VERSION ""

NS_ :

BS_:

BU_: Turbocharger OnBoardDataLogger OffBoardDiagnosticTool2 OffBoardDiagnosticTool1 FileServer ParkingBrakeController SeatControl2 FanDriveController SteeringColumnUnit CommunicationUnitRadio CommunicationUnitSatellite CommunicationUnitCellular PropulsionBatteryCharger ChassisController2 ChassisController1 EngineValveControl AuxiliaryHeater2 AuxiliaryHeater1 ClutchUnit RampControl InformationSystem1 SuspensionSystemController2 OilSensor VehicleDynamicStability ExhaustEmissionController TransmissionDisplay2 TransmissionDisplay1 ClimateControl2 WaterPumpController RearAxleSteeringController LightingOperatorControl SeatController1 IgnitionController2 IgnitionController1 TirePressureController CabController2 CabController1 PneumaticSystemController SuspensionSystemController1 HydraulicPumpController EnduranceBrakingSystem RetarderExhaustEngine2 OnBoardDiagnosticUnit HeadwayController RetarderExhaustEngine1 CabDisplay1 ManagementComputer VirtualTerminal OffVehicleGateway PowerTakeOffFront HitchControl AuxiliaryValveControl BodyController TractorTrailerBridge1 StarterSystem ElectricalSystem VehicleSecurity VehicleNavigation AerodynamicControl ElectricalChargingSystem ClimateControl1 TripRecorder InstrumentCluster SuspensionDriveAxle2 SuspensionDriveAxle1 SuspensionSteerAxle SteeringController FuelSystem CruiseControl RetarderDriveline RetarderEngine BrakesDriveAxle2 BrakesDriveAxle1 BrakesSystemController BrakesSteerAxle AxleDrive2 AxleDrive1 AxleSteering PowerTakeOff ShiftConsoleSecondary ShiftConsolePrimary Transmission2 Transmission1 Engine2 Engine1

BO_ 2633895166 WSMEM: 8 Vector__XXX
 SG_ VehicleSystem5 m5 : 49|7@1+ (1,0) [0|127] "" Vector__XXX
 SG_ VehicleSystem4 m4 : 49|7@1+ (1,0) [0|127] "" Vector__XXX
 SG_ VehicleSystem3 m3 : 49|7@1+ (1,0) [0|127] "" Vector__XXX
 SG_ VehicleSystem2 m2 : 49|7@1+ (1,0) [0|127] "" Vector__XXX
 SG_ VehicleSystem1 m1 : 49|7@1+ (1,0) [0|127] "" Vector__XXX
 SG_ ArbitraryAddressCapable : 63|1@1+ (1,0) [0|1] "" Vector__XXX
 SG_ IndustryGroup M : 60|3@1+ (1,0) [0|7] "" Vector__XXX
 SG_ VehicleSystemInstance : 56|4@1+ (1,0) [0|15] "" Vector__XXX
 SG_ VehicleSystem m0 : 49|7@1+ (1,0) [0|127] "" Vector__XXX
 SG_ ECUInstance : 32|3@1+ (1,0) [0|7] "" Vector__XXX
 SG_ FunctionInstance : 35|5@1+ (1,0) [0|31] "" Vector__XXX
 SG_ Function : 40|8@1+ (1,0) [0|255] "" Vector__XXX
 SG_ ManufacturerCode : 21|11@1+ (1,0) [0|2047] "" Vector__XXX
 SG_ IdentityNumber : 0|21@1+ (1,0) [0|2097152] "" Vector__XXX

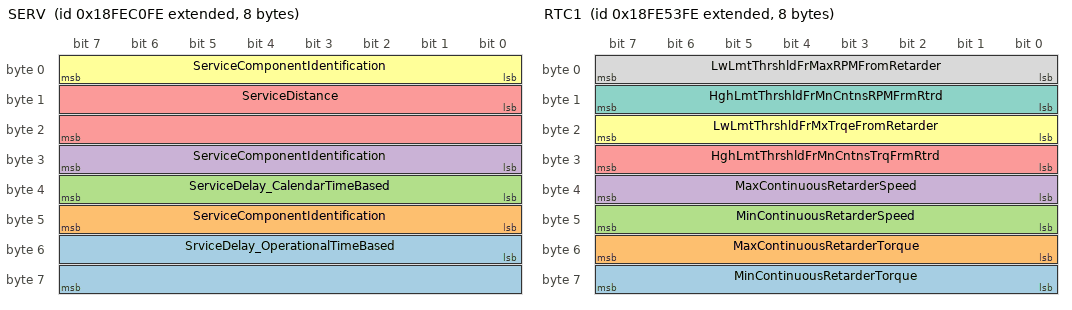
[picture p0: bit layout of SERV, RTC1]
BO_ 2566832382 SERV: 8 Vector__XXX
 SG_ SrviceDelay_OperationalTimeBased : 48|16@1+ (1,-32127) [-32127|32128] "hr" Vector__XXX
 SG_ ServiceComponentIdentification : 40|8@1+ (1,0) [0|250] "ID" Vector__XXX
 SG_ ServiceDelay_CalendarTimeBased : 32|8@1+ (1,-125) [-125|125] "weeks" Vector__XXX
 SG_ ServiceComponentIdentification : 24|8@1+ (1,0) [0|250] "ID" Vector__XXX
 SG_ ServiceDistance : 8|16@1+ (5,-160635) [-160635|160640] "km" Vector__XXX
 SG_ ServiceComponentIdentification : 0|8@1+ (1,0) [0|250] "ID" Vector__XXX

BO_ 2633928446 S2: 8 Vector__XXX
 SG_ TimeSinceLastService : 8|16@1+ (1,-32127) [-32127|32128] "hr" Vector__XXX
 SG_ ServiceComponentIdentification : 0|8@1+ (1,0) [0|250] "ID" Vector__XXX

BO_ 2566804478 RTC1: 8 Vector__XXX
 SG_ MinContinuousRetarderTorque : 56|8@1+ (1,-125) [-125|125] "%" Vector__XXX
 SG_ MaxContinuousRetarderTorque : 48|8@1+ (1,-125) [-125|125] "%" Vector__XXX
 SG_ MinContinuousRetarderSpeed : 40|8@1+ (1,0) [0|8000] "rpm" Vector__XXX
 SG_ MaxContinuousRetarderSpeed : 32|8@1+ (1,0) [0|8000] "rpm" Vector__XXX
 SG_ HghLmtThrshldFrMnCntnsTrqFrmRtrd : 24|8@1+ (1,-125) [-125|125] "%" Vector__XXX
 SG_ LwLmtThrshldFrMxTrqeFromRetarder : 16|8@1+ (1,-125) [-125|125] "%" Vector__XXX
 SG_ HghLmtThrshldFrMnCntnsRPMFrmRtrd : 8|8@1+ (1,0) [0|8000] "rpm" Vector__XXX
 SG_ LwLmtThrshldFrMaxRPMFromRetarder : 0|8@1+ (1,0) [0|8000] "rpm" Vector__XXX

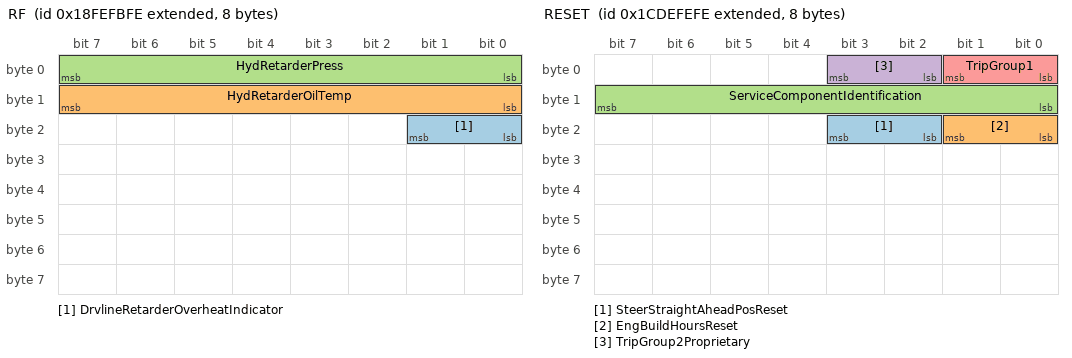
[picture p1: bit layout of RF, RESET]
BO_ 2566847486 RF: 8 Vector__XXX
 SG_ DrvlineRetarderOverheatIndicator : 16|2@1+ (1,0) [0|3] "" Vector__XXX
 SG_ HydRetarderOilTemp : 8|8@1+ (1,-40) [-40|210] "deg C" Vector__XXX
 SG_ HydRetarderPress : 0|8@1+ (16,0) [0|4000] "kPa" Vector__XXX

BO_ 2631859966 RESET: 8 Vector__XXX
 SG_ SteerStraightAheadPosReset : 18|2@1+ (1,0) [0|3] "" Vector__XXX
 SG_ EngBuildHoursReset : 16|2@1+ (1,0) [0|3] "" Vector__XXX
 SG_ ServiceComponentIdentification : 8|8@1+ (1,0) [0|250] "ID" Vector__XXX
 SG_ TripGroup2Proprietary : 2|2@1+ (1,0) [0|3] "" Vector__XXX
 SG_ TripGroup1 : 0|2@1+ (1,0) [0|3] "" Vector__XXX

BO_ 2566840830 RC: 19 Vector__XXX
 SG_ PercentTorqueAtPeakTorquePoint5 : 144|8@1+ (1,-125) [-125|125] "%" Vector__XXX
 SG_ ReferenceRetarderTorque : 128|16@1+ (1,0) [0|64255] "Nm" Vector__XXX
 SG_ RetarderSpeedAtPeakTorquePoint5 : 112|16@1+ (0.125,0) [0|8031.875] "rpm" Vector__XXX
 SG_ PercentTorqueAtPoint4 : 104|8@1+ (1,-125) [-125|125] "%" Vector__XXX
 SG_ RetarderSpeedAtPoint4 : 88|16@1+ (0.125,0) [0|8031.875] "rpm" Vector__XXX
 SG_ PercentTorqueAtPoint3 : 80|8@1+ (1,-125) [-125|125] "%" Vector__XXX
 SG_ RetarderSpeedAtPoint3 : 64|16@1+ (0.125,0) [0|8031.875] "rpm" Vector__XXX
 SG_ PercentTorqueAtMaxSpeedPoint2 : 56|8@1+ (1,-125) [-125|125] "%" Vector__XXX
 SG_ MaxRetarderSpeedPoint2 : 40|16@1+ (0.125,0) [0|8031.875] "rpm" Vector__XXX
 SG_ PercentTorqueAtIdlePoint1 : 32|8@1+ (1,-125) [-125|125] "%" Vector__XXX
 SG_ RetarderSpeedAtIdlePoint1 : 16|16@1+ (0.125,0) [0|8031.875] "rpm" Vector__XXX
 SG_ RetarderCtrlMethod : 8|8@1+ (1,0) [0|250] "steps" Vector__XXX
 SG_ RetarderLocation : 4|4@1+ (1,0) [0|15] "" Vector__XXX
 SG_ RetarderType : 0|4@1+ (1,0) [0|15] "" Vector__XXX

BO_ 2633930238 RBI: 8 Vector__XXX
 SG_ EngOperationTimeSinceRebuild : 0|32@1+ (1,0) [0|4211081215] "s" Vector__XXX

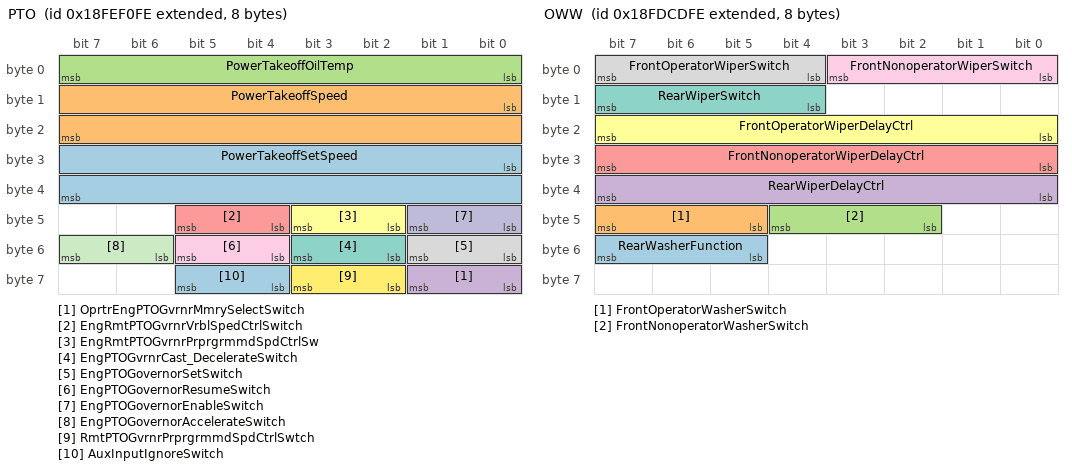
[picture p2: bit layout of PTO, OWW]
BO_ 2566844670 PTO: 8 Vector__XXX
 SG_ PowerTakeoffSetSpeed : 24|16@1+ (0.125,0) [0|8031.875] "rpm" Vector__XXX
 SG_ PowerTakeoffSpeed : 8|16@1+ (0.125,0) [0|8031.875] "rpm" Vector__XXX
 SG_ PowerTakeoffOilTemp : 0|8@1+ (1,-40) [-40|210] "deg C" Vector__XXX
 SG_ OprtrEngPTOGvrnrMmrySelectSwitch : 56|2@1+ (1,0) [0|3] "" Vector__XXX
 SG_ EngRmtPTOGvrnrVrblSpedCtrlSwitch : 44|2@1+ (1,0) [0|3] "" Vector__XXX
 SG_ EngRmtPTOGvrnrPrprgrmmdSpdCtrlSw : 42|2@1+ (1,0) [0|3] "" Vector__XXX
 SG_ EngPTOGvrnrCast_DecelerateSwitch : 50|2@1+ (1,0) [0|3] "" Vector__XXX
 SG_ EngPTOGovernorSetSwitch : 48|2@1+ (1,0) [0|3] "" Vector__XXX
 SG_ EngPTOGovernorResumeSwitch : 52|2@1+ (1,0) [0|3] "" Vector__XXX
 SG_ EngPTOGovernorEnableSwitch : 40|2@1+ (1,0) [0|3] "" Vector__XXX
 SG_ EngPTOGovernorAccelerateSwitch : 54|2@1+ (1,0) [0|3] "" Vector__XXX
 SG_ RmtPTOGvrnrPrprgrmmdSpdCtrlSwtch : 58|2@1+ (1,0) [0|3] "" Vector__XXX
 SG_ AuxInputIgnoreSwitch : 60|2@1+ (1,0) [0|3] "" Vector__XXX

BO_ 2566770174 OWW: 8 Vector__XXX
 SG_ RearWasherFunction : 53|3@1+ (1,0) [0|7] "" Vector__XXX
 SG_ FrontOperatorWasherSwitch : 45|3@1+ (1,0) [0|7] "" Vector__XXX
 SG_ FrontNonoperatorWasherSwitch : 42|3@1+ (1,0) [0|7] "" Vector__XXX
 SG_ RearWiperDelayCtrl : 32|8@1+ (0.4,0) [0|100] "%" Vector__XXX
 SG_ FrontNonoperatorWiperDelayCtrl : 24|8@1+ (0.4,0) [0|100] "%" Vector__XXX
 SG_ FrontOperatorWiperDelayCtrl : 16|8@1+ (0.4,0) [0|100] "%" Vector__XXX
 SG_ RearWiperSwitch : 12|4@1+ (1,0) [0|15] "" Vector__XXX
 SG_ FrontOperatorWiperSwitch : 4|4@1+ (1,0) [0|15] "" Vector__XXX
 SG_ FrontNonoperatorWiperSwitch : 0|4@1+ (1,0) [0|15] "" Vector__XXX

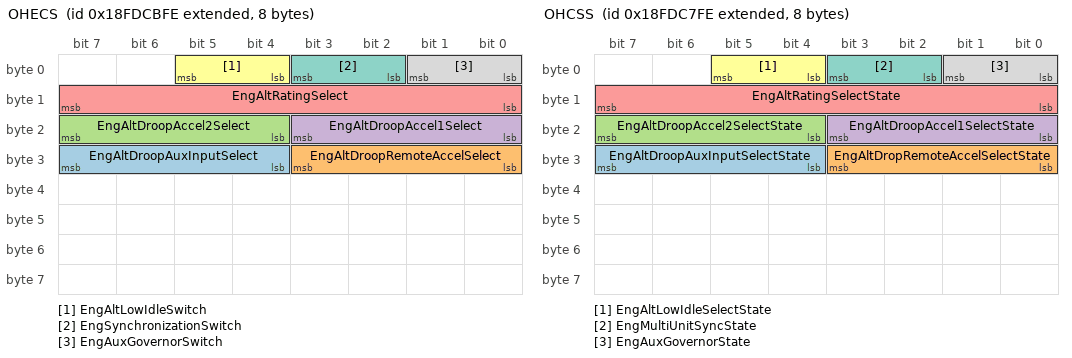
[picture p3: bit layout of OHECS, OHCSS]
BO_ 2566769662 OHECS: 8 Vector__XXX
 SG_ EngAltDroopAuxInputSelect : 28|4@1+ (1,0) [0|15] "" Vector__XXX
 SG_ EngAltDroopRemoteAccelSelect : 24|4@1+ (1,0) [0|15] "" Vector__XXX
 SG_ EngAltDroopAccel2Select : 20|4@1+ (1,0) [0|15] "" Vector__XXX
 SG_ EngAltDroopAccel1Select : 16|4@1+ (1,0) [0|15] "" Vector__XXX
 SG_ EngAltRatingSelect : 8|8@1+ (1.02,0) [0|255] "" Vector__XXX
 SG_ EngAltLowIdleSwitch : 4|2@1+ (1,0) [0|3] "" Vector__XXX
 SG_ EngSynchronizationSwitch : 2|2@1+ (1,0) [0|3] "" Vector__XXX
 SG_ EngAuxGovernorSwitch : 0|2@1+ (1,0) [0|3] "" Vector__XXX

BO_ 2566768638 OHCSS: 8 Vector__XXX
 SG_ EngAltDroopAuxInputSelectState : 28|4@1+ (1,0) [0|15] "" Vector__XXX
 SG_ EngAltDropRemoteAccelSelectState : 24|4@1+ (1,0) [0|15] "" Vector__XXX
 SG_ EngAltDroopAccel2SelectState : 20|4@1+ (1,0) [0|15] "" Vector__XXX
 SG_ EngAltDroopAccel1SelectState : 16|4@1+ (1,0) [0|15] "" Vector__XXX
 SG_ EngAltRatingSelectState : 8|8@1+ (1,0) [0|255] "" Vector__XXX
 SG_ EngAltLowIdleSelectState : 4|2@1+ (1,0) [0|3] "" Vector__XXX
 SG_ EngMultiUnitSyncState : 2|2@1+ (1,0) [0|3] "" Vector__XXX
 SG_ EngAuxGovernorState : 0|2@1+ (1,0) [0|3] "" Vector__XXX

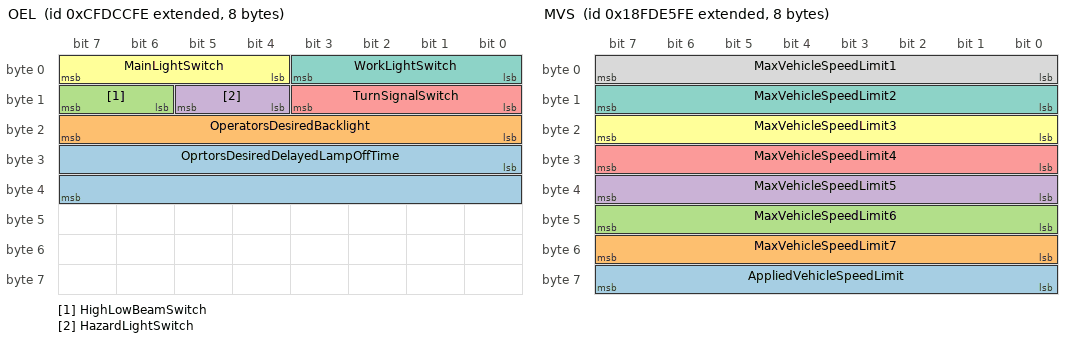
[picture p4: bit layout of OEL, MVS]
BO_ 2365443326 OEL: 8 Vector__XXX
 SG_ OprtorsDesiredDelayedLampOffTime : 24|16@1+ (1,0) [0|64255] "s" Vector__XXX
 SG_ OperatorsDesiredBacklight : 16|8@1+ (0.4,0) [0|100] "%" Vector__XXX
 SG_ HighLowBeamSwitch : 14|2@1+ (1,0) [0|3] "" Vector__XXX
 SG_ HazardLightSwitch : 12|2@1+ (1,0) [0|3] "" Vector__XXX
 SG_ TurnSignalSwitch : 8|4@1+ (1,0) [0|15] "" Vector__XXX
 SG_ MainLightSwitch : 4|4@1+ (1,0) [0|15] "" Vector__XXX
 SG_ WorkLightSwitch : 0|4@1+ (1,0) [0|15] "" Vector__XXX

BO_ 2566776318 MVS: 8 Vector__XXX
 SG_ AppliedVehicleSpeedLimit : 56|8@1+ (1,0) [0|250] "km/h" Vector__XXX
 SG_ MaxVehicleSpeedLimit7 : 48|8@1+ (1,0) [0|250] "km/h" Vector__XXX
 SG_ MaxVehicleSpeedLimit6 : 40|8@1+ (1,0) [0|250] "km/h" Vector__XXX
 SG_ MaxVehicleSpeedLimit5 : 32|8@1+ (1,0) [0|250] "km/h" Vector__XXX
 SG_ MaxVehicleSpeedLimit4 : 24|8@1+ (1,0) [0|250] "km/h" Vector__XXX
 SG_ MaxVehicleSpeedLimit3 : 16|8@1+ (1,0) [0|250] "km/h" Vector__XXX
 SG_ MaxVehicleSpeedLimit2 : 8|8@1+ (1,0) [0|250] "km/h" Vector__XXX
 SG_ MaxVehicleSpeedLimit1 : 0|8@1+ (1,0) [0|250] "km/h" Vector__XXX

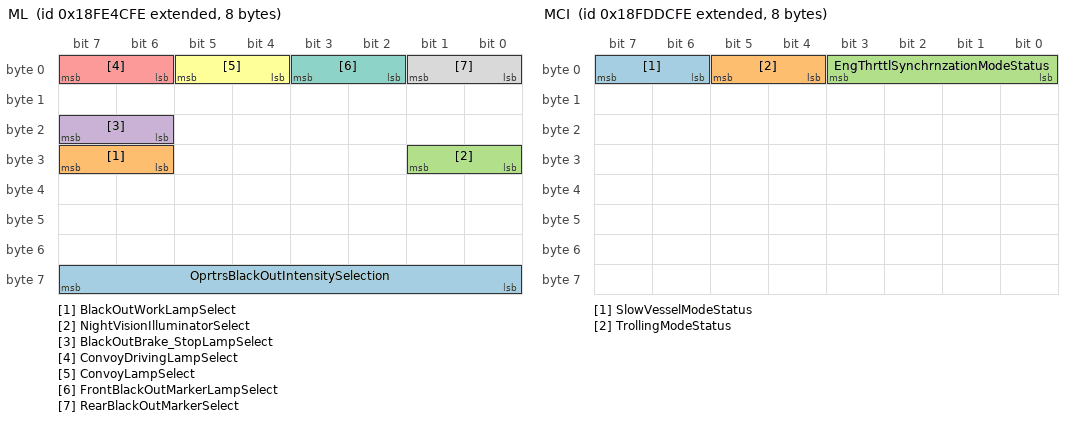
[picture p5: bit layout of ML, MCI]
BO_ 2566802686 ML: 8 Vector__XXX
 SG_ OprtrsBlackOutIntensitySelection : 56|8@1+ (1,0) [0|100] "%" Vector__XXX
 SG_ BlackOutWorkLampSelect : 30|2@1+ (1,0) [0|3] "" Vector__XXX
 SG_ NightVisionIlluminatorSelect : 24|2@1+ (1,0) [0|3] "" Vector__XXX
 SG_ BlackOutBrake_StopLampSelect : 22|2@1+ (1,0) [0|3] "" Vector__XXX
 SG_ ConvoyDrivingLampSelect : 6|2@1+ (1,0) [0|3] "" Vector__XXX
 SG_ ConvoyLampSelect : 4|2@1+ (1,0) [0|3] "" Vector__XXX
 SG_ FrontBlackOutMarkerLampSelect : 2|2@1+ (1,0) [0|3] "" Vector__XXX
 SG_ RearBlackOutMarkerSelect : 0|2@1+ (1,0) [0|3] "" Vector__XXX

BO_ 2566774014 MCI: 8 Vector__XXX
 SG_ SlowVesselModeStatus : 6|2@1+ (1,0) [0|3] "" Vector__XXX
 SG_ TrollingModeStatus : 4|2@1+ (1,0) [0|3] "" Vector__XXX
 SG_ EngThrttlSynchrnzationModeStatus : 0|4@1+ (1,0) [0|15] "" Vector__XXX

BO_ 2566823166 MBT3: 8 Vector__XXX
 SG_ EngMainBearing11Temp : 32|16@1+ (0.03125,-273) [-273|1734.96875] "deg C" Vector__XXX
 SG_ EngMainBearing10Temp : 16|16@1+ (0.03125,-273) [-273|1734.96875] "deg C" Vector__XXX
 SG_ EngMainBearing9Temp : 0|16@1+ (0.03125,-273) [-273|1734.96875] "deg C" Vector__XXX

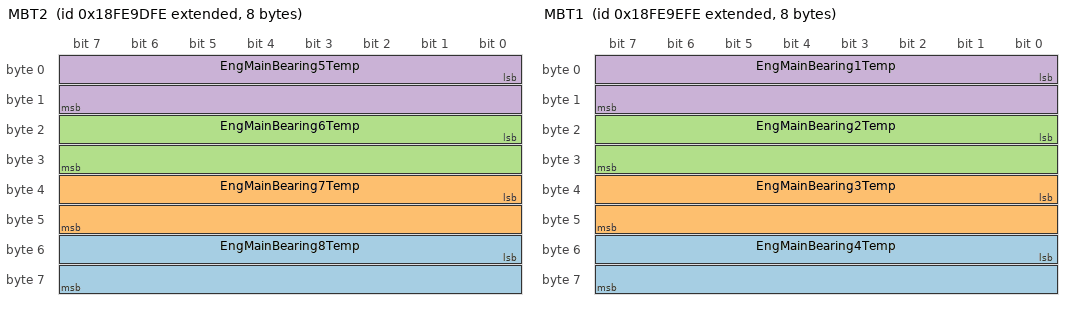
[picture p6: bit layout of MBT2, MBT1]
BO_ 2566823422 MBT2: 8 Vector__XXX
 SG_ EngMainBearing8Temp : 48|16@1+ (0.03125,-273) [-273|1734.96875] "deg C" Vector__XXX
 SG_ EngMainBearing7Temp : 32|16@1+ (0.03125,-273) [-273|1734.96875] "deg C" Vector__XXX
 SG_ EngMainBearing6Temp : 16|16@1+ (0.03125,-273) [-273|1734.96875] "deg C" Vector__XXX
 SG_ EngMainBearing5Temp : 0|16@1+ (0.03125,-273) [-273|1734.96875] "deg C" Vector__XXX

BO_ 2566823678 MBT1: 8 Vector__XXX
 SG_ EngMainBearing4Temp : 48|16@1+ (0.03125,-273) [-273|1734.96875] "deg C" Vector__XXX
 SG_ EngMainBearing3Temp : 32|16@1+ (0.03125,-273) [-273|1734.96875] "deg C" Vector__XXX
 SG_ EngMainBearing2Temp : 16|16@1+ (0.03125,-273) [-273|1734.96875] "deg C" Vector__XXX
 SG_ EngMainBearing1Temp : 0|16@1+ (0.03125,-273) [-273|1734.96875] "deg C" Vector__XXX

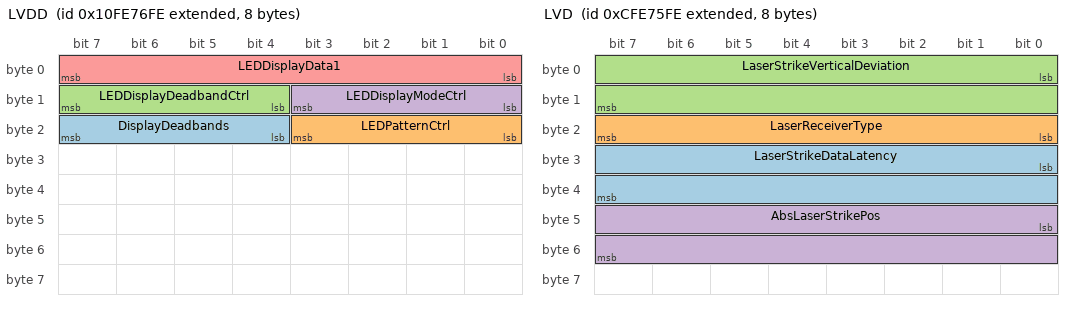
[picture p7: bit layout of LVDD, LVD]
BO_ 2432595710 LVDD: 8 Vector__XXX
 SG_ DisplayDeadbands : 20|4@1+ (1,0) [0|15] "" Vector__XXX
 SG_ LEDPatternCtrl : 16|4@1+ (1,0) [0|15] "" Vector__XXX
 SG_ LEDDisplayDeadbandCtrl : 12|4@1+ (1,0) [0|15] "" Vector__XXX
 SG_ LEDDisplayModeCtrl : 8|4@1+ (1,0) [0|15] "" Vector__XXX
 SG_ LEDDisplayData1 : 0|8@1+ (1,0) [0|255] "" Vector__XXX

BO_ 2365486590 LVD: 8 Vector__XXX
 SG_ LaserStrikeDataLatency : 24|16@1+ (5.12E-005,0) [0|3.289856] "s" Vector__XXX
 SG_ LaserReceiverType : 16|8@1+ (1,0) [0|250] "" Vector__XXX
 SG_ LaserStrikeVerticalDeviation : 0|16@1+ (0.1,-3200) [-3200|3225.5] "mm" Vector__XXX
 SG_ AbsLaserStrikePos : 40|16@1+ (0.1,0) [0|6425.5] "mm" Vector__XXX

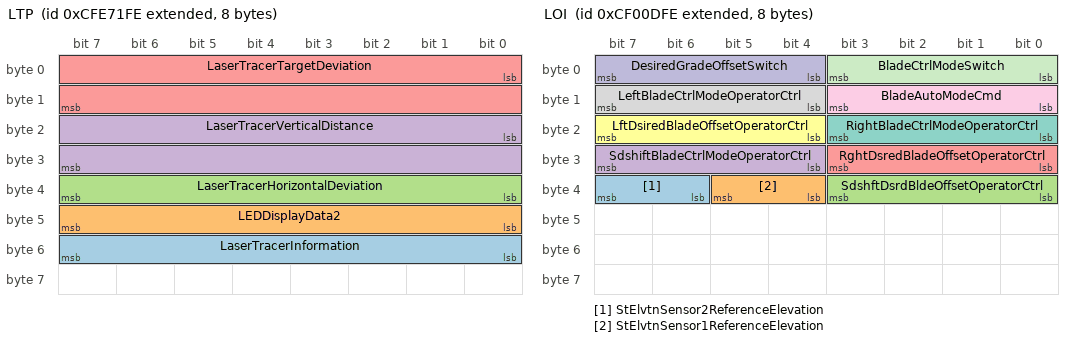
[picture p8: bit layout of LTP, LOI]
BO_ 2365485566 LTP: 8 Vector__XXX
 SG_ LaserTracerInformation : 48|8@1+ (1,0) [0|255] "" Vector__XXX
 SG_ LEDDisplayData2 : 40|8@1+ (1,0) [0|255] "" Vector__XXX
 SG_ LaserTracerHorizontalDeviation : 32|8@1+ (1,0) [0|250] "%" Vector__XXX
 SG_ LaserTracerVerticalDistance : 16|16@1+ (0.1,0) [0|6425.5] "mm" Vector__XXX
 SG_ LaserTracerTargetDeviation : 0|16@1+ (0.1,-3200) [-3200|3225.5] "mm" Vector__XXX

BO_ 2633939454 LTFI: 22 Vector__XXX
 SG_ TripCruiseFuelUsed : 128|32@1+ (0.5,0) [0|2105540607.5] "L" Vector__XXX
 SG_ TripVehicleIdleFuelUsed : 96|32@1+ (0.5,0) [0|2105540607.5] "L" Vector__XXX
 SG_ TripDriveFuelUsed : 0|32@1+ (0.5,0) [0|2105540607.5] "L" Vector__XXX
 SG_ TripPTOGovernorNonmovingFuelUsed : 64|32@1+ (0.5,0) [0|2105540607.5] "L" Vector__XXX
 SG_ TripPTOGovernorMovingFuelUsed : 32|32@1+ (0.5,0) [0|2105540607.5] "L" Vector__XXX
 SG_ TripDriveFuelEconomy : 160|16@1+ (0.0019531553964672,0) [0|125.5] "km/L" Vector__XXX

BO_ 2365486334 LSP: 8 Vector__XXX
 SG_ BldeHeightSetPointHighResolution : 16|32@1+ (1E-007,-209.7152) [-209.7152|211.3929215] "m" Vector__XXX
 SG_ ModifyLevelingSystemSetPoint : 0|16@1+ (0.1,-3200) [-3200|3225.5] "mm" Vector__XXX

BO_ 2364542462 LOI: 8 Vector__XXX
 SG_ StElvtnSensor2ReferenceElevation : 38|2@1+ (1,0) [0|3] "" Vector__XXX
 SG_ StElvtnSensor1ReferenceElevation : 36|2@1+ (1,0) [0|3] "" Vector__XXX
 SG_ SdshftDsrdBldeOffsetOperatorCtrl : 32|4@1+ (1,0) [0|15] "" Vector__XXX
 SG_ SdshiftBladeCtrlModeOperatorCtrl : 28|4@1+ (1,0) [0|15] "" Vector__XXX
 SG_ RghtDsredBladeOffsetOperatorCtrl : 24|4@1+ (1,0) [0|15] "" Vector__XXX
 SG_ LftDsiredBladeOffsetOperatorCtrl : 20|4@1+ (1,0) [0|15] "" Vector__XXX
 SG_ RightBladeCtrlModeOperatorCtrl : 16|4@1+ (1,0) [0|15] "" Vector__XXX
 SG_ LeftBladeCtrlModeOperatorCtrl : 12|4@1+ (1,0) [0|15] "" Vector__XXX
 SG_ BladeAutoModeCmd : 8|4@1+ (1,0) [0|15] "" Vector__XXX
 SG_ DesiredGradeOffsetSwitch : 4|4@1+ (1,0) [0|15] "" Vector__XXX
 SG_ BladeCtrlModeSwitch : 0|4@1+ (1,0) [0|0] "" Vector__XXX

BO_ 2365486078 LMP: 8 Vector__XXX
 SG_ MastPos : 0|16@1+ (0.1,-3200) [-3200|3225.5] "mm" Vector__XXX

BO_ 2633937918 LFI: 8 Vector__XXX
 SG_ FlexibleFuelPercentage : 48|10@1+ (1,0) [0|102] "%" Vector__XXX
 SG_ TripAverageFuelRate : 32|16@1+ (0.05,0) [0|3212.75] "L/h" Vector__XXX
 SG_ TotalEngPTOGovernorFuelUsed : 0|32@1+ (0.5,0) [0|2105540607.5] "L" Vector__XXX

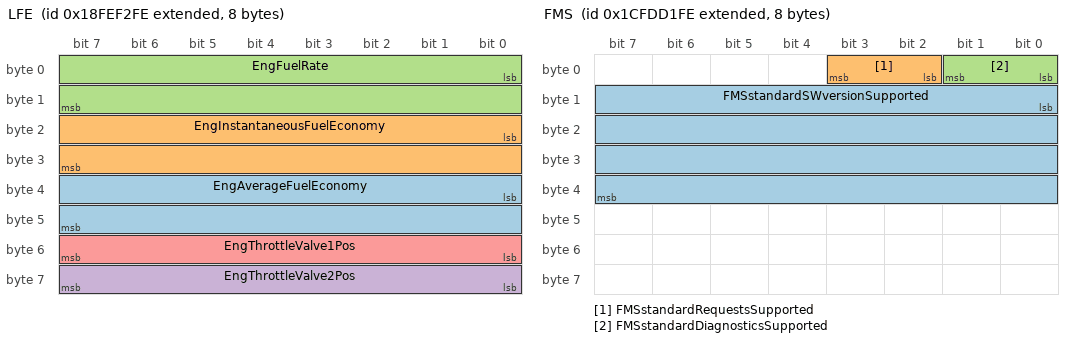
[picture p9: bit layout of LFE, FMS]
BO_ 2566845182 LFE: 8 Vector__XXX
 SG_ EngAverageFuelEconomy : 32|16@1+ (0.0019531553964672,0) [0|125.5] "km/L" Vector__XXX
 SG_ EngInstantaneousFuelEconomy : 16|16@1+ (0.0019531553964672,0) [0|125.5] "km/L" Vector__XXX
 SG_ EngFuelRate : 0|16@1+ (0.05,0) [0|3212.75] "L/h" Vector__XXX
 SG_ EngThrottleValve2Pos : 56|8@1+ (0.4,0) [0|100] "%" Vector__XXX
 SG_ EngThrottleValve1Pos : 48|8@1+ (0.4,0) [0|100] "%" Vector__XXX

BO_ 2566842878 LFC: 8 Vector__XXX
 SG_ EngTotalFuelUsed : 32|32@1+ (0.5,0) [0|2105540607.5] "L" Vector__XXX
 SG_ EngTripFuel : 0|32@1+ (0.5,0) [0|2105540607.5] "L" Vector__XXX

BO_ 2633883646 FWD: 8 Vector__XXX
 SG_ FrontWheelDriveActuatorStatus : 0|2@1+ (1,0) [0|3] "" Vector__XXX

BO_ 2633880062 FMS: 8 Vector__XXX
 SG_ FMSstandardSWversionSupported : 8|32@1+ (6.0554519606908E-008,0) [0|255] "per byte" Vector__XXX
 SG_ FMSstandardRequestsSupported : 2|2@1+ (1,0) [0|3] "" Vector__XXX
 SG_ FMSstandardDiagnosticsSupported : 0|2@1+ (1,0) [0|3] "" Vector__XXX

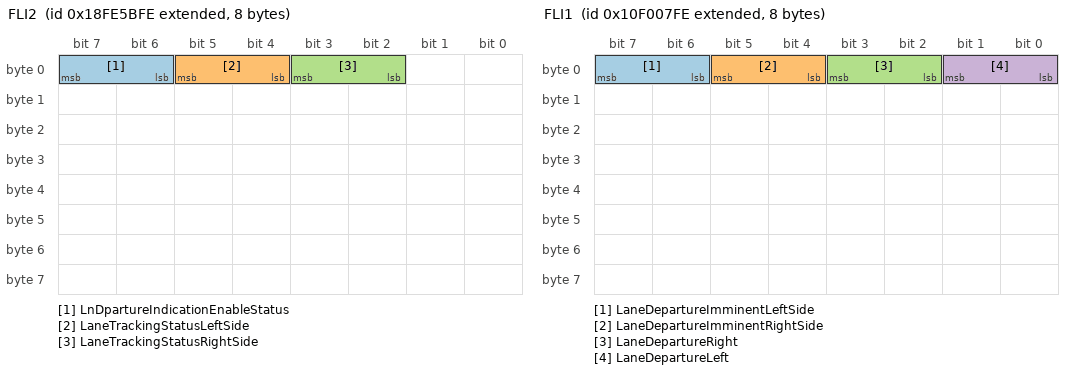
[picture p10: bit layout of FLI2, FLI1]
BO_ 2566806526 FLI2: 8 Vector__XXX
 SG_ LnDpartureIndicationEnableStatus : 6|2@1+ (1,0) [0|3] "" Vector__XXX
 SG_ LaneTrackingStatusLeftSide : 4|2@1+ (1,0) [0|3] "" Vector__XXX
 SG_ LaneTrackingStatusRightSide : 2|2@1+ (1,0) [0|3] "" Vector__XXX

BO_ 2431649790 FLI1: 8 Vector__XXX
 SG_ LaneDepartureImminentLeftSide : 6|2@1+ (1,0) [0|3] "" Vector__XXX
 SG_ LaneDepartureImminentRightSide : 4|2@1+ (1,0) [0|3] "" Vector__XXX
 SG_ LaneDepartureRight : 2|2@1+ (1,0) [0|3] "" Vector__XXX
 SG_ LaneDepartureLeft : 0|2@1+ (1,0) [0|3] "" Vector__XXX

BO_ 2633929214 FL: 8 Vector__XXX
 SG_ EngFuelLeakage2 : 2|2@1+ (1,0) [0|3] "" Vector__XXX
 SG_ EngFuelLeakage1 : 0|2@1+ (1,0) [0|3] "" Vector__XXX

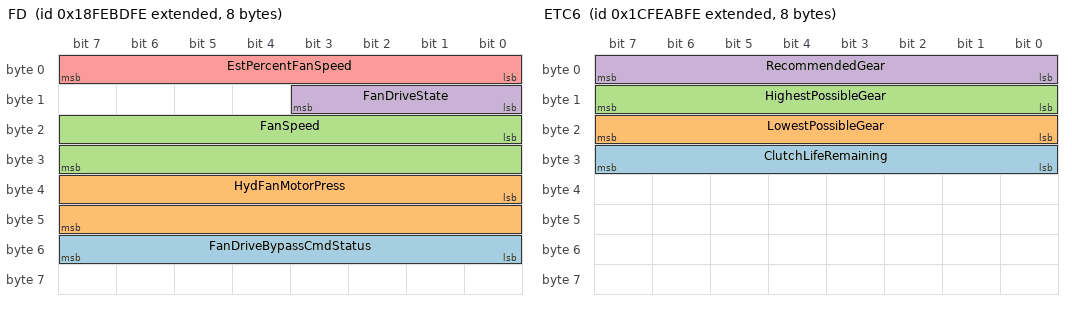
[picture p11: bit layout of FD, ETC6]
BO_ 2566831614 FD: 8 Vector__XXX
 SG_ FanDriveBypassCmdStatus : 48|8@1+ (1,0) [0|100] "%" Vector__XXX
 SG_ HydFanMotorPress : 32|16@1+ (0.5,0) [0|32127.5] "kPa" Vector__XXX
 SG_ FanSpeed : 16|16@1+ (0.125,0) [0|8031.875] "rpm" Vector__XXX
 SG_ FanDriveState : 8|4@1+ (1,0) [0|15] "" Vector__XXX
 SG_ EstPercentFanSpeed : 0|8@1+ (1,0) [0|100] "%" Vector__XXX

BO_ 2566820094 ETH: 33 Vector__XXX
 SG_ EngTorqueLimit6AxleInput : 248|16@1+ (2,0) [0|128510] "Nm" Vector__XXX
 SG_ EngTorqueLimit5Switch : 232|16@1+ (1,0) [0|64255] "Nm" Vector__XXX
 SG_ EngTorqueLimit4Trans : 216|16@1+ (1,0) [0|64255] "Nm" Vector__XXX
 SG_ EngTorqueLimit3Trans : 200|16@1+ (1,0) [0|64255] "Nm" Vector__XXX
 SG_ TransGearRatio3 : 184|16@1+ (0.01,0) [0|642.55] "" Vector__XXX
 SG_ EngTorqueLimit2Trans : 168|16@1+ (1,0) [0|64255] "Nm" Vector__XXX
 SG_ TransGearRatio2 : 152|16@1+ (0.01,0) [0|642.55] "" Vector__XXX
 SG_ EngTorqueLimit1Trans : 136|16@1+ (1,0) [0|64255] "Nm" Vector__XXX
 SG_ TransGearRatio1 : 120|16@1+ (0.01,0) [0|642.55] "" Vector__XXX
 SG_ EngTorqueLimitFeature : 114|3@1+ (1,0) [0|7] "" Vector__XXX
 SG_ TorqueLimitingFeatureStatus : 112|2@1+ (1,0) [0|3] "" Vector__XXX
 SG_ CalibRecordDurationTime : 80|32@1+ (0.05,0) [0|210554060.75] "hr" Vector__XXX
 SG_ CalibRecordStartYear : 72|8@1+ (1,1985) [1985|2235] "years" Vector__XXX
 SG_ CalibRecordStartDay : 64|8@1+ (0.25,0) [0|62.5] "days" Vector__XXX
 SG_ CalibRecordStartMonth : 56|8@1+ (1,0) [0|250] "months" Vector__XXX
 SG_ EngPeakTorque2 : 40|16@1+ (1,0) [0|64255] "Nm" Vector__XXX
 SG_ EngPeakTorque1 : 24|16@1+ (1,0) [0|64255] "Nm" Vector__XXX
 SG_ EngPower : 8|16@1+ (0.5,0) [0|32127.5] "kW" Vector__XXX
 SG_ NumberOfEngTorqueHistoryRecords : 0|8@1+ (1,0) [0|250] "records" Vector__XXX

BO_ 2364542206 ETC8: 8 Vector__XXX
 SG_ TransClutch_ConverterInputSpeed : 16|16@1+ (0.125,0) [0|8031.875] "rpm" Vector__XXX
 SG_ TransTorqueConverterRatio : 0|16@1+ (0.001,0) [0|64.255] "" Vector__XXX

BO_ 2566802174 ETC7: 8 Vector__XXX
 SG_ TrnsRverseGearShiftInhibitStatus : 40|2@1+ (1,0) [0|3] "" Vector__XXX
 SG_ TrnsCrrentRangeDisplayBlankState : 0|2@1+ (1,0) [0|3] "" Vector__XXX
 SG_ TransWarningIndicator : 42|2@1+ (1,0) [0|3] "" Vector__XXX
 SG_ TransMode8Indicator : 38|2@1+ (1,0) [0|3] "" Vector__XXX
 SG_ TransMode7Indicator : 36|2@1+ (1,0) [0|3] "" Vector__XXX
 SG_ TransMode6Indicator : 34|2@1+ (1,0) [0|3] "" Vector__XXX
 SG_ TransMode5Indicator : 32|2@1+ (1,0) [0|3] "" Vector__XXX
 SG_ TransRequestedGearFeedback : 24|8@1+ (1,-125) [-125|125] "" Vector__XXX
 SG_ TransMode1Indicator : 22|2@1+ (1,0) [0|3] "" Vector__XXX
 SG_ TransMode2Indicator : 20|2@1+ (1,0) [0|3] "" Vector__XXX
 SG_ TransMode3Indicator : 18|2@1+ (1,0) [0|3] "" Vector__XXX
 SG_ TransMode4Indicator : 16|2@1+ (1,0) [0|3] "" Vector__XXX
 SG_ TransShiftInhibitIndicator : 14|2@1+ (1,0) [0|3] "" Vector__XXX
 SG_ TransEngCrankEnable : 12|2@1+ (1,0) [0|3] "" Vector__XXX
 SG_ ActiveShiftConsoleIndicator : 10|2@1+ (1,0) [0|3] "" Vector__XXX
 SG_ TransReadyForBrakeRelease : 8|2@1+ (1,0) [0|3] "" Vector__XXX
 SG_ TrnsRqstedRangeDisplayFlashState : 6|2@1+ (1,0) [0|3] "" Vector__XXX
 SG_ TrnsRqstedRangeDisplayBlankState : 4|2@1+ (1,0) [0|3] "" Vector__XXX
 SG_ TransServiceIndicator : 2|2@1+ (1,0) [0|3] "" Vector__XXX

BO_ 2633935870 ETC6: 8 Vector__XXX
 SG_ ClutchLifeRemaining : 24|8@1+ (0.4,0) [0|100] "%" Vector__XXX
 SG_ LowestPossibleGear : 16|8@1+ (1,-125) [-125|125] "" Vector__XXX
 SG_ HighestPossibleGear : 8|8@1+ (1,-125) [-125|125] "" Vector__XXX
 SG_ RecommendedGear : 0|8@1+ (1,-125) [-125|125] "" Vector__XXX

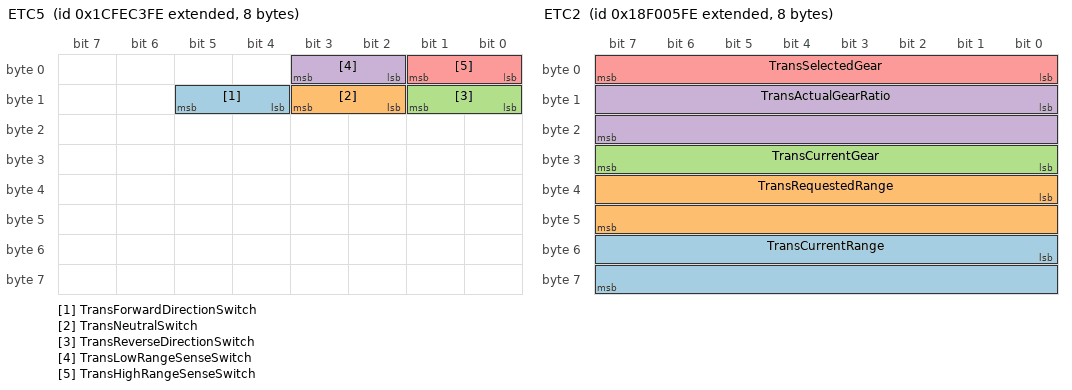
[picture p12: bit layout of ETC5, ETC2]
BO_ 2633942014 ETC5: 8 Vector__XXX
 SG_ TransForwardDirectionSwitch : 12|2@1+ (1,0) [0|3] "" Vector__XXX
 SG_ TransNeutralSwitch : 10|2@1+ (1,0) [0|3] "" Vector__XXX
 SG_ TransReverseDirectionSwitch : 8|2@1+ (1,0) [0|3] "" Vector__XXX
 SG_ TransLowRangeSenseSwitch : 2|2@1+ (1,0) [0|3] "" Vector__XXX
 SG_ TransHighRangeSenseSwitch : 0|2@1+ (1,0) [0|3] "" Vector__XXX

BO_ 2633942526 ETC4: 8 Vector__XXX
 SG_ TransSynchronizerBrakeValue : 8|8@1+ (0.4,0) [0|100] "%" Vector__XXX
 SG_ TransSynchronizerClutchValue : 0|8@1+ (0.4,0) [0|100] "%" Vector__XXX

BO_ 2633943038 ETC3: 8 Vector__XXX
 SG_ TransInertiaBrakeActuator : 46|2@1+ (1,0) [0|3] "" Vector__XXX
 SG_ TransDefuelActuator : 44|2@1+ (1,0) [0|3] "" Vector__XXX
 SG_ TransLockupClutchActuator : 42|2@1+ (1,0) [0|3] "" Vector__XXX
 SG_ TransClutchActuator : 40|2@1+ (1,0) [0|3] "" Vector__XXX
 SG_ TransSplitterIndirectActuator : 38|2@1+ (1,0) [0|3] "" Vector__XXX
 SG_ TransSplitterDirectActuator : 36|2@1+ (1,0) [0|3] "" Vector__XXX
 SG_ TransRangeLowActuator : 34|2@1+ (1,0) [0|3] "" Vector__XXX
 SG_ TransRangeHighActuator : 32|2@1+ (1,0) [0|3] "" Vector__XXX
 SG_ TransShiftFingerGearActuator2 : 30|2@1+ (1,0) [0|3] "" Vector__XXX
 SG_ TransShiftFingerRailActuator2 : 28|2@1+ (1,0) [0|3] "" Vector__XXX
 SG_ TransShiftFingerGearActuator1 : 26|2@1+ (1,0) [0|3] "" Vector__XXX
 SG_ TransShiftFingerRailActuator1 : 24|2@1+ (1,0) [0|3] "" Vector__XXX
 SG_ TrnsShftFngerCenterRailIndicator : 20|2@1+ (1,0) [0|3] "" Vector__XXX
 SG_ TrnsShftFngerEngagementIndicator : 18|2@1+ (1,0) [0|3] "" Vector__XXX
 SG_ TransShiftFingerNeutralIndicator : 16|2@1+ (1,0) [0|3] "" Vector__XXX
 SG_ TransShiftFingerRailPos : 8|8@1+ (0.4,0) [0|100] "%" Vector__XXX
 SG_ TransShiftFingerGearPos : 0|8@1+ (0.4,0) [0|100] "%" Vector__XXX

BO_ 2565867006 ETC2: 8 Vector__XXX
 SG_ TransCurrentRange : 48|16@1+ (1,0) [0|255] "per byte" Vector__XXX
 SG_ TransRequestedRange : 32|16@1+ (1,0) [0|255] "per byte" Vector__XXX
 SG_ TransCurrentGear : 24|8@1+ (1,-125) [-125|125] "" Vector__XXX
 SG_ TransActualGearRatio : 8|16@1+ (0.001,0) [0|64.255] "" Vector__XXX
 SG_ TransSelectedGear : 0|8@1+ (1,-125) [-125|125] "" Vector__XXX

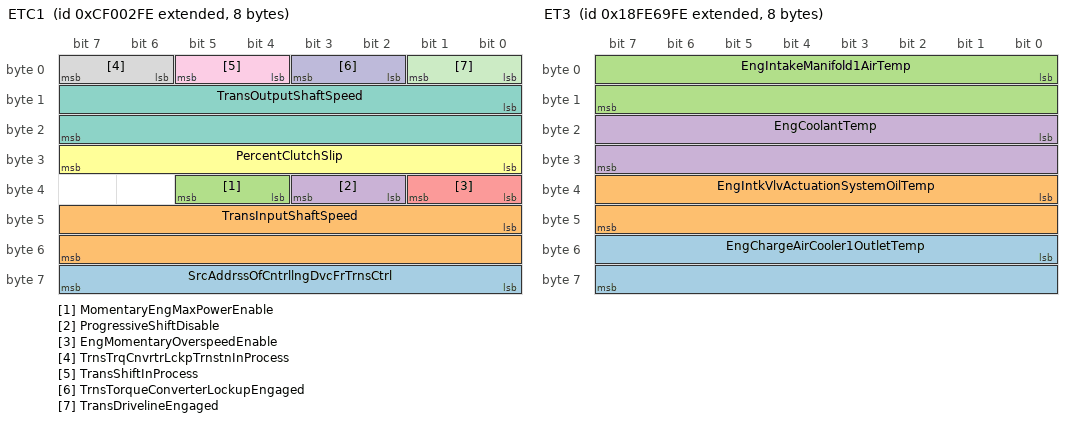
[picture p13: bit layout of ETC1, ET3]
BO_ 2364539646 ETC1: 8 Vector__XXX
 SG_ SrcAddrssOfCntrllngDvcFrTrnsCtrl : 56|8@1+ (1,0) [0|255] "" Vector__XXX
 SG_ TransInputShaftSpeed : 40|16@1+ (0.125,0) [0|8031.875] "rpm" Vector__XXX
 SG_ MomentaryEngMaxPowerEnable : 36|2@1+ (1,0) [0|3] "" Vector__XXX
 SG_ ProgressiveShiftDisable : 34|2@1+ (1,0) [0|3] "" Vector__XXX
 SG_ EngMomentaryOverspeedEnable : 32|2@1+ (1,0) [0|3] "" Vector__XXX
 SG_ PercentClutchSlip : 24|8@1+ (0.4,0) [0|100] "%" Vector__XXX
 SG_ TransOutputShaftSpeed : 8|16@1+ (0.125,0) [0|8031.875] "rpm" Vector__XXX
 SG_ TrnsTrqCnvrtrLckpTrnstnInProcess : 6|2@1+ (1,0) [0|3] "" Vector__XXX
 SG_ TransShiftInProcess : 4|2@1+ (1,0) [0|3] "" Vector__XXX
 SG_ TrnsTorqueConverterLockupEngaged : 2|2@1+ (1,0) [0|3] "" Vector__XXX
 SG_ TransDrivelineEngaged : 0|2@1+ (1,0) [0|3] "" Vector__XXX

BO_ 2566810110 ET3: 8 Vector__XXX
 SG_ EngChargeAirCooler1OutletTemp : 48|16@1+ (0.03125,-273) [-273|1734.96875] "deg C" Vector__XXX
 SG_ EngIntkVlvActuationSystemOilTemp : 32|16@1+ (0.03125,-273) [-273|1734.96875] "deg C" Vector__XXX
 SG_ EngIntakeManifold1AirTemp : 0|16@1+ (0.03125,-273) [-273|1734.96875] "deg C" Vector__XXX
 SG_ EngCoolantTemp : 16|16@1+ (0.03125,-273) [-273|1734.96875] "deg C" Vector__XXX

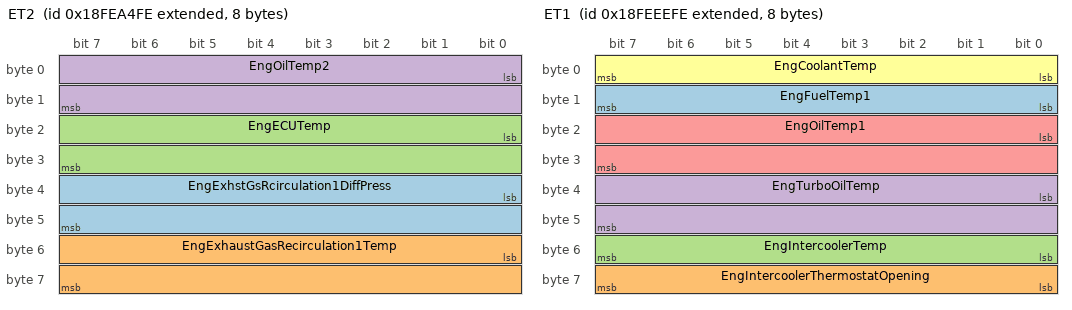
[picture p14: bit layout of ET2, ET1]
BO_ 2566825214 ET2: 8 Vector__XXX
 SG_ EngExhstGsRcirculation1DiffPress : 32|16@1+ (0.0078124659559567,-250) [-250|251.99] "kPa" Vector__XXX
 SG_ EngExhaustGasRecirculation1Temp : 48|16@1+ (0.03125,-273) [-273|1734.96875] "deg C" Vector__XXX
 SG_ EngECUTemp : 16|16@1+ (0.03125,-273) [-273|1734.96875] "deg C" Vector__XXX
 SG_ EngOilTemp2 : 0|16@1+ (0.03125,-273) [-273|1734.96875] "deg C" Vector__XXX

BO_ 2566844158 ET1: 8 Vector__XXX
 SG_ EngFuelTemp1 : 8|8@1+ (1,-40) [-40|210] "deg C" Vector__XXX
 SG_ EngIntercoolerThermostatOpening : 56|8@1+ (0.4,0) [0|100] "%" Vector__XXX
 SG_ EngIntercoolerTemp : 48|8@1+ (1,-40) [-40|210] "deg C" Vector__XXX
 SG_ EngTurboOilTemp : 32|16@1+ (0.03125,-273) [-273|1734.96875] "deg C" Vector__XXX
 SG_ EngOilTemp1 : 16|16@1+ (0.03125,-273) [-273|1734.96875] "deg C" Vector__XXX
 SG_ EngCoolantTemp : 0|8@1+ (1,-40) [-40|210] "deg C" Vector__XXX

BO_ 2566785022 ET: 8 Vector__XXX
 SG_ EngExhaustGasTempLeftManifold : 16|16@1+ (0.03125,-273) [-273|1734.96875] "deg C" Vector__XXX
 SG_ EngExhaustGasTempRightManifold : 0|16@1+ (0.03125,-273) [-273|1734.96875] "deg C" Vector__XXX

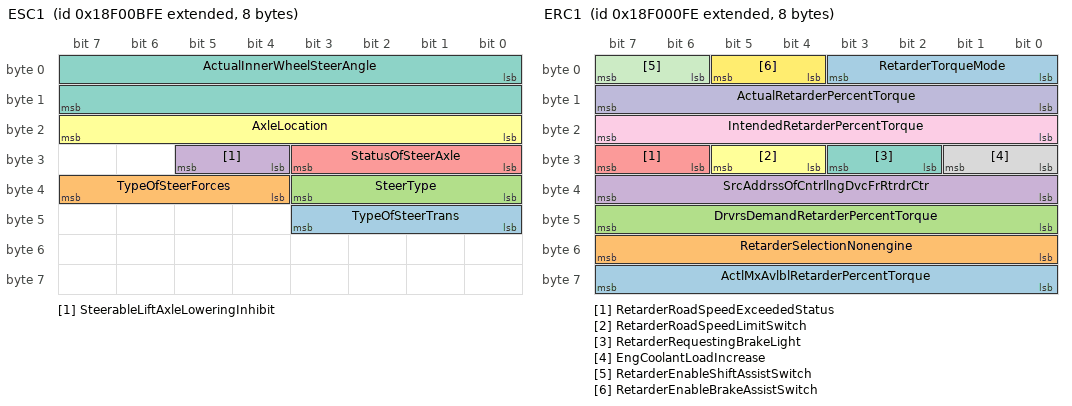
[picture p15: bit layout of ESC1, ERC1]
BO_ 2565868542 ESC1: 8 Vector__XXX
 SG_ TypeOfSteerTrans : 40|4@1+ (1,0) [0|15] "" Vector__XXX
 SG_ TypeOfSteerForces : 36|4@1+ (1,0) [0|15] "" Vector__XXX
 SG_ SteerType : 32|4@1+ (1,0) [0|15] "" Vector__XXX
 SG_ SteerableLiftAxleLoweringInhibit : 28|2@1+ (1,0) [0|3] "" Vector__XXX
 SG_ StatusOfSteerAxle : 24|4@1+ (1,0) [0|15] "" Vector__XXX
 SG_ AxleLocation : 16|8@1+ (1.02,0) [0|255] "" Vector__XXX
 SG_ ActualInnerWheelSteerAngle : 0|16@1+ (0.0038907478017275,-125) [-125|125] "deg" Vector__XXX

BO_ 2633941758 ERC2: 8 Vector__XXX
 SG_ TransOutputRetarder : 0|2@1+ (1,0) [0|3] "" Vector__XXX

BO_ 2565865726 ERC1: 8 Vector__XXX
 SG_ ActlMxAvlblRetarderPercentTorque : 56|8@1+ (1,-125) [-125|125] "%" Vector__XXX
 SG_ RetarderSelectionNonengine : 48|8@1+ (0.4,0) [0|100] "%" Vector__XXX
 SG_ DrvrsDemandRetarderPercentTorque : 40|8@1+ (1,-125) [-125|125] "%" Vector__XXX
 SG_ SrcAddrssOfCntrllngDvcFrRtrdrCtr : 32|8@1+ (1,0) [0|255] "" Vector__XXX
 SG_ RetarderRoadSpeedExceededStatus : 30|2@1+ (1,0) [0|3] "" Vector__XXX
 SG_ RetarderRoadSpeedLimitSwitch : 28|2@1+ (1,0) [0|3] "" Vector__XXX
 SG_ RetarderRequestingBrakeLight : 26|2@1+ (1,0) [0|3] "" Vector__XXX
 SG_ EngCoolantLoadIncrease : 24|2@1+ (1,0) [0|3] "" Vector__XXX
 SG_ IntendedRetarderPercentTorque : 16|8@1+ (1,-125) [-125|125] "%" Vector__XXX
 SG_ ActualRetarderPercentTorque : 8|8@1+ (1,-125) [-125|125] "%" Vector__XXX
 SG_ RetarderEnableShiftAssistSwitch : 6|2@1+ (1,0) [0|3] "" Vector__XXX
 SG_ RetarderEnableBrakeAssistSwitch : 4|2@1+ (1,0) [0|3] "" Vector__XXX
 SG_ RetarderTorqueMode : 0|4@1+ (1,0) [0|15] "" Vector__XXX

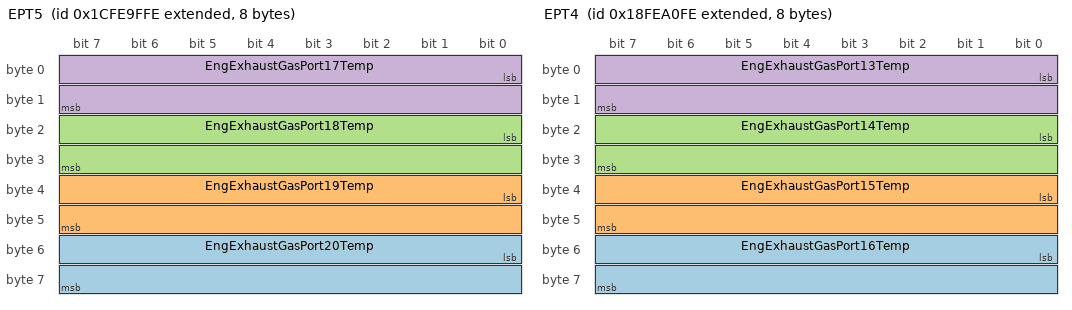
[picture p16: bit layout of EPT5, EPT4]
BO_ 2633932798 EPT5: 8 Vector__XXX
 SG_ EngExhaustGasPort20Temp : 48|16@1+ (0.03125,-273) [-273|1734.96875] "deg C" Vector__XXX
 SG_ EngExhaustGasPort19Temp : 32|16@1+ (0.03125,-273) [-273|1734.96875] "deg C" Vector__XXX
 SG_ EngExhaustGasPort18Temp : 16|16@1+ (0.03125,-273) [-273|1734.96875] "deg C" Vector__XXX
 SG_ EngExhaustGasPort17Temp : 0|16@1+ (0.03125,-273) [-273|1734.96875] "deg C" Vector__XXX

BO_ 2566824190 EPT4: 8 Vector__XXX
 SG_ EngExhaustGasPort16Temp : 48|16@1+ (0.03125,-273) [-273|1734.96875] "deg C" Vector__XXX
 SG_ EngExhaustGasPort15Temp : 32|16@1+ (0.03125,-273) [-273|1734.96875] "deg C" Vector__XXX
 SG_ EngExhaustGasPort14Temp : 16|16@1+ (0.03125,-273) [-273|1734.96875] "deg C" Vector__XXX
 SG_ EngExhaustGasPort13Temp : 0|16@1+ (0.03125,-273) [-273|1734.96875] "deg C" Vector__XXX

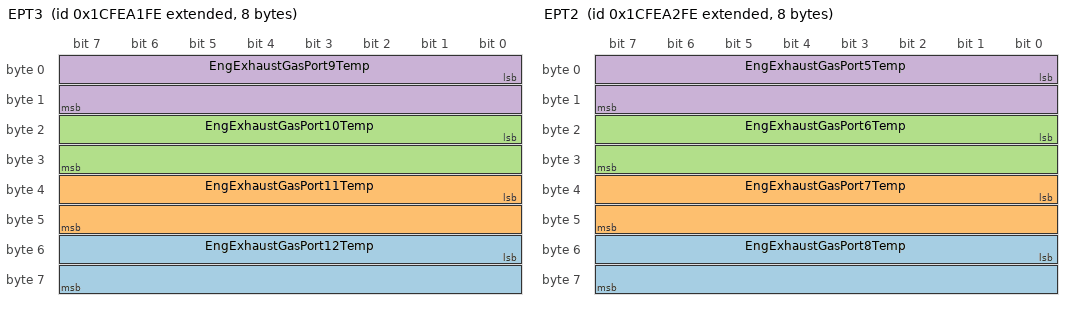
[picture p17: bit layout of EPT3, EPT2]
BO_ 2633933310 EPT3: 8 Vector__XXX
 SG_ EngExhaustGasPort12Temp : 48|16@1+ (0.03125,-273) [-273|1734.96875] "deg C" Vector__XXX
 SG_ EngExhaustGasPort11Temp : 32|16@1+ (0.03125,-273) [-273|1734.96875] "deg C" Vector__XXX
 SG_ EngExhaustGasPort10Temp : 16|16@1+ (0.03125,-273) [-273|1734.96875] "deg C" Vector__XXX
 SG_ EngExhaustGasPort9Temp : 0|16@1+ (0.03125,-273) [-273|1734.96875] "deg C" Vector__XXX

BO_ 2633933566 EPT2: 8 Vector__XXX
 SG_ EngExhaustGasPort8Temp : 48|16@1+ (0.03125,-273) [-273|1734.96875] "deg C" Vector__XXX
 SG_ EngExhaustGasPort7Temp : 32|16@1+ (0.03125,-273) [-273|1734.96875] "deg C" Vector__XXX
 SG_ EngExhaustGasPort6Temp : 16|16@1+ (0.03125,-273) [-273|1734.96875] "deg C" Vector__XXX
 SG_ EngExhaustGasPort5Temp : 0|16@1+ (0.03125,-273) [-273|1734.96875] "deg C" Vector__XXX

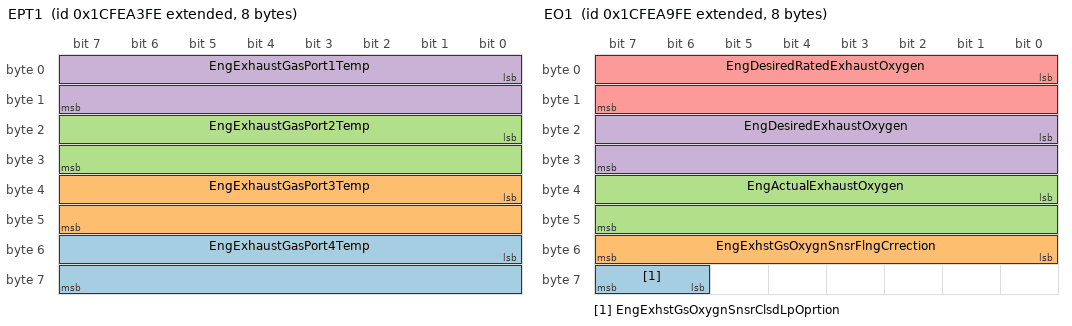
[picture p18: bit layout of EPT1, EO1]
BO_ 2633933822 EPT1: 8 Vector__XXX
 SG_ EngExhaustGasPort4Temp : 48|16@1+ (0.03125,-273) [-273|1734.96875] "deg C" Vector__XXX
 SG_ EngExhaustGasPort3Temp : 32|16@1+ (0.03125,-273) [-273|1734.96875] "deg C" Vector__XXX
 SG_ EngExhaustGasPort2Temp : 16|16@1+ (0.03125,-273) [-273|1734.96875] "deg C" Vector__XXX
 SG_ EngExhaustGasPort1Temp : 0|16@1+ (0.03125,-273) [-273|1734.96875] "deg C" Vector__XXX

BO_ 2566776062 EPD: 8 Vector__XXX
 SG_ PayloadPercentage : 0|8@1+ (1,0) [0|250] "%" Vector__XXX

BO_ 2566771454 EP: 8 Vector__XXX
 SG_ DataMemoryUsage : 16|8@1+ (0.4,0) [0|100] "%" Vector__XXX
 SG_ KeepAliveBatteryConsumption : 0|16@1+ (1,0) [0|64255] "mAhr" Vector__XXX

BO_ 2566775806 EOAC: 8 Vector__XXX
 SG_ TravelVelocityCtrlPos : 0|8@1+ (1,-125) [-125|125] "%" Vector__XXX

BO_ 2633935358 EO1: 8 Vector__XXX
 SG_ EngExhstGsOxygnSnsrClsdLpOprtion : 62|2@1+ (1,0) [0|3] "" Vector__XXX
 SG_ EngExhstGsOxygnSnsrFlngCrrection : 48|8@1+ (1,-125) [-125|125] "%" Vector__XXX
 SG_ EngActualExhaustOxygen : 32|16@1+ (0.0025,0) [0|160.6375] "%" Vector__XXX
 SG_ EngDesiredExhaustOxygen : 16|16@1+ (0.0025,0) [0|160.6375] "%" Vector__XXX
 SG_ EngDesiredRatedExhaustOxygen : 0|16@1+ (0.0025,0) [0|160.6375] "%" Vector__XXX

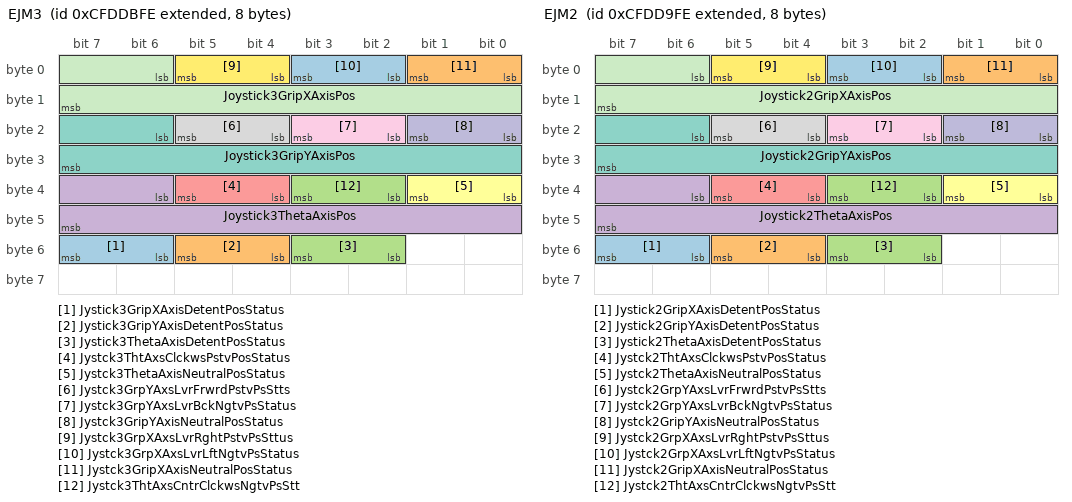
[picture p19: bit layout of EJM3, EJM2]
BO_ 2365447166 EJM3: 8 Vector__XXX
 SG_ Jystick3GripXAxisDetentPosStatus : 54|2@1+ (1,0) [0|3] "" Vector__XXX
 SG_ Jystick3GripYAxisDetentPosStatus : 52|2@1+ (1,0) [0|3] "" Vector__XXX
 SG_ Jystick3ThetaAxisDetentPosStatus : 50|2@1+ (1,0) [0|3] "" Vector__XXX
 SG_ Joystick3ThetaAxisPos : 38|10@1+ (1,0) [0|102] "%" Vector__XXX
 SG_ Jystck3ThtAxsClckwsPstvPosStatus : 36|2@1+ (1,0) [0|3] "" Vector__XXX
 SG_ Jystck3ThetaAxisNeutralPosStatus : 32|2@1+ (1,0) [0|3] "" Vector__XXX
 SG_ Joystick3GripYAxisPos : 22|10@1+ (1,0) [0|102] "%" Vector__XXX
 SG_ Jystck3GrpYAxsLvrFrwrdPstvPsStts : 20|2@1+ (1,0) [0|3] "" Vector__XXX
 SG_ Jystck3GrpYAxsLvrBckNgtvPsStatus : 18|2@1+ (1,0) [0|3] "" Vector__XXX
 SG_ Jystck3GripYAxisNeutralPosStatus : 16|2@1+ (1,0) [0|3] "" Vector__XXX
 SG_ Joystick3GripXAxisPos : 6|10@1+ (1,0) [0|102] "%" Vector__XXX
 SG_ Jystck3GrpXAxsLvrRghtPstvPsSttus : 4|2@1+ (1,0) [0|3] "" Vector__XXX
 SG_ Jystck3GrpXAxsLvrLftNgtvPsStatus : 2|2@1+ (1,0) [0|3] "" Vector__XXX
 SG_ Jystck3GripXAxisNeutralPosStatus : 0|2@1+ (1,0) [0|3] "" Vector__XXX
 SG_ Jystck3ThtAxsCntrClckwsNgtvPsStt : 34|2@1+ (1,0) [0|3] "" Vector__XXX

BO_ 2365446654 EJM2: 8 Vector__XXX
 SG_ Jystick2GripXAxisDetentPosStatus : 54|2@1+ (1,0) [0|3] "" Vector__XXX
 SG_ Jystick2GripYAxisDetentPosStatus : 52|2@1+ (1,0) [0|3] "" Vector__XXX
 SG_ Jystick2ThetaAxisDetentPosStatus : 50|2@1+ (1,0) [0|3] "" Vector__XXX
 SG_ Joystick2ThetaAxisPos : 38|10@1+ (1,0) [0|102] "%" Vector__XXX
 SG_ Jystck2ThtAxsClckwsPstvPosStatus : 36|2@1+ (1,0) [0|3] "" Vector__XXX
 SG_ Jystck2ThetaAxisNeutralPosStatus : 32|2@1+ (1,0) [0|3] "" Vector__XXX
 SG_ Joystick2GripYAxisPos : 22|10@1+ (1,0) [0|102] "%" Vector__XXX
 SG_ Jystck2GrpYAxsLvrFrwrdPstvPsStts : 20|2@1+ (1,0) [0|3] "" Vector__XXX
 SG_ Jystck2GrpYAxsLvrBckNgtvPsStatus : 18|2@1+ (1,0) [0|3] "" Vector__XXX
 SG_ Jystck2GripYAxisNeutralPosStatus : 16|2@1+ (1,0) [0|3] "" Vector__XXX
 SG_ Joystick2GripXAxisPos : 6|10@1+ (1,0) [0|102] "%" Vector__XXX
 SG_ Jystck2GrpXAxsLvrRghtPstvPsSttus : 4|2@1+ (1,0) [0|3] "" Vector__XXX
 SG_ Jystck2GrpXAxsLvrLftNgtvPsStatus : 2|2@1+ (1,0) [0|3] "" Vector__XXX
 SG_ Jystck2GripXAxisNeutralPosStatus : 0|2@1+ (1,0) [0|3] "" Vector__XXX
 SG_ Jystck2ThtAxsCntrClckwsNgtvPsStt : 34|2@1+ (1,0) [0|3] "" Vector__XXX

CM_ BO_ 2633895166 "This message is sent by the Master of a Working Set to identify an individual member of a specific Working Set (Master’s 
Source Address identifies the particular Working Set).";
CM_ SG_ 2633895166 IndustryGroup "0 = Global; 
   1  = On-Highway; 
   2  = Agricultural and Forestry; 
   3  = Construction; 
   4  = Marine;
   5  = Industrial - Process
          Control - Stationary (Gen-Sets)
   6  = Reserve for SAE
   7  = Reserve for SAE";
CM_ SG_ 2633895166 ManufacturerCode "Assigned by NMEA 2000 Committee";
CM_ BO_ 2566832382 "Transmitted with the service component identification that has the shortest distance or nearest time until the next service";
CM_ SG_ 2566832382 SrviceDelay_OperationalTimeBased "The time in vehicle operational time until the next vehicle service inspection is required. A negative value is transmitted if";
CM_ SG_ 2566832382 ServiceComponentIdentification "Identification of component needing service. See Table SPN911_A.Identification of component needing service. See Table SPN911_A.Identification of component needing service. See Table SPN911_A.";
CM_ SG_ 2566832382 ServiceDelay_CalendarTimeBased "The time in weeks until the next vehicle service inspection is required. A negative value is transmitted if the service";
CM_ SG_ 2566832382 ServiceDistance "The distance which can be traveled by the vehicle before the next service inspection is required. A negative distance is";
CM_ BO_ 2633928446 "NOTE - There are two acceptable formats for the Service PGN. Format 1 has only 8 bytes of data and reports the";
CM_ SG_ 2633928446 TimeSinceLastService "The vehicle operation time since the last service was performed. The type of service information is identified by the";
CM_ SG_ 2633928446 ServiceComponentIdentification "Identification of component needing service. See Table SPN911_A.";
CM_ SG_ 2566804478 MinContinuousRetarderTorque "Applied limit for minimum continuous retarder torque";
CM_ SG_ 2566804478 MaxContinuousRetarderTorque "Applied limit for maximum continuous retarder torque.";
CM_ SG_ 2566804478 MinContinuousRetarderSpeed "Applied limit for minimum continuous retarder RPM";
CM_ SG_ 2566804478 MaxContinuousRetarderSpeed "Applied limit for maximum continuous retarder RPM";
CM_ SG_ 2566804478 HghLmtThrshldFrMnCntnsTrqFrmRtrd "Maximum allowable value for minimum continuous retarder torque.";
CM_ SG_ 2566804478 LwLmtThrshldFrMxTrqeFromRetarder "Minimum allowable value for maximum continuous retarder torque.";
CM_ SG_ 2566804478 HghLmtThrshldFrMnCntnsRPMFrmRtrd "Maximum allowable value for minimum continuous retarder speed";
CM_ SG_ 2566804478 LwLmtThrshldFrMaxRPMFromRetarder "Minimum allowable value for maximum continuous retarder speed";
CM_ SG_ 2566847486 DrvlineRetarderOverheatIndicator "Signal from the driveline retarder indicating that its fluid temperature is above normal acceptable limits, and as a result,";
CM_ SG_ 2566847486 HydRetarderOilTemp "Temperature of oil found in a hydraulic retarder.";
CM_ SG_ 2566847486 HydRetarderPress "Gage pressure of oil in hydraulic retarder system.";
CM_ BO_ 2631859966 "NOTE—This message requires an Acknowledgement response (See J1939-21, PGN 59392) from the receiving node.";
CM_ SG_ 2631859966 SteerStraightAheadPosReset "Used to reset the straight ahead position for a steering sensor in the steering column or a steering controller's straight";
CM_ SG_ 2631859966 EngBuildHoursReset "Command signal used to reset the engine rebuild hours.";
CM_ SG_ 2631859966 ServiceComponentIdentification "Identification of component needing service. See Table SPN911_A.";
CM_ SG_ 2631859966 TripGroup2Proprietary "Command signal used to reset proprietary parameters associated with a trip but not defined within this document.";
CM_ SG_ 2631859966 TripGroup1 "Command signal used to reset the PGNs and parameters as defined in Table SPN988_A.";
CM_ BO_ 2566840830 "This map describes the stationary behavior of the retarder.";
CM_ SG_ 2566840830 PercentTorqueAtPeakTorquePoint5 "The torque limit that indicates the available retarder torque which can be provided by the retarder at point 5 of the retarder";
CM_ SG_ 2566840830 ReferenceRetarderTorque "This parameter is the 100% reference value for all defined indicated retarder torque parameters. It is only defined once";
CM_ SG_ 2566840830 RetarderSpeedAtPeakTorquePoint5 "Please reference PGN 65249";
CM_ SG_ 2566840830 PercentTorqueAtPoint4 "The torque limit that indicates the available retarder torque which can be provided by the retarder at points 3 and 4 of the";
CM_ SG_ 2566840830 RetarderSpeedAtPoint4 "Retarder speed of point 4 of the engine retarder torque map. Please reference PGN 65249.";
CM_ SG_ 2566840830 PercentTorqueAtPoint3 "The torque limit that indicates the available retarder torque which can be provided by the retarder at points 3 and 4 of the";
CM_ SG_ 2566840830 RetarderSpeedAtPoint3 "Retarder speed of point 3 of the engine retarder torque map. Please reference PGN 65249.";
CM_ SG_ 2566840830 PercentTorqueAtMaxSpeedPoint2 "The torque limit that indicates the available retarder torque which can be provided by the retarder at its maximum speed.";
CM_ SG_ 2566840830 MaxRetarderSpeedPoint2 "Maximum speed of retarder (Please reference PGN 65249).";
CM_ SG_ 2566840830 PercentTorqueAtIdlePoint1 "The torque limit that indicates the available retarder torque which can be provided by the retarder at idle speed. The data";
CM_ SG_ 2566840830 RetarderSpeedAtIdlePoint1 "Please reference PGN 65249";
CM_ SG_ 2566840830 RetarderCtrlMethod "This parameter identifies the number of steps used by the retarder.";
CM_ SG_ 2566840830 RetarderLocation "This parameter defines whether the “torque/speed curve” defined by the retarder configuration message (PGN 65249) is";
CM_ SG_ 2566840830 RetarderType "A vehicle retarder is a supplementary device to the wheel brakes for the driver to better control the vehicle. The wheel";
CM_ SG_ 2633930238 EngOperationTimeSinceRebuild "The time in engine operation since the last engine rebuild.";
CM_ BO_ 2566844670 "Power Takeoff Information";
CM_ SG_ 2566844670 PowerTakeoffSetSpeed "Rotational velocity selected by operator for device used to transmit engine power to auxiliary equipment.";
CM_ SG_ 2566844670 PowerTakeoffSpeed "Rotational velocity of device used to transmit engine power to auxiliary equipment.";
CM_ SG_ 2566844670 PowerTakeoffOilTemp "Temperature of lubricant in device used to transmit engine power to auxiliary equipment.";
CM_ SG_ 2566844670 OprtrEngPTOGvrnrMmrySelectSwitch "Measured state of the operator’s engine PTO governor memory select switch. This switch selects which of the two";
CM_ SG_ 2566844670 EngRmtPTOGvrnrVrblSpedCtrlSwitch "Switch signal which indicates that the remote PTO governor toggle switch is in the enabled (ON) position. If the toggle";
CM_ SG_ 2566844670 EngRmtPTOGvrnrPrprgrmmdSpdCtrlSw "Switch signal which indicates that the remote PTO governor toggle switch is in the enabled (ON) position. If the toggle";
CM_ SG_ 2566844670 EngPTOGvrnrCast_DecelerateSwitch "Switch signal of the PTO control activator which indicates that the activator is in the position to \"coast/decelerate\" the PTO";
CM_ SG_ 2566844670 EngPTOGovernorSetSwitch "Switch signal of the PTO control activator which indicates that the activator is in the position to \"set\" the engine PTO";
CM_ SG_ 2566844670 EngPTOGovernorResumeSwitch "Switch signal of the PTO control activator which indicates that the activator is in the position to \"resume\" a previously";
CM_ SG_ 2566844670 EngPTOGovernorEnableSwitch "Switch signal which indicates that the PTO governor toggle switch is in the enabled (ON) position and therefore it is";
CM_ SG_ 2566844670 EngPTOGovernorAccelerateSwitch "Switch signal of the PTO control activator which indicates that the activator is in the position to \"accelerate\" the PTO";
CM_ SG_ 2566844670 RmtPTOGvrnrPrprgrmmdSpdCtrlSwtch "Switch signal which indicates that the remote PTO governor toggle switch #2 is in the enabled (ON) position. If the toggle";
CM_ SG_ 2566844670 AuxInputIgnoreSwitch "Switch signal which overrides other switch input's ability to disable an engine's operating condition.";
CM_ BO_ 2566770174 "Message for items related to the operators controls for the window wipers and washers on the front and rear cab windows";
CM_ SG_ 2566770174 RearWasherFunction "State of operation selected by operator switch for the rear washer. The parameter, 'Front Operator Washer Switch’";
CM_ SG_ 2566770174 FrontOperatorWasherSwitch "State of operation selected by operator switch for the washer in front of the operator position. This parameter, 'Front";
CM_ SG_ 2566770174 FrontNonoperatorWasherSwitch "State of operation selected by operator switch for the front washer not in front of the operator position. The parameter,";
CM_ SG_ 2566770174 RearWiperDelayCtrl "Time between cycles of the rear wiper (i.e. from end of cycle 'n' to start of cycle 'n+1') as selected by the operator control";
CM_ SG_ 2566770174 FrontNonoperatorWiperDelayCtrl "Time between cycles of the front non-operator side wiper (i.e. from end of cycle 'n' to start of cycle 'n+1') as selected by";
CM_ SG_ 2566770174 FrontOperatorWiperDelayCtrl "Time between cycles of the front operator side wiper (i.e. from end of cycle 'n' to start of cycle 'n+1') as selected by the";
CM_ SG_ 2566770174 RearWiperSwitch "State of operation selected by operator switch for the rear wiper. The parameter, 'Front Operator Washer Switch' should";
CM_ SG_ 2566770174 FrontOperatorWiperSwitch "State of operation selected by operator switch for the Wiper in front of the operator position. This parameter, 'Front";
CM_ SG_ 2566770174 FrontNonoperatorWiperSwitch "State of operation selected by operator switch for the front wiper not in front of the operator position. The parameter,";
CM_ BO_ 2566769662 "Allows for the selection of off-highway engine control modes, as they apply to different modes of engine operation which";
CM_ SG_ 2566769662 EngAltDroopAuxInputSelect "In some off-highway applications it may be desirable to have multiple droop settings available across the range of engine";
CM_ SG_ 2566769662 EngAltDroopRemoteAccelSelect "In some off-highway applications it may be desirable to have multiple droop settings available across the range of engine";
CM_ SG_ 2566769662 EngAltDroopAccel2Select "Same description as Engine Alternate Droop Accelerator 1 Select (SPN 2881) except that the selections may apply to";
CM_ SG_ 2566769662 EngAltDroopAccel1Select "In some off-highway applications it may be desirable to have multiple droop settings available across the range of engine";
CM_ SG_ 2566769662 EngAltRatingSelect "In some off-highway applications it may be desirable to have multiple engine ratings available for selection by the";
CM_ SG_ 2566769662 EngAltLowIdleSwitch "Operator switch which selects between two low idle speeds, default and alternate.";
CM_ SG_ 2566769662 EngSynchronizationSwitch "This is the On/Off operation of the Multiple Unit Synchronization functionality. When it is enabled (i.e. On) the master";
CM_ SG_ 2566769662 EngAuxGovernorSwitch "This is the On/Off operation of the Auxiliary Governor feature switch. This feature is used to allow engine speed to be";
CM_ BO_ 2566768638 "Reports the states of off-highway engine control modes, as they apply to different modes of engine operation which may";
CM_ SG_ 2566768638 EngAltDroopAuxInputSelectState "In some off-highway applications it may be desirable to have multiple droop settings available across the range of engine";
CM_ SG_ 2566768638 EngAltDropRemoteAccelSelectState "In some off-highway applications it may be desirable to have multiple droop settings available across the range of engine";
CM_ SG_ 2566768638 EngAltDroopAccel2SelectState "In some off-highway applications it may be desirable to have multiple droop settings available across the range of engine";
CM_ SG_ 2566768638 EngAltDroopAccel1SelectState "In some off-highway applications it may be desirable to have multiple droop settings available across the range of engine";
CM_ SG_ 2566768638 EngAltRatingSelectState "In some off-highway applications it may be desirable to have multiple engine ratings available for selection by the";
CM_ SG_ 2566768638 EngAltLowIdleSelectState "In many applications, it is desirable that an alternate low idle speed setting be made available via switch input. The normal";
CM_ SG_ 2566768638 EngMultiUnitSyncState "This feature is widely used in Industry to operate multiple engines from a single command source. A master engine will";
CM_ SG_ 2566768638 EngAuxGovernorState "This is the Engine Auxiliary Governor feature. This feature is used to allow engine speed to be controlled by an auxiliary";
CM_ BO_ 2365443326 "The message containing the information about the position of the operator's external light control switch(s). Including";
CM_ SG_ 2365443326 OprtorsDesiredDelayedLampOffTime "A 16 bit parameter to be associated with Delayed Off position (1000 binary) of the Main Light Switch. This parameter";
CM_ SG_ 2365443326 OperatorsDesiredBacklight "A 8 bit parameter to indicate the level of back lighting the operator has selected for displays. This is to be differentiated";
CM_ SG_ 2365443326 HighLowBeamSwitch "A 2 bit parameter to indicate the selected position of the operator's high/low beam select switch.";
CM_ SG_ 2365443326 HazardLightSwitch "A 2 bit parameter to indicate the selected position of the operator's hazard light switch.";
CM_ SG_ 2365443326 TurnSignalSwitch "A 4 bit parameter to indicate the selected position of the operator's turn signal switch.";
CM_ SG_ 2365443326 MainLightSwitch "A 4 bit parameter to indicate the selected position of the operator's main light switch.";
CM_ SG_ 2365443326 WorkLightSwitch "A 4 bit parameter to indicate the selected position of the operator's work light switch. In Ag applications the work lights are";
CM_ BO_ 2566776318 "Reports the possible maximum vehicle speed limits, one through seven, and the applied maximum vehicle speed limit.";
CM_ SG_ 2566776318 AppliedVehicleSpeedLimit "The vehicle speed limit in effect.";
CM_ SG_ 2566776318 MaxVehicleSpeedLimit7 "The highest of the seven lowest vehicle speed limits";
CM_ SG_ 2566776318 MaxVehicleSpeedLimit6 "The highest of the six lowest vehicle speed limits";
CM_ SG_ 2566776318 MaxVehicleSpeedLimit5 "The highest of the five lowest vehicle speed limits";
CM_ SG_ 2566776318 MaxVehicleSpeedLimit4 "The highest of the four lowest vehicle speed limits";
CM_ SG_ 2566776318 MaxVehicleSpeedLimit3 "The highest of the three lowest vehicle speed limits";
CM_ SG_ 2566776318 MaxVehicleSpeedLimit2 "The highest of the two lowest vehicle speed limits";
CM_ SG_ 2566776318 MaxVehicleSpeedLimit1 "The lowest Maximum Vehicle Speed Limit. This value is the similar to SPN 74. However, SPN 74 was not specifically";
CM_ BO_ 2566802686 "The message contains parameters that control military specific lights.";
CM_ SG_ 2566802686 OprtrsBlackOutIntensitySelection "Operators Selection of lamp intensity in black out mode. This parameter provides the operators selected illumination";
CM_ SG_ 2566802686 BlackOutWorkLampSelect "Black Out Work Lamp Selection";
CM_ SG_ 2566802686 NightVisionIlluminatorSelect "Night Vision Illuminator Selection";
CM_ SG_ 2566802686 BlackOutBrake_StopLampSelect "Black Out Brake/Stop Lamp Selection";
CM_ SG_ 2566802686 ConvoyDrivingLampSelect "Black Out Convoy Driving Lamp Selection";
CM_ SG_ 2566802686 ConvoyLampSelect "Black Out Convoy Lamp Selection";
CM_ SG_ 2566802686 FrontBlackOutMarkerLampSelect "Front Black Out Marker Lamp Selection";
CM_ SG_ 2566802686 RearBlackOutMarkerSelect "Rear Black Out Marker Selection";
CM_ BO_ 2566774014 "This messages contains marine vessel control information for the engine";
CM_ SG_ 2566774014 SlowVesselModeStatus "The status of the Slow Vessel Mode. Slow Vessel Mode puts the engine in a lower-than-normal low idle speed during";
CM_ SG_ 2566774014 TrollingModeStatus "The status of the Trolling Mode. Trolling mode limits the top speed. Full range travel of the throttle level spans from low";
CM_ SG_ 2566774014 EngThrttlSynchrnzationModeStatus "The status of the Throttle Synchronization Mode. Throttle Synchronization Mode is used to indicate which throttle, if any,";
CM_ BO_ 2566823166 "Main Bearing Temperature 3";
CM_ SG_ 2566823166 EngMainBearing11Temp "Temperature of the main bearing which supports the crankshaft of the engine.";
CM_ SG_ 2566823166 EngMainBearing10Temp "Temperature of the main bearing which supports the crankshaft of the engine.";
CM_ SG_ 2566823166 EngMainBearing9Temp "Temperature of the main bearing which supports the crankshaft of the engine.";
CM_ BO_ 2566823422 "Main Bearing Temperature 2";
CM_ SG_ 2566823422 EngMainBearing8Temp "Temperature of the main bearing which supports the crankshaft of the engine.";
CM_ SG_ 2566823422 EngMainBearing7Temp "Temperature of the main bearing which supports the crankshaft of the engine.";
CM_ SG_ 2566823422 EngMainBearing6Temp "Temperature of the main bearing which supports the crankshaft of the engine.";
CM_ SG_ 2566823422 EngMainBearing5Temp "Temperature of the main bearing which supports the crankshaft of the engine.";
CM_ BO_ 2566823678 "Main Bearing Temperature 1";
CM_ SG_ 2566823678 EngMainBearing4Temp "Temperature of the main bearing which supports the crankshaft of the engine.";
CM_ SG_ 2566823678 EngMainBearing3Temp "Temperature of the main bearing which supports the crankshaft of the engine.";
CM_ SG_ 2566823678 EngMainBearing2Temp "Temperature of the main bearing which supports the crankshaft of the engine.";
CM_ SG_ 2566823678 EngMainBearing1Temp "Temperature of the main bearing which supports the crankshaft of the engine.";
CM_ SG_ 2432595710 DisplayDeadbands "Sets Display Deadbands mode.";
CM_ SG_ 2432595710 LEDPatternCtrl "Sets LED Pattern control mode on laser leveling systems.";
CM_ SG_ 2432595710 LEDDisplayDeadbandCtrl "This parameter informs the system what the selected Display deadband will be.";
CM_ SG_ 2432595710 LEDDisplayModeCtrl "This parameter informs the system what the selected Display mode will be.";
CM_ SG_ 2432595710 LEDDisplayData1 "Informs display devices how to display the current vertical position.";
CM_ SG_ 2365486590 LaserStrikeDataLatency "Time from laser strike to CAN message transmission. This parameter will be reported by survey receiver type devices";
CM_ SG_ 2365486590 LaserReceiverType "Identifies which type of Laser Receiver transmitted the message.";
CM_ SG_ 2365486590 LaserStrikeVerticalDeviation "The calculated distance from the laser strike position to the current land leveling system reference point.";
CM_ SG_ 2365486590 AbsLaserStrikePos "Laser Strike location on the survey type laser receiver.";
CM_ SG_ 2365485566 LaserTracerInformation "Provides the status of the laser tracer to the operator.";
CM_ SG_ 2365485566 LEDDisplayData2 "Informs display devices how to display the current position of the laser tracer.";
CM_ SG_ 2365485566 LaserTracerHorizontalDeviation "The calculated percent deviation between the target distance and the center of the laser tracer.";
CM_ SG_ 2365485566 LaserTracerVerticalDistance "The elevation of the laser tracer sensor in a laser leveling system.";
CM_ SG_ 2365485566 LaserTracerTargetDeviation "The calculated distance for the laser target to the current laser tracer reference point.";
CM_ BO_ 2633939454 "Trip Fuel Information (Liquid)";
CM_ SG_ 2633939454 TripCruiseFuelUsed "Total fuel consumed while the engine is in the cruise hold state since the last trip reset. If both cruise control and VSL";
CM_ SG_ 2633939454 TripVehicleIdleFuelUsed "Total fuel consumed while neither the PTO or remote PTO governor is in the hold state, the engine speed is greater than";
CM_ SG_ 2633939454 TripDriveFuelUsed "Total fuel consumed while the engine speed is greater than zero, vehicle speed is greater than or equal to 2 km/h, and";
CM_ SG_ 2633939454 TripPTOGovernorNonmovingFuelUsed "Total fuel consumed while either the PTO or remote PTO governors are in the hold state, the engine speed is greater";
CM_ SG_ 2633939454 TripPTOGovernorMovingFuelUsed "Total fuel consumed while either the PTO or remote PTO governors are in the hold state, the engine speed is greater";
CM_ SG_ 2633939454 TripDriveFuelEconomy "Trip drive fuel economy is equal to the distance traveled by vehicle in the drive state (engine speed greater than zero,";
CM_ SG_ 2365486334 BldeHeightSetPointHighResolution "High resolution for the laser guided blade set point. The high resolution required for more accurate control and 'accurate'";
CM_ SG_ 2365486334 ModifyLevelingSystemSetPoint "Used to control and coordinate the set point for the leveling system.";
CM_ BO_ 2364542462 "Group of operational parameters associated with the Land Leveling System, such as switch states. This is provided to";
CM_ SG_ 2364542462 StElvtnSensor2ReferenceElevation "Command from a display or other external device (i.e. remote switch) to the land leveling system controller instructing the";
CM_ SG_ 2364542462 StElvtnSensor1ReferenceElevation "Command from a display or other external device (i.e. remote switch) to the land leveling system controller instructing the";
CM_ SG_ 2364542462 SdshftDsrdBldeOffsetOperatorCtrl "This parameter indicates the side-shift blade control mode operator control state the user has set for the land leveling";
CM_ SG_ 2364542462 SdshiftBladeCtrlModeOperatorCtrl "This parameter indicates the side-shift offset operator control state the user has set for the land leveling system. When an";
CM_ SG_ 2364542462 RghtDsredBladeOffsetOperatorCtrl "This parameter indicates the right blade offset operator control state the user has set for the land leveling system. The";
CM_ SG_ 2364542462 LftDsiredBladeOffsetOperatorCtrl "This parameter indicates the left blade offset operator control state the user has set for the land leveling system. The left";
CM_ SG_ 2364542462 RightBladeCtrlModeOperatorCtrl "This parameter indicates the right blade control mode operator control state the user has set for the land leveling system.";
CM_ SG_ 2364542462 LeftBladeCtrlModeOperatorCtrl "This parameter indicates the left blade control mode operator control state the user has set for the land leveling system.";
CM_ SG_ 2364542462 BladeAutoModeCmd "Allows other controllers to command to the primary control system what they think is the appropriate auto control mode to";
CM_ SG_ 2364542462 DesiredGradeOffsetSwitch "This parameter indicates the grade offset switch state the user has set for the land leveling system. The desired grade";
CM_ SG_ 2364542462 BladeCtrlModeSwitch "This parameter indicates the blade control mode switch state the user has set for the land leveling system. The switch";
CM_ SG_ 2365486078 MastPos "Used to monitor the position of the sensor attached to the land leveling mast.";
CM_ SG_ 2633937918 FlexibleFuelPercentage "Measured signal that indicates the percentage of alcohol in the fuel currently being used. 0% means no alcohol in fuel,";
CM_ SG_ 2633937918 TripAverageFuelRate "Average fuel rate, equal to trip fuel divided by trip time while the engine speed is above zero, since the last trip reset. This";
CM_ SG_ 2633937918 TotalEngPTOGovernorFuelUsed "Total fuel used while the PTO or remote PTO governors are in the hold state and engine speed is above zero, over the";
CM_ SG_ 2566845182 EngAverageFuelEconomy "Average of instantaneous fuel economy for that segment of vehicle operation of interest.";
CM_ SG_ 2566845182 EngInstantaneousFuelEconomy "Current fuel economy at current vehicle velocity.";
CM_ SG_ 2566845182 EngFuelRate "Amount of fuel consumed by engine per unit of time.";
CM_ SG_ 2566845182 EngThrottleValve2Pos "The sensed position feedback of the valve, coming from a second electrical actuator for a second throttle plate, used to";
CM_ SG_ 2566845182 EngThrottleValve1Pos "The position of the valve used to regulate the supply of a fluid, usually air or fuel/air mixture, to an engine. 0% represents";
CM_ BO_ 2566842878 "Engine fuel consumption accumulators. See PGN 64777 for alternate resolution.";
CM_ SG_ 2566842878 EngTotalFuelUsed "Accumulated amount of fuel used during vehicle operation. See SPN 5054 for alternate resolution.";
CM_ SG_ 2566842878 EngTripFuel "Fuel consumed during all or part of a journey. See SPN 5053 for alternate resolution.";
CM_ BO_ 2633883646 "Front wheel drive ECU information";
CM_ SG_ 2633883646 FrontWheelDriveActuatorStatus "Feedback on the front wheel drive actuator.";
CM_ BO_ 2633880062 "Information which specifies the capabilities of the Fleet Management System (FMS) - standard interface device. This";
CM_ SG_ 2633880062 FMSstandardSWversionSupported "Information that identifies which issue level of the FMS-standard document the software included in the FMS gateway";
CM_ SG_ 2633880062 FMSstandardRequestsSupported "Status signal which indicates if the FMS Vehicle Interface (FMS Gateway) will respond to requests from the FMS device";
CM_ SG_ 2633880062 FMSstandardDiagnosticsSupported "Status signal which indicates if the FMS Vehicle Interface (FMS Gateway) supports the handling of diagnostic messages";
CM_ SG_ 2566806526 LnDpartureIndicationEnableStatus "Indicates whether lane departure indication is active.";
CM_ SG_ 2566806526 LaneTrackingStatusLeftSide "Indicates whether the left side is tracking lane.";
CM_ SG_ 2566806526 LaneTrackingStatusRightSide "Indicates whether right side is tracking lane.";
CM_ BO_ 2431649790 "Tr";
CM_ SG_ 2431649790 LaneDepartureImminentLeftSide "Indicates departure imminent on left side of lane.";
CM_ SG_ 2431649790 LaneDepartureImminentRightSide "Indicates departure imminent on right side of lane.";
CM_ SG_ 2431649790 LaneDepartureRight "Indicates that the middle of vehicle departs the lane on the right side. The parameter indicates that the vehicle is changing";
CM_ SG_ 2431649790 LaneDepartureLeft "Indicates that the middle of vehicle departs the lane on the left side. The parameter indicates that the vehicle is changing";
CM_ SG_ 2633929214 EngFuelLeakage2 "Status signal which indicates fuel leakage in the fuel rail of the engine. Location can be either before or after the fuel";
CM_ SG_ 2633929214 EngFuelLeakage1 "Status signal which indicates fuel leakage in the fuel rail of the engine. Location can be either before or after the fuel";
CM_ SG_ 2566831614 FanDriveBypassCmdStatus "Status of the Fan Drive Bypass Command as being commanded by the ECU. The fan drive bypass diverts pump";
CM_ SG_ 2566831614 HydFanMotorPress "The hydraulic pressure used to drive the fan system, sensed before the hydraulic fan motor.";
CM_ SG_ 2566831614 FanSpeed "The speed of the fan associated with engine coolant system.";
CM_ SG_ 2566831614 FanDriveState "This parameter is used to indicate the current state or mode of operation by the fan drive.";
CM_ SG_ 2566831614 EstPercentFanSpeed "Estimated fan speed as a ratio of the fan drive (current speed) to the fully engaged fan drive (maximum fan speed). A two";
CM_ BO_ 2566820094 "NOTE -The torque history PGN is variable in length and may contain up to 125 torque history records. Each torque";
CM_ SG_ 2566820094 EngTorqueLimit6AxleInput "Limit applied to the engine output torque based on the maximum allowable axle input torque. Axle input torque is";
CM_ SG_ 2566820094 EngTorqueLimit5Switch "Limit applied to the engine output torque based on activation of an ECU switch input.";
CM_ SG_ 2566820094 EngTorqueLimit4Trans "Limit applied to the engine output torque during vehicle operation in transmission gear ratios numerically less than or";
CM_ SG_ 2566820094 EngTorqueLimit3Trans "Limit applied to the engine output torque during vehicle operation in transmission gear ratios numerically less than or";
CM_ SG_ 2566820094 TransGearRatio3 "Gear ratio value stored in the ECU that is used to define a range of transmission gears for which a limit is applied to the";
CM_ SG_ 2566820094 EngTorqueLimit2Trans "Limit applied to the engine output torque during vehicle operation in transmission gear ratios numerically less than or";
CM_ SG_ 2566820094 TransGearRatio2 "Gear ratio value stored in the ECU that is used to define a range of transmission gears for which a limit is applied to the";
CM_ SG_ 2566820094 EngTorqueLimit1Trans "Limit applied to the engine output torque during vehicle operation in transmission gear ratios numerically greater than";
CM_ SG_ 2566820094 TransGearRatio1 "Gear ratio value stored in the ECU that is used to define a range of transmission gears for which a limit is applied to the";
CM_ SG_ 2566820094 EngTorqueLimitFeature "Torque limit rating described in the current record.";
CM_ SG_ 2566820094 TorqueLimitingFeatureStatus "Status of an ECU feature which limits the torque output of the engine.";
CM_ SG_ 2566820094 CalibRecordDurationTime "Duration in hours for which the engine operated in the conditions captured in the current record.";
CM_ SG_ 2566820094 CalibRecordStartYear "Calendar year timestamp when an ECU record was established.";
CM_ SG_ 2566820094 CalibRecordStartDay "Calendar day timestamp when an ECU record was established.";
CM_ SG_ 2566820094 CalibRecordStartMonth "Calendar month timestamp when an ECU record was established.";
CM_ SG_ 2566820094 EngPeakTorque2 "Maximum torque output of the current ECU calibration when the engine operates on torque curve 2. For calibrations that";
CM_ SG_ 2566820094 EngPeakTorque1 "Maximum torque output of the current ECU calibration when the engine operates on torque curve 1. For calibrations that";
CM_ SG_ 2566820094 EngPower "Advertised engine power capability. Advertised power is what a customer will find on a sales sheet for an engine with a";
CM_ SG_ 2566820094 NumberOfEngTorqueHistoryRecords "Number of torque history records contained in the engine torque history PGN. A value of 0 is broadcast if no torque";
CM_ BO_ 2364542206 "Electronic Transmission Controller #8";
CM_ SG_ 2364542206 TransClutch_ConverterInputSpeed "Rotational velocity of the input to a transmission's master clutch or torque converter. In most cases the rotational velocity";
CM_ SG_ 2364542206 TransTorqueConverterRatio "Ratio of the transmissions torque converter output torque to torque converter input torque at current speed.";
CM_ BO_ 2566802174 "Electronic Transmission Controller 7";
CM_ SG_ 2566802174 TrnsRverseGearShiftInhibitStatus "Reflects the status of transmission reverse inhibit activity in response to requests via SPN 4242 - Transmission Reverse";
CM_ SG_ 2566802174 TrnsCrrentRangeDisplayBlankState "State signal indicating a transmission request for the display of the Transmission Current Range parameter (SPN 163) to";
CM_ SG_ 2566802174 TransWarningIndicator "Signal from transmission indicating that some aspect of its operation is not functioning correctly, and as a result,";
CM_ SG_ 2566802174 TransMode8Indicator "Indicates whether transmission mode 8 is enabled. Modes are manufacturer specific and are not necessarily mutually";
CM_ SG_ 2566802174 TransMode7Indicator "Indicates whether transmission mode 7 is enabled. Modes are manufacturer specific and are not necessarily mutually";
CM_ SG_ 2566802174 TransMode6Indicator "Indicates whether transmission mode 6 is enabled. Modes are manufacturer specific and are not necessarily mutually";
CM_ SG_ 2566802174 TransMode5Indicator "Indicates whether transmission mode 5 is enabled. Modes are manufacturer specific and are not necessarily mutually";
CM_ SG_ 2566802174 TransRequestedGearFeedback "Feedback of the SPN 525 Transmission Requested Gear input as received from the shift selector, ABS or engine via";
CM_ SG_ 2566802174 TransMode1Indicator "This state signal is the transmission’s indication that it is operating under transmission mode 1 (SPN 1852) as";
CM_ SG_ 2566802174 TransMode2Indicator "This state signal is the transmission’s indication that it is operating under transmission mode 2 (SPN 1853) as";
CM_ SG_ 2566802174 TransMode3Indicator "This state signal is the transmission’s indication that it is operating under transmission mode 3 (SPN 1854) as";
CM_ SG_ 2566802174 TransMode4Indicator "This state signal is the transmission’s indication that it is operating under transmission mode 4 (SPN 1855) as";
CM_ SG_ 2566802174 TransShiftInhibitIndicator "State signal indicating a transmission request for the Shift Inhibit Indicator to be active or inactive. The shift inhibit";
CM_ SG_ 2566802174 TransEngCrankEnable "State signal from the transmission indicating if the transmission’s status is such that engine cranking is allowed (i.e. at a";
CM_ SG_ 2566802174 ActiveShiftConsoleIndicator "Signal from transmission control unit indicating which shift console (primary or secondary) it currently considers as the";
CM_ SG_ 2566802174 TransReadyForBrakeRelease "This parameter indicates that enough torque / motive force is available at the transmission output shaft to release all the";
CM_ SG_ 2566802174 TrnsRqstedRangeDisplayFlashState "State signal indicating a transmission request for the display of the Transmission Requested Range parameter (SPN 162)";
CM_ SG_ 2566802174 TrnsRqstedRangeDisplayBlankState "State signal indicating a transmission request for the display of the Transmission Requested Range parameter (SPN162)";
CM_ SG_ 2566802174 TransServiceIndicator "Signal from transmission indicating that some aspect of the gearbox requires servicing, such as the oil, filter, clutch(es) or";
CM_ SG_ 2633935870 ClutchLifeRemaining "Signal which indicates the actual clutch life remaining in percent. One hundred percent means the clutch is brand new";
CM_ SG_ 2633935870 LowestPossibleGear "The transmission calculates this gear continuously. Together with the highest possible gear (see SPN 1115), it enables a";
CM_ SG_ 2633935870 HighestPossibleGear "The transmission calculates this gear continuously. Together with the lowest possible gear (see SPN 1114), it enables a";
CM_ SG_ 2633935870 RecommendedGear "The transmission calculates this gear continuously. In dangerous situations this gear may be selected to gain back";
CM_ BO_ 2633942014 "Electronic Transmission Controller 5";
CM_ SG_ 2633942014 TransForwardDirectionSwitch "Identifies the status of the switch that indicates forward direction.";
CM_ SG_ 2633942014 TransNeutralSwitch "Identifies the status of the switch that indicates neutral.";
CM_ SG_ 2633942014 TransReverseDirectionSwitch "Identifies the status of the switch that indicates reverse direction.";
CM_ SG_ 2633942014 TransLowRangeSenseSwitch "Identifies the status of the switch that represents low range.";
CM_ SG_ 2633942014 TransHighRangeSenseSwitch "Identifies the status of the switch that represents high range.";
CM_ SG_ 2633942526 TransSynchronizerBrakeValue "The current modulated value for the air supply to the synchronizer brake.";
CM_ SG_ 2633942526 TransSynchronizerClutchValue "The current modulated value for the air supply to the synchronizer clutch.";
CM_ SG_ 2633943038 TransInertiaBrakeActuator "Identifies the status of the actuator that controls the inertia brake.";
CM_ SG_ 2633943038 TransDefuelActuator "Identifies the status of the actuator that controls the engine defuel mechanism.";
CM_ SG_ 2633943038 TransLockupClutchActuator "Identifies the status of the actuator that controls the lockup clutch.";
CM_ SG_ 2633943038 TransClutchActuator "Identifies the status of the actuator that controls the clutch.";
CM_ SG_ 2633943038 TransSplitterIndirectActuator "Identifies the status of the splitter indirect actuator in the auxiliary unit.";
CM_ SG_ 2633943038 TransSplitterDirectActuator "Identifies the status of the splitter direct actuator in the auxiliary unit.";
CM_ SG_ 2633943038 TransRangeLowActuator "Identifies the status of the range low actuator in the auxiliary unit.";
CM_ SG_ 2633943038 TransRangeHighActuator "Identifies the status of the range high actuator in the auxiliary unit.";
CM_ SG_ 2633943038 TransShiftFingerGearActuator2 "Identifies the status of the actuator that moves the shift finger identified as gear actuator #2.";
CM_ SG_ 2633943038 TransShiftFingerRailActuator2 "Identifies the status of the actuator that moves the shift finger identified as rail actuator #2.";
CM_ SG_ 2633943038 TransShiftFingerGearActuator1 "Identifies the status of the actuator that moves the shift finger identified as gear actuator #1.";
CM_ SG_ 2633943038 TransShiftFingerRailActuator1 "Identifies the status of the actuator that moves the shift finger identified as rail actuator #1.";
CM_ SG_ 2633943038 TrnsShftFngerCenterRailIndicator "Identifies the status of the shift finger in the center rail position.";
CM_ SG_ 2633943038 TrnsShftFngerEngagementIndicator "Identifies the status of the shift finger in the engagement position.";
CM_ SG_ 2633943038 TransShiftFingerNeutralIndicator "Indicates the status of the shift finger in the neutral position.";
CM_ SG_ 2633943038 TransShiftFingerRailPos "The current position of the shift finger in the rail direction.";
CM_ SG_ 2633943038 TransShiftFingerGearPos "The current position of the shift finger in the gear direction.";
CM_ SG_ 2565867006 TransCurrentRange "Range currently being commanded by the transmission control system. Characters may include P, Rx, Rx-1...R2, R1, R,";
CM_ SG_ 2565867006 TransRequestedRange "Range selected by the operator. Characters may include P, Rx, Rx-1...R2, R1, R, Nx, Nx-1...N2, N1, N, D, D1, D2..., Dx,";
CM_ SG_ 2565867006 TransCurrentGear "The gear currently engaged in the transmission or the last gear engaged while the transmission is in the process of";
CM_ SG_ 2565867006 TransActualGearRatio "Actual ratio of input shaft speed to output shaft speed.";
CM_ SG_ 2565867006 TransSelectedGear "The gear that the transmission will attempt to achieve during the current shift if a shift is in progress, or the next shift if one";
CM_ SG_ 2364539646 SrcAddrssOfCntrllngDvcFrTrnsCtrl "The source address of the SAE J1939 device currently controlling the transmission. Its value may be the source address";
CM_ SG_ 2364539646 TransInputShaftSpeed "Rotational velocity of the primary shaft transferring power into the transmission. When a torque converter is present, it is";
CM_ SG_ 2364539646 MomentaryEngMaxPowerEnable "Momentarily Requesting highest torque map from the engine control";
CM_ SG_ 2364539646 ProgressiveShiftDisable "Command signal used to indicate that progressive shifting by the engine should be disallowed.";
CM_ SG_ 2364539646 EngMomentaryOverspeedEnable "Command signal used to indicate that the engine speed may be boosted up to the maximum engine overspeed value to";
CM_ SG_ 2364539646 PercentClutchSlip "Parameter which represents the ratio of input shaft speed to current engine speed (in percent).";
CM_ SG_ 2364539646 TransOutputShaftSpeed "Calculated speed of the transmission output shaft.";
CM_ SG_ 2364539646 TrnsTrqCnvrtrLckpTrnstnInProcess "State signal indicating whether or not the transmission torque converter lock up clutch is transitioning between being";
CM_ SG_ 2364539646 TransShiftInProcess "Indicates that the transmission is in process of shifting from the current gear to the selected gear. This state is generally";
CM_ SG_ 2364539646 TrnsTorqueConverterLockupEngaged "State signal which indicates whether the torque converter lockup is engaged.";
CM_ SG_ 2364539646 TransDrivelineEngaged "Driveline engaged indicates the transmission controlled portion of the driveline is engaged sufficiently to allow a transfer";
CM_ BO_ 2566810110 "This parameter group is used to transmit high resolution engine temperatures for control purposes.";
CM_ SG_ 2566810110 EngChargeAirCooler1OutletTemp "Temperature of combustion air after it exits from the Charge Air Cooler 1 but before any mixing of recirculated exhaust";
CM_ SG_ 2566810110 EngIntkVlvActuationSystemOilTemp "The temperature of the oil in the hydraulic system that powers the intake valve actuation system.";
CM_ SG_ 2566810110 EngIntakeManifold1AirTemp "Temperature of pre-combustion air found in intake manifold of engine air supply system. The higher resolution is required";
CM_ SG_ 2566810110 EngCoolantTemp "Temperature of liquid found in engine cooling system. The higher resolution is required for control purposes.";
CM_ BO_ 2566825214 "Engine Temperature 2";
CM_ SG_ 2566825214 EngExhstGsRcirculation1DiffPress "Differential pressure across the Exhaust Gas Recirculation (EGR) system";
CM_ SG_ 2566825214 EngExhaustGasRecirculation1Temp "Temperature of Recirculated Exhaust Gas. This should not be used for Exhaust Gas Recirculation Mixer Intake";
CM_ SG_ 2566825214 EngECUTemp "Temperature of the engine electronic control unit.";
CM_ SG_ 2566825214 EngOilTemp2 "Temperature of the engine lubricant.";
CM_ BO_ 2566844158 "Engine Temperature 1";
CM_ SG_ 2566844158 EngFuelTemp1 "Temperature of fuel (or gas) passing through the first fuel control system. See SPN 3468 for the second control system";
CM_ SG_ 2566844158 EngIntercoolerThermostatOpening "The current position of the thermostat used to regulate the temperature of the engine intercooler. A value of 0%";
CM_ SG_ 2566844158 EngIntercoolerTemp "Temperature of liquid found in the intercooler located after the turbocharger.";
CM_ SG_ 2566844158 EngTurboOilTemp "Temperature of the turbocharger lubricant.";
CM_ SG_ 2566844158 EngOilTemp1 "Temperature of the engine lubricant.";
CM_ SG_ 2566844158 EngCoolantTemp "Temperature of liquid found in engine cooling system.";
CM_ SG_ 2566785022 EngExhaustGasTempLeftManifold "Temperature of combustion byproducts within the left engine exhaust manifold. Single manifold engines should use";
CM_ SG_ 2566785022 EngExhaustGasTempRightManifold "Temperature of combustion byproducts within the right engine exhaust manifold. Single manifold engines should use";
CM_ BO_ 2565868542 "PGN which indicates the actual angle and the status of a steerable axle";
CM_ SG_ 2565868542 TypeOfSteerTrans "Type of Steering Transmission (Ref. ECE Regulation 79 paragraph 2.6)";
CM_ SG_ 2565868542 TypeOfSteerForces "Type of Steering Forces (Ref. ECE Regulation 79 paragraph 2.5)";
CM_ SG_ 2565868542 SteerType "Indicates the different types of steering systems (ref. ECE Regulation 79 paragraph 2.5)";
CM_ SG_ 2565868542 SteerableLiftAxleLoweringInhibit "A signal which indicates if lowering of lifted axle is allowed or inhibited.";
CM_ SG_ 2565868542 StatusOfSteerAxle "A signal which indicates different states of the steering axle";
CM_ SG_ 2565868542 AxleLocation "To identify to which of several similar devices (such as tires or fuel tanks) the information applies.";
CM_ SG_ 2565868542 ActualInnerWheelSteerAngle "Signal which indicates the actual inner wheel steering angle. See Figure SPN2927_A for explanation of positive and";
CM_ BO_ 2633941758 "Electronic Retarder Controller 2";
CM_ SG_ 2633941758 TransOutputRetarder "Identifies the status of the transmission output retarder.";
CM_ BO_ 2565865726 "NOTE- This message will be transmitted by several types of retarding devices such as engine compression release";
CM_ SG_ 2565865726 ActlMxAvlblRetarderPercentTorque "This is the maximum amount of torque that the retarder can immediately deliver. It is the same as the maximum torque";
CM_ SG_ 2565865726 RetarderSelectionNonengine "The “Retarder Selection, non-engine” is the position of the driver’s selector for retarders that are not part of the engine";
CM_ SG_ 2565865726 DrvrsDemandRetarderPercentTorque "The Drivers demand retarder – percent torque is the maximum torque selected by the driver when one or more modes";
CM_ SG_ 2565865726 SrcAddrssOfCntrllngDvcFrRtrdrCtr "The source address of the SAE J1939 device currently controlling the retarder. It is used to expand the torque mode";
CM_ SG_ 2565865726 RetarderRoadSpeedExceededStatus "Retarder Road Speed Exceeded Status:";
CM_ SG_ 2565865726 RetarderRoadSpeedLimitSwitch "Retarder road speed limit switch states:";
CM_ SG_ 2565865726 RetarderRequestingBrakeLight "Indicates that whether the retarder is requesting that the brake lights are illuminated.";
CM_ SG_ 2565865726 EngCoolantLoadIncrease "Status of an event, external to the engine, that may increase the nominal temperature of the engine coolant liquid.";
CM_ SG_ 2565865726 IntendedRetarderPercentTorque "Braking torque of retarder that the retarder is currently trying to achieve. This value takes into account all static";
CM_ SG_ 2565865726 ActualRetarderPercentTorque "Actual braking torque of the retarder as a percent of retarder configuration reference torque SPN 556.";
CM_ SG_ 2565865726 RetarderEnableShiftAssistSwitch "Switch signal which indicates whether the operator wishes the retarder to be enabled for transmission shift assist. The";
CM_ SG_ 2565865726 RetarderEnableBrakeAssistSwitch "Switch signal which indicates whether the operator wishes the retarder to be enabled for vehicle braking assist. The";
CM_ SG_ 2565865726 RetarderTorqueMode "State signal which indicates which retarder torque mode is currently generating, limiting, or controlling the torque. Note";
CM_ BO_ 2633932798 "Exhaust Port Temperature 5";
CM_ SG_ 2633932798 EngExhaustGasPort20Temp "Temperature at the cylinder exhaust port of the engine.";
CM_ SG_ 2633932798 EngExhaustGasPort19Temp "Temperature at the cylinder exhaust port of the engine.";
CM_ SG_ 2633932798 EngExhaustGasPort18Temp "Temperature at the cylinder exhaust port of the engine.";
CM_ SG_ 2633932798 EngExhaustGasPort17Temp "Temperature at the cylinder exhaust port of the engine.";
CM_ BO_ 2566824190 "Exhaust Port Temperature 4";
CM_ SG_ 2566824190 EngExhaustGasPort16Temp "Temperature at the cylinder exhaust port of the engine.";
CM_ SG_ 2566824190 EngExhaustGasPort15Temp "Temperature at the cylinder exhaust port of the engine.";
CM_ SG_ 2566824190 EngExhaustGasPort14Temp "Temperature at the cylinder exhaust port of the engine.";
CM_ SG_ 2566824190 EngExhaustGasPort13Temp "Temperature at the cylinder exhaust port of the engine.";
CM_ BO_ 2633933310 "Exhaust Port Temperature 3";
CM_ SG_ 2633933310 EngExhaustGasPort12Temp "Temperature at the cylinder exhaust port of the engine.";
CM_ SG_ 2633933310 EngExhaustGasPort11Temp "Temperature at the cylinder exhaust port of the engine.";
CM_ SG_ 2633933310 EngExhaustGasPort10Temp "Temperature at the cylinder exhaust port of the engine.";
CM_ SG_ 2633933310 EngExhaustGasPort9Temp "Temperature at the cylinder exhaust port of the engine.";
CM_ BO_ 2633933566 "Exhaust Port Temperature 2";
CM_ SG_ 2633933566 EngExhaustGasPort8Temp "Temperature at the cylinder exhaust port of the engine.";
CM_ SG_ 2633933566 EngExhaustGasPort7Temp "Temperature at the cylinder exhaust port of the engine.";
CM_ SG_ 2633933566 EngExhaustGasPort6Temp "Temperature at the cylinder exhaust port of the engine.";
CM_ SG_ 2633933566 EngExhaustGasPort5Temp "Temperature at the cylinder exhaust port of the engine.";
CM_ BO_ 2633933822 "Exhaust Port Temperature 1";
CM_ SG_ 2633933822 EngExhaustGasPort4Temp "Temperature at the cylinder exhaust port of the engine.";
CM_ SG_ 2633933822 EngExhaustGasPort3Temp "Temperature at the cylinder exhaust port of the engine.";
CM_ SG_ 2633933822 EngExhaustGasPort2Temp "Temperature at the cylinder exhaust port of the engine.";
CM_ SG_ 2633933822 EngExhaustGasPort1Temp "Temperature at the cylinder exhaust port of the engine.";
CM_ BO_ 2566776062 "Equipment Performance Data";
CM_ SG_ 2566776062 PayloadPercentage "The current payload of the equipment, reported as a percentage of the equipment's rated payload limit.";
CM_ BO_ 2566771454 "Message used to transfer ECU performance parameters.";
CM_ SG_ 2566771454 DataMemoryUsage "The used storage capacity of the data buffer memory internal to an ECU, such as a data logger.";
CM_ SG_ 2566771454 KeepAliveBatteryConsumption "The capacity consumed from the direct battery connection since the key was last turned off. This value is maintained and";
CM_ BO_ 2566775806 "Parameters related to the operation and controls for equipment";
CM_ SG_ 2566775806 TravelVelocityCtrlPos "The position of the travel velocity control component reported as a percentage of the control's full displacement in each";
CM_ SG_ 2633935358 EngExhstGsOxygnSnsrClsdLpOprtion "Indicates whether the engine is using the Exhaust Gas Oxygen sensor to control the air/fuel ratio.";
CM_ SG_ 2633935358 EngExhstGsOxygnSnsrFlngCrrection "The amount of fueling change required by the system based on the measured Exhaust Oxygen value compared to the";
CM_ SG_ 2633935358 EngActualExhaustOxygen "The actual amount of oxygen in the exhaust represented as a percentage by volume with respect to the total volume of";
CM_ SG_ 2633935358 EngDesiredExhaustOxygen "The desired amount of oxygen in the exhaust represented as a percentage by volume with respect to the total volume of";
CM_ SG_ 2633935358 EngDesiredRatedExhaustOxygen "The desired amount of oxygen in the exhaust at rated conditions represented as a percentage by volume with respect to";
CM_ BO_ 2365447166 "Extended Joystick Message 3";
CM_ SG_ 2365447166 Jystick3GripXAxisDetentPosStatus "Reports when the current joystick grip position is in the detent position for that axis of travel.";
CM_ SG_ 2365447166 Jystick3GripYAxisDetentPosStatus "Reports when the current joystick grip position is in the detent position for that axis of travel.";
CM_ SG_ 2365447166 Jystick3ThetaAxisDetentPosStatus "Reports when the current joystick position is in the detent position for that axis of travel.";
CM_ SG_ 2365447166 Joystick3ThetaAxisPos "The position of the joystick in the relative motion of travel from the neutral position. Position value of 0 is Neutral and";
CM_ SG_ 2365447166 Jystck3ThtAxsClckwsPstvPosStatus "Reports when the current joystick position is on the positive travel side (forward, right, clockwise, up) relative to the";
CM_ SG_ 2365447166 Jystck3ThetaAxisNeutralPosStatus "Reports when the current joystick position is in the neutral position for that axis of travel. The neutral position";
CM_ SG_ 2365447166 Joystick3GripYAxisPos "The position of the joystick grip in the relative motion of travel from the neutral position. Position value of 0 is Neutral and";
CM_ SG_ 2365447166 Jystck3GrpYAxsLvrFrwrdPstvPsStts "Reports when the current joystick grip position is on the positive travel side (forward, right, clockwise, up) relative to the";
CM_ SG_ 2365447166 Jystck3GrpYAxsLvrBckNgtvPsStatus "Reports when the current joystick grip position is on the negative travel side (back, left, counterclockwise, down) relative";
CM_ SG_ 2365447166 Jystck3GripYAxisNeutralPosStatus "Reports when the current joystick grip position is in the neutral position for that axis of travel. The neutral position";
CM_ SG_ 2365447166 Joystick3GripXAxisPos "The position of the joystick grip in the relative motion of travel from the neutral position. Position value of 0 is Neutral and";
CM_ SG_ 2365447166 Jystck3GrpXAxsLvrRghtPstvPsSttus "Reports when the current joystick grip position is on the positive travel side (forward, right, clockwise, up) relative to the";
CM_ SG_ 2365447166 Jystck3GrpXAxsLvrLftNgtvPsStatus "Reports when the current joystick grip position is on the negative travel side (back, left, counterclockwise, down) relative";
CM_ SG_ 2365447166 Jystck3GripXAxisNeutralPosStatus "Reports when the current joystick grip position is in the neutral position for that axis of travel. The neutral position";
CM_ SG_ 2365447166 Jystck3ThtAxsCntrClckwsNgtvPsStt "Reports when the current joystick position is on the negative travel side (back, left, counterclockwise, down) relative to the";
CM_ BO_ 2365446654 "Extended Joystick Message 2";
CM_ SG_ 2365446654 Jystick2GripXAxisDetentPosStatus "Reports when the current joystick grip position is in the detent position for that axis of travel.";
CM_ SG_ 2365446654 Jystick2GripYAxisDetentPosStatus "Reports when the current joystick grip position is in the detent position for that axis of travel.";
CM_ SG_ 2365446654 Jystick2ThetaAxisDetentPosStatus "Reports when the current joystick position is in the detent position for that axis of travel.";
CM_ SG_ 2365446654 Joystick2ThetaAxisPos "The position of the joystick in the relative motion of travel from the neutral position. Position value of 0 is Neutral and";
CM_ SG_ 2365446654 Jystck2ThtAxsClckwsPstvPosStatus "Reports when the current joystick position is on the positive travel side (forward, right, clockwise, up) relative to the";
CM_ SG_ 2365446654 Jystck2ThetaAxisNeutralPosStatus "Reports when the current joystick position is in the neutral position for that axis of travel. The neutral position";
CM_ SG_ 2365446654 Joystick2GripYAxisPos "The position of the joystick grip in the relative motion of travel from the neutral position. Position value of 0 is Neutral and";
CM_ SG_ 2365446654 Jystck2GrpYAxsLvrFrwrdPstvPsStts "Reports when the current joystick grip position is on the positive travel side (forward, right, clockwise, up) relative to the";
CM_ SG_ 2365446654 Jystck2GrpYAxsLvrBckNgtvPsStatus "Reports when the current joystick grip position is on the negative travel side (back, left, counterclockwise, down) relative";
CM_ SG_ 2365446654 Jystck2GripYAxisNeutralPosStatus "Reports when the current joystick grip position is in the neutral position for that axis of travel. The neutral position";
CM_ SG_ 2365446654 Joystick2GripXAxisPos "The position of the joystick grip in the relative motion of travel from the neutral position. Position value of 0 is Neutral and";
CM_ SG_ 2365446654 Jystck2GrpXAxsLvrRghtPstvPsSttus "Reports when the current joystick grip position is on the positive travel side (forward, right, clockwise, up) relative to the";
CM_ SG_ 2365446654 Jystck2GrpXAxsLvrLftNgtvPsStatus "Reports when the current joystick grip position is on the negative travel side (back, left, counterclockwise, down) relative";
CM_ SG_ 2365446654 Jystck2GripXAxisNeutralPosStatus "Reports when the current joystick grip position is in the neutral position for that axis of travel. The neutral position";
CM_ SG_ 2365446654 Jystck2ThtAxsCntrClckwsNgtvPsStt "Reports when the current joystick position is on the negative travel side (back, left, counterclockwise, down) relative to the";
BA_DEF_ BO_  "GenMsgCycleTimeFast" INT 0 3600000;
BA_DEF_ SG_  "SigType" ENUM  "Default","Range","RangeSigned","ASCII","Discrete","Control","ReferencePGN","DTC","StringDelimiter","StringLength","StringLengthControl";
BA_DEF_ SG_  "GenSigStartValue" INT 0 10000;
BA_DEF_ SG_  "GenSigSendType" ENUM  "Cyclic","OnWrite","reserved","OnChange","reserved","reserved","reserved","NoSigSendType";
BA_DEF_ SG_  "GenSigILSupport" ENUM  "Yes","No";
BA_DEF_ SG_  "GenSigEVName" STRING ;
BA_DEF_ SG_  "SPN" INT 0 524287;
BA_DEF_ SG_  "DDI" INT 0 65535;
BA_DEF_ SG_  "SAEDocument" STRING ;
BA_DEF_ BO_  "GenMsgStartDelayTime" INT 0 100000;
BA_DEF_ BO_  "GenMsgILSupport" ENUM  "Yes","No";
BA_DEF_ BO_  "GenMsgRequestable" INT 0 1;
BA_DEF_ BO_  "GenMsgSendType" ENUM  "cyclic","reserved","cyclicIfActive","reserved","reserved","reserved","reserved","reserved","noMsgSendType";
BA_DEF_ BO_  "VFrameFormat" ENUM  "StandardCAN","ExtendedCAN","reserved","J1939PG";
BA_DEF_ BO_  "SingleFrame" INT 0 1;
BA_DEF_ BO_  "GenMsgCycleTime" INT 0 3600000;
BA_DEF_ BO_  "SAE_Document" STRING ;
BA_DEF_ SG_  "SystemSignalLongSymbol" STRING ;
BA_DEF_DEF_  "GenMsgCycleTimeFast" 0;
BA_DEF_DEF_  "SigType" "Default";
BA_DEF_DEF_  "GenSigStartValue" 0;
BA_DEF_DEF_  "GenSigSendType" "NoSigSendType";
BA_DEF_DEF_  "GenSigILSupport" "Yes";
BA_DEF_DEF_  "GenSigEVName" "Env@Nodename_@Signame";
BA_DEF_DEF_  "SPN" 0;
BA_DEF_DEF_  "DDI" 0;
BA_DEF_DEF_  "SAEDocument" "";
BA_DEF_DEF_  "GenMsgStartDelayTime" 0;
BA_DEF_DEF_  "GenMsgILSupport" "Yes";
BA_DEF_DEF_  "GenMsgRequestable" 1;
BA_DEF_DEF_  "GenMsgSendType" "noMsgSendType";
BA_DEF_DEF_  "VFrameFormat" "J1939PG";
BA_DEF_DEF_  "SingleFrame" 1;
BA_DEF_DEF_  "GenMsgCycleTime" 0;
BA_DEF_DEF_  "SAE_Document" "";
BA_DEF_DEF_  "SystemSignalLongSymbol" "";
BA_ "SAE_Document" BO_ 2633895166 "J1939-81";
BA_ "SAE_Document" BO_ 2566832382 "J1939-71";
BA_ "SAE_Document" BO_ 2633928446 "J1939-71";
BA_ "GenMsgSendType" BO_ 2566804478 0;
BA_ "GenMsgCycleTime" BO_ 2566804478 5000;
BA_ "SAE_Document" BO_ 2566804478 "J1939-71";
BA_ "GenMsgSendType" BO_ 2566847486 0;
BA_ "GenMsgCycleTime" BO_ 2566847486 1000;
BA_ "SAE_Document" BO_ 2566847486 "J1939-71";
BA_ "SAE_Document" BO_ 2631859966 "J1939-71";
BA_ "GenMsgSendType" BO_ 2566840830 0;
BA_ "GenMsgCycleTime" BO_ 2566840830 5000;
BA_ "SAE_Document" BO_ 2566840830 "J1939-71";
BA_ "SAE_Document" BO_ 2633930238 "J1939-71";
BA_ "GenMsgSendType" BO_ 2566844670 0;
BA_ "GenMsgCycleTime" BO_ 2566844670 100;
BA_ "SAE_Document" BO_ 2566844670 "J1939-71";
BA_ "GenMsgSendType" BO_ 2566770174 0;
BA_ "GenMsgCycleTime" BO_ 2566770174 200;
BA_ "SAE_Document" BO_ 2566770174 "J1939-71";
BA_ "GenMsgSendType" BO_ 2566769662 0;
BA_ "GenMsgCycleTime" BO_ 2566769662 500;
BA_ "SAE_Document" BO_ 2566769662 "J1939-71";
BA_ "GenMsgSendType" BO_ 2566768638 0;
BA_ "GenMsgCycleTime" BO_ 2566768638 5000;
BA_ "SAE_Document" BO_ 2566768638 "J1939-71";
BA_ "GenMsgSendType" BO_ 2365443326 0;
BA_ "GenMsgCycleTime" BO_ 2365443326 1000;
BA_ "SAE_Document" BO_ 2365443326 "J1939-71";
BA_ "GenMsgSendType" BO_ 2566776318 0;
BA_ "GenMsgCycleTime" BO_ 2566776318 1000;
BA_ "SAE_Document" BO_ 2566776318 "J1939-71";
BA_ "GenMsgSendType" BO_ 2566802686 0;
BA_ "GenMsgCycleTime" BO_ 2566802686 100;
BA_ "SAE_Document" BO_ 2566802686 "J1939-71";
BA_ "GenMsgSendType" BO_ 2566774014 0;
BA_ "GenMsgCycleTime" BO_ 2566774014 1000;
BA_ "SAE_Document" BO_ 2566774014 "J1939-71";
BA_ "GenMsgSendType" BO_ 2566823166 0;
BA_ "GenMsgCycleTime" BO_ 2566823166 1000;
BA_ "SAE_Document" BO_ 2566823166 "J1939-71";
BA_ "GenMsgSendType" BO_ 2566823422 0;
BA_ "GenMsgCycleTime" BO_ 2566823422 1000;
BA_ "SAE_Document" BO_ 2566823422 "J1939-71";
BA_ "GenMsgSendType" BO_ 2566823678 0;
BA_ "GenMsgCycleTime" BO_ 2566823678 1000;
BA_ "SAE_Document" BO_ 2566823678 "J1939-71";
BA_ "GenMsgSendType" BO_ 2432595710 0;
BA_ "GenMsgCycleTime" BO_ 2432595710 100;
BA_ "SAE_Document" BO_ 2432595710 "J1939-71";
BA_ "GenMsgSendType" BO_ 2365486590 0;
BA_ "GenMsgCycleTime" BO_ 2365486590 50;
BA_ "SAE_Document" BO_ 2365486590 "J1939-71";
BA_ "GenMsgSendType" BO_ 2365485566 0;
BA_ "GenMsgCycleTime" BO_ 2365485566 50;
BA_ "SAE_Document" BO_ 2365485566 "J1939-71";
BA_ "SAE_Document" BO_ 2633939454 "J1939-71";
BA_ "GenMsgSendType" BO_ 2365486334 0;
BA_ "GenMsgCycleTime" BO_ 2365486334 50;
BA_ "SAE_Document" BO_ 2365486334 "J1939-71";
BA_ "GenMsgSendType" BO_ 2364542462 0;
BA_ "GenMsgCycleTime" BO_ 2364542462 100;
BA_ "SAE_Document" BO_ 2364542462 "J1939-71";
BA_ "GenMsgSendType" BO_ 2365486078 0;
BA_ "GenMsgCycleTime" BO_ 2365486078 50;
BA_ "SAE_Document" BO_ 2365486078 "J1939-71";
BA_ "SAE_Document" BO_ 2633937918 "J1939-71";
BA_ "GenMsgSendType" BO_ 2566845182 0;
BA_ "GenMsgCycleTime" BO_ 2566845182 100;
BA_ "SAE_Document" BO_ 2566845182 "J1939-71";
BA_ "SAE_Document" BO_ 2566842878 "J1939-71";
BA_ "GenMsgSendType" BO_ 2633883646 0;
BA_ "GenMsgCycleTime" BO_ 2633883646 5000;
BA_ "SAE_Document" BO_ 2633883646 "J1939-71";
BA_ "GenMsgSendType" BO_ 2633880062 0;
BA_ "GenMsgCycleTime" BO_ 2633880062 10000;
BA_ "SAE_Document" BO_ 2633880062 "J1939-71";
BA_ "GenMsgSendType" BO_ 2566806526 0;
BA_ "GenMsgCycleTime" BO_ 2566806526 100;
BA_ "SAE_Document" BO_ 2566806526 "J1939-71";
BA_ "GenMsgSendType" BO_ 2431649790 2;
BA_ "GenMsgCycleTime" BO_ 2431649790 50;
BA_ "SAE_Document" BO_ 2431649790 "J1939-71";
BA_ "GenMsgSendType" BO_ 2633929214 0;
BA_ "GenMsgCycleTime" BO_ 2633929214 1000;
BA_ "SAE_Document" BO_ 2633929214 "J1939-71";
BA_ "GenMsgSendType" BO_ 2566831614 0;
BA_ "GenMsgCycleTime" BO_ 2566831614 1000;
BA_ "SAE_Document" BO_ 2566831614 "J1939-71";
BA_ "SAE_Document" BO_ 2566820094 "J1939-71";
BA_ "GenMsgSendType" BO_ 2364542206 0;
BA_ "GenMsgCycleTime" BO_ 2364542206 20;
BA_ "SAE_Document" BO_ 2364542206 "J1939-71";
BA_ "GenMsgSendType" BO_ 2566802174 0;
BA_ "GenMsgCycleTime" BO_ 2566802174 100;
BA_ "SAE_Document" BO_ 2566802174 "J1939-71";
BA_ "SAE_Document" BO_ 2633935870 "J1939-71";
BA_ "SAE_Document" BO_ 2633942014 "J1939-71";
BA_ "SAE_Document" BO_ 2633942526 "J1939-71";
BA_ "SAE_Document" BO_ 2633943038 "J1939-71";
BA_ "GenMsgSendType" BO_ 2565867006 0;
BA_ "GenMsgCycleTime" BO_ 2565867006 100;
BA_ "SAE_Document" BO_ 2565867006 "J1939-71";
BA_ "GenMsgSendType" BO_ 2364539646 0;
BA_ "GenMsgCycleTime" BO_ 2364539646 10;
BA_ "SAE_Document" BO_ 2364539646 "J1939-71";
BA_ "GenMsgSendType" BO_ 2566810110 0;
BA_ "GenMsgCycleTime" BO_ 2566810110 1000;
BA_ "SAE_Document" BO_ 2566810110 "J1939-71";
BA_ "GenMsgSendType" BO_ 2566825214 0;
BA_ "GenMsgCycleTime" BO_ 2566825214 1000;
BA_ "SAE_Document" BO_ 2566825214 "J1939-71";
BA_ "GenMsgSendType" BO_ 2566844158 0;
BA_ "GenMsgCycleTime" BO_ 2566844158 1000;
BA_ "SAE_Document" BO_ 2566844158 "J1939-71";
BA_ "GenMsgSendType" BO_ 2566785022 0;
BA_ "GenMsgCycleTime" BO_ 2566785022 5000;
BA_ "SAE_Document" BO_ 2566785022 "J1939-71";
BA_ "GenMsgSendType" BO_ 2565868542 0;
BA_ "GenMsgCycleTime" BO_ 2565868542 20;
BA_ "SAE_Document" BO_ 2565868542 "J1939-71";
BA_ "GenMsgSendType" BO_ 2633941758 2;
BA_ "GenMsgCycleTime" BO_ 2633941758 1000;
BA_ "SAE_Document" BO_ 2633941758 "J1939-71";
BA_ "GenMsgSendType" BO_ 2565865726 0;
BA_ "GenMsgCycleTime" BO_ 2565865726 100;
BA_ "SAE_Document" BO_ 2565865726 "J1939-71";
BA_ "GenMsgSendType" BO_ 2633932798 0;
BA_ "GenMsgCycleTime" BO_ 2633932798 1000;
BA_ "SAE_Document" BO_ 2633932798 "J1939-71";
BA_ "GenMsgSendType" BO_ 2566824190 0;
BA_ "GenMsgCycleTime" BO_ 2566824190 1000;
BA_ "SAE_Document" BO_ 2566824190 "J1939-71";
BA_ "GenMsgSendType" BO_ 2633933310 0;
BA_ "GenMsgCycleTime" BO_ 2633933310 1000;
BA_ "SAE_Document" BO_ 2633933310 "J1939-71";
BA_ "GenMsgSendType" BO_ 2633933566 0;
BA_ "GenMsgCycleTime" BO_ 2633933566 1000;
BA_ "SAE_Document" BO_ 2633933566 "J1939-71";
BA_ "GenMsgSendType" BO_ 2633933822 0;
BA_ "GenMsgCycleTime" BO_ 2633933822 1000;
BA_ "SAE_Document" BO_ 2633933822 "J1939-71";
BA_ "GenMsgSendType" BO_ 2566776062 0;
BA_ "GenMsgCycleTime" BO_ 2566776062 500;
BA_ "SAE_Document" BO_ 2566776062 "J1939-71";
BA_ "SAE_Document" BO_ 2566771454 "J1939-71";
BA_ "SAE_Document" BO_ 2566775806 "J1939-71";
BA_ "SAE_Document" BO_ 2633935358 "J1939-71";
BA_ "GenMsgSendType" BO_ 2365447166 0;
BA_ "GenMsgCycleTime" BO_ 2365447166 100;
BA_ "SAE_Document" BO_ 2365447166 "J1939-71";
BA_ "GenMsgSendType" BO_ 2365446654 0;
BA_ "GenMsgCycleTime" BO_ 2365446654 100;
BA_ "SAE_Document" BO_ 2365446654 "J1939-71";
BA_ "SAEDocument" SG_ 2633895166 VehicleSystem5 "J1939-81";
BA_ "SAEDocument" SG_ 2633895166 VehicleSystem4 "J1939-81";
BA_ "SAEDocument" SG_ 2633895166 VehicleSystem3 "J1939-81";
BA_ "SAEDocument" SG_ 2633895166 VehicleSystem2 "J1939-81";
BA_ "SAEDocument" SG_ 2633895166 VehicleSystem1 "J1939-81";
BA_ "SPN" SG_ 2633895166 ArbitraryAddressCapable 2844;
BA_ "SAEDocument" SG_ 2633895166 ArbitraryAddressCapable "J1939-81";
BA_ "SPN" SG_ 2633895166 IndustryGroup 2846;
BA_ "SAEDocument" SG_ 2633895166 IndustryGroup "NMEA2000";
BA_ "SPN" SG_ 2633895166 VehicleSystemInstance 2843;
BA_ "SAEDocument" SG_ 2633895166 VehicleSystemInstance "J1939-81";
BA_ "SAEDocument" SG_ 2633895166 VehicleSystem "J1939-81";
BA_ "SPN" SG_ 2633895166 ECUInstance 2840;
BA_ "SAEDocument" SG_ 2633895166 ECUInstance "J1939-81";
BA_ "SPN" SG_ 2633895166 FunctionInstance 2839;
BA_ "SAEDocument" SG_ 2633895166 FunctionInstance "J1939-81";
BA_ "SPN" SG_ 2633895166 Function 2841;
BA_ "SAEDocument" SG_ 2633895166 Function "J1939-81";
BA_ "SigType" SG_ 2633895166 ManufacturerCode 1;
BA_ "SPN" SG_ 2633895166 ManufacturerCode 2838;
BA_ "SAEDocument" SG_ 2633895166 ManufacturerCode "NMEA2000";
BA_ "SPN" SG_ 2633895166 IdentityNumber 2837;
BA_ "SAEDocument" SG_ 2633895166 IdentityNumber "J1939-81";
BA_ "SigType" SG_ 2566832382 SrviceDelay_OperationalTimeBased 1;
BA_ "SPN" SG_ 2566832382 SrviceDelay_OperationalTimeBased 916;
BA_ "SAEDocument" SG_ 2566832382 SrviceDelay_OperationalTimeBased "J1939-71";
BA_ "SigType" SG_ 2566832382 ServiceComponentIdentification 1;
BA_ "SPN" SG_ 2566832382 ServiceComponentIdentification 911;
BA_ "SAEDocument" SG_ 2566832382 ServiceComponentIdentification "J1939-71";
BA_ "SigType" SG_ 2566832382 ServiceDelay_CalendarTimeBased 1;
BA_ "SPN" SG_ 2566832382 ServiceDelay_CalendarTimeBased 915;
BA_ "SAEDocument" SG_ 2566832382 ServiceDelay_CalendarTimeBased "J1939-71";
BA_ "SigType" SG_ 2566832382 ServiceDistance 1;
BA_ "SPN" SG_ 2566832382 ServiceDistance 914;
BA_ "SAEDocument" SG_ 2566832382 ServiceDistance "J1939-71";
BA_ "SigType" SG_ 2633928446 TimeSinceLastService 1;
BA_ "SPN" SG_ 2633928446 TimeSinceLastService 1350;
BA_ "SAEDocument" SG_ 2633928446 TimeSinceLastService "J1939-71";
BA_ "SigType" SG_ 2633928446 ServiceComponentIdentification 1;
BA_ "SPN" SG_ 2633928446 ServiceComponentIdentification 1379;
BA_ "SAEDocument" SG_ 2633928446 ServiceComponentIdentification "J1939-71";
BA_ "SPN" SG_ 2566804478 MinContinuousRetarderTorque 1783;
BA_ "SAEDocument" SG_ 2566804478 MinContinuousRetarderTorque "J1939-71";
BA_ "SPN" SG_ 2566804478 MaxContinuousRetarderTorque 1782;
BA_ "SAEDocument" SG_ 2566804478 MaxContinuousRetarderTorque "J1939-71";
BA_ "SPN" SG_ 2566804478 MinContinuousRetarderSpeed 1781;
BA_ "SAEDocument" SG_ 2566804478 MinContinuousRetarderSpeed "J1939-71";
BA_ "SPN" SG_ 2566804478 MaxContinuousRetarderSpeed 1780;
BA_ "SAEDocument" SG_ 2566804478 MaxContinuousRetarderSpeed "J1939-71";
BA_ "SPN" SG_ 2566804478 HghLmtThrshldFrMnCntnsTrqFrmRtrd 1779;
BA_ "SAEDocument" SG_ 2566804478 HghLmtThrshldFrMnCntnsTrqFrmRtrd "J1939-71";
BA_ "SPN" SG_ 2566804478 LwLmtThrshldFrMxTrqeFromRetarder 1778;
BA_ "SAEDocument" SG_ 2566804478 LwLmtThrshldFrMxTrqeFromRetarder "J1939-71";
BA_ "SPN" SG_ 2566804478 HghLmtThrshldFrMnCntnsRPMFrmRtrd 1777;
BA_ "SAEDocument" SG_ 2566804478 HghLmtThrshldFrMnCntnsRPMFrmRtrd "J1939-71";
BA_ "SPN" SG_ 2566804478 LwLmtThrshldFrMaxRPMFromRetarder 1776;
BA_ "SAEDocument" SG_ 2566804478 LwLmtThrshldFrMaxRPMFromRetarder "J1939-71";
BA_ "SigType" SG_ 2566847486 DrvlineRetarderOverheatIndicator 5;
BA_ "SPN" SG_ 2566847486 DrvlineRetarderOverheatIndicator 5346;
BA_ "SAEDocument" SG_ 2566847486 DrvlineRetarderOverheatIndicator "J1939-71";
BA_ "SigType" SG_ 2566847486 HydRetarderOilTemp 1;
BA_ "SPN" SG_ 2566847486 HydRetarderOilTemp 120;
BA_ "SAEDocument" SG_ 2566847486 HydRetarderOilTemp "J1939-71";
BA_ "SigType" SG_ 2566847486 HydRetarderPress 1;
BA_ "SPN" SG_ 2566847486 HydRetarderPress 119;
BA_ "SAEDocument" SG_ 2566847486 HydRetarderPress "J1939-71";
BA_ "SigType" SG_ 2631859966 SteerStraightAheadPosReset 5;
BA_ "SPN" SG_ 2631859966 SteerStraightAheadPosReset 3600;
BA_ "SAEDocument" SG_ 2631859966 SteerStraightAheadPosReset "J1939-71";
BA_ "SigType" SG_ 2631859966 EngBuildHoursReset 5;
BA_ "SPN" SG_ 2631859966 EngBuildHoursReset 1211;
BA_ "SAEDocument" SG_ 2631859966 EngBuildHoursReset "J1939-71";
BA_ "SigType" SG_ 2631859966 ServiceComponentIdentification 1;
BA_ "SPN" SG_ 2631859966 ServiceComponentIdentification 1584;
BA_ "SAEDocument" SG_ 2631859966 ServiceComponentIdentification "J1939-71";
BA_ "SigType" SG_ 2631859966 TripGroup2Proprietary 5;
BA_ "SPN" SG_ 2631859966 TripGroup2Proprietary 989;
BA_ "SAEDocument" SG_ 2631859966 TripGroup2Proprietary "J1939-71";
BA_ "SigType" SG_ 2631859966 TripGroup1 5;
BA_ "SPN" SG_ 2631859966 TripGroup1 988;
BA_ "SAEDocument" SG_ 2631859966 TripGroup1 "J1939-71";
BA_ "SigType" SG_ 2566840830 PercentTorqueAtPeakTorquePoint5 1;
BA_ "SPN" SG_ 2566840830 PercentTorqueAtPeakTorquePoint5 555;
BA_ "SAEDocument" SG_ 2566840830 PercentTorqueAtPeakTorquePoint5 "J1939-71";
BA_ "SigType" SG_ 2566840830 ReferenceRetarderTorque 1;
BA_ "SPN" SG_ 2566840830 ReferenceRetarderTorque 556;
BA_ "SAEDocument" SG_ 2566840830 ReferenceRetarderTorque "J1939-71";
BA_ "SigType" SG_ 2566840830 RetarderSpeedAtPeakTorquePoint5 1;
BA_ "SPN" SG_ 2566840830 RetarderSpeedAtPeakTorquePoint5 547;
BA_ "SAEDocument" SG_ 2566840830 RetarderSpeedAtPeakTorquePoint5 "J1939-71";
BA_ "SigType" SG_ 2566840830 PercentTorqueAtPoint4 1;
BA_ "SPN" SG_ 2566840830 PercentTorqueAtPoint4 554;
BA_ "SAEDocument" SG_ 2566840830 PercentTorqueAtPoint4 "J1939-71";
BA_ "SigType" SG_ 2566840830 RetarderSpeedAtPoint4 1;
BA_ "SPN" SG_ 2566840830 RetarderSpeedAtPoint4 550;
BA_ "SAEDocument" SG_ 2566840830 RetarderSpeedAtPoint4 "J1939-71";
BA_ "SigType" SG_ 2566840830 PercentTorqueAtPoint3 1;
BA_ "SPN" SG_ 2566840830 PercentTorqueAtPoint3 553;
BA_ "SAEDocument" SG_ 2566840830 PercentTorqueAtPoint3 "J1939-71";
BA_ "SigType" SG_ 2566840830 RetarderSpeedAtPoint3 1;
BA_ "SPN" SG_ 2566840830 RetarderSpeedAtPoint3 549;
BA_ "SAEDocument" SG_ 2566840830 RetarderSpeedAtPoint3 "J1939-71";
BA_ "SigType" SG_ 2566840830 PercentTorqueAtMaxSpeedPoint2 1;
BA_ "SPN" SG_ 2566840830 PercentTorqueAtMaxSpeedPoint2 552;
BA_ "SAEDocument" SG_ 2566840830 PercentTorqueAtMaxSpeedPoint2 "J1939-71";
BA_ "SigType" SG_ 2566840830 MaxRetarderSpeedPoint2 1;
BA_ "SPN" SG_ 2566840830 MaxRetarderSpeedPoint2 548;
BA_ "SAEDocument" SG_ 2566840830 MaxRetarderSpeedPoint2 "J1939-71";
BA_ "SigType" SG_ 2566840830 PercentTorqueAtIdlePoint1 1;
BA_ "SPN" SG_ 2566840830 PercentTorqueAtIdlePoint1 551;
BA_ "SAEDocument" SG_ 2566840830 PercentTorqueAtIdlePoint1 "J1939-71";
BA_ "SigType" SG_ 2566840830 RetarderSpeedAtIdlePoint1 1;
BA_ "SPN" SG_ 2566840830 RetarderSpeedAtIdlePoint1 546;
BA_ "SAEDocument" SG_ 2566840830 RetarderSpeedAtIdlePoint1 "J1939-71";
BA_ "SigType" SG_ 2566840830 RetarderCtrlMethod 1;
BA_ "SPN" SG_ 2566840830 RetarderCtrlMethod 557;
BA_ "SAEDocument" SG_ 2566840830 RetarderCtrlMethod "J1939-71";
BA_ "SPN" SG_ 2566840830 RetarderLocation 902;
BA_ "SAEDocument" SG_ 2566840830 RetarderLocation "J1939-71";
BA_ "SPN" SG_ 2566840830 RetarderType 901;
BA_ "SAEDocument" SG_ 2566840830 RetarderType "J1939-71";
BA_ "SigType" SG_ 2633930238 EngOperationTimeSinceRebuild 1;
BA_ "SPN" SG_ 2633930238 EngOperationTimeSinceRebuild 1193;
BA_ "SAEDocument" SG_ 2633930238 EngOperationTimeSinceRebuild "J1939-71";
BA_ "SigType" SG_ 2566844670 PowerTakeoffSetSpeed 1;
BA_ "SPN" SG_ 2566844670 PowerTakeoffSetSpeed 187;
BA_ "SAEDocument" SG_ 2566844670 PowerTakeoffSetSpeed "J1939-71";
BA_ "SigType" SG_ 2566844670 PowerTakeoffSpeed 1;
BA_ "SPN" SG_ 2566844670 PowerTakeoffSpeed 186;
BA_ "SAEDocument" SG_ 2566844670 PowerTakeoffSpeed "J1939-71";
BA_ "SigType" SG_ 2566844670 PowerTakeoffOilTemp 1;
BA_ "SPN" SG_ 2566844670 PowerTakeoffOilTemp 90;
BA_ "SAEDocument" SG_ 2566844670 PowerTakeoffOilTemp "J1939-71";
BA_ "SigType" SG_ 2566844670 OprtrEngPTOGvrnrMmrySelectSwitch 4;
BA_ "SPN" SG_ 2566844670 OprtrEngPTOGvrnrMmrySelectSwitch 2897;
BA_ "SAEDocument" SG_ 2566844670 OprtrEngPTOGvrnrMmrySelectSwitch "J1939-71";
BA_ "SigType" SG_ 2566844670 EngRmtPTOGvrnrVrblSpedCtrlSwitch 4;
BA_ "SPN" SG_ 2566844670 EngRmtPTOGvrnrVrblSpedCtrlSwitch 978;
BA_ "SAEDocument" SG_ 2566844670 EngRmtPTOGvrnrVrblSpedCtrlSwitch "J1939-71";
BA_ "SigType" SG_ 2566844670 EngRmtPTOGvrnrPrprgrmmdSpdCtrlSw 4;
BA_ "SPN" SG_ 2566844670 EngRmtPTOGvrnrPrprgrmmdSpdCtrlSw 979;
BA_ "SAEDocument" SG_ 2566844670 EngRmtPTOGvrnrPrprgrmmdSpdCtrlSw "J1939-71";
BA_ "SigType" SG_ 2566844670 EngPTOGvrnrCast_DecelerateSwitch 4;
BA_ "SPN" SG_ 2566844670 EngPTOGvrnrCast_DecelerateSwitch 983;
BA_ "SAEDocument" SG_ 2566844670 EngPTOGvrnrCast_DecelerateSwitch "J1939-71";
BA_ "SigType" SG_ 2566844670 EngPTOGovernorSetSwitch 4;
BA_ "SPN" SG_ 2566844670 EngPTOGovernorSetSwitch 984;
BA_ "SAEDocument" SG_ 2566844670 EngPTOGovernorSetSwitch "J1939-71";
BA_ "SigType" SG_ 2566844670 EngPTOGovernorResumeSwitch 4;
BA_ "SPN" SG_ 2566844670 EngPTOGovernorResumeSwitch 982;
BA_ "SAEDocument" SG_ 2566844670 EngPTOGovernorResumeSwitch "J1939-71";
BA_ "SigType" SG_ 2566844670 EngPTOGovernorEnableSwitch 4;
BA_ "SPN" SG_ 2566844670 EngPTOGovernorEnableSwitch 980;
BA_ "SAEDocument" SG_ 2566844670 EngPTOGovernorEnableSwitch "J1939-71";
BA_ "SigType" SG_ 2566844670 EngPTOGovernorAccelerateSwitch 4;
BA_ "SPN" SG_ 2566844670 EngPTOGovernorAccelerateSwitch 981;
BA_ "SAEDocument" SG_ 2566844670 EngPTOGovernorAccelerateSwitch "J1939-71";
BA_ "SigType" SG_ 2566844670 RmtPTOGvrnrPrprgrmmdSpdCtrlSwtch 4;
BA_ "SPN" SG_ 2566844670 RmtPTOGvrnrPrprgrmmdSpdCtrlSwtch 3447;
BA_ "SAEDocument" SG_ 2566844670 RmtPTOGvrnrPrprgrmmdSpdCtrlSwtch "J1939-71";
BA_ "SigType" SG_ 2566844670 AuxInputIgnoreSwitch 4;
BA_ "SPN" SG_ 2566844670 AuxInputIgnoreSwitch 3448;
BA_ "SAEDocument" SG_ 2566844670 AuxInputIgnoreSwitch "J1939-71";
BA_ "SPN" SG_ 2566770174 RearWasherFunction 2868;
BA_ "SAEDocument" SG_ 2566770174 RearWasherFunction "J1939-71";
BA_ "SPN" SG_ 2566770174 FrontOperatorWasherSwitch 2866;
BA_ "SAEDocument" SG_ 2566770174 FrontOperatorWasherSwitch "J1939-71";
BA_ "SPN" SG_ 2566770174 FrontNonoperatorWasherSwitch 2867;
BA_ "SAEDocument" SG_ 2566770174 FrontNonoperatorWasherSwitch "J1939-71";
BA_ "SigType" SG_ 2566770174 RearWiperDelayCtrl 1;
BA_ "SPN" SG_ 2566770174 RearWiperDelayCtrl 2871;
BA_ "SAEDocument" SG_ 2566770174 RearWiperDelayCtrl "J1939-71";
BA_ "SigType" SG_ 2566770174 FrontNonoperatorWiperDelayCtrl 1;
BA_ "SPN" SG_ 2566770174 FrontNonoperatorWiperDelayCtrl 2870;
BA_ "SAEDocument" SG_ 2566770174 FrontNonoperatorWiperDelayCtrl "J1939-71";
BA_ "SigType" SG_ 2566770174 FrontOperatorWiperDelayCtrl 1;
BA_ "SPN" SG_ 2566770174 FrontOperatorWiperDelayCtrl 2869;
BA_ "SAEDocument" SG_ 2566770174 FrontOperatorWiperDelayCtrl "J1939-71";
BA_ "SPN" SG_ 2566770174 RearWiperSwitch 2865;
BA_ "SAEDocument" SG_ 2566770174 RearWiperSwitch "J1939-71";
BA_ "SPN" SG_ 2566770174 FrontOperatorWiperSwitch 2863;
BA_ "SAEDocument" SG_ 2566770174 FrontOperatorWiperSwitch "J1939-71";
BA_ "SPN" SG_ 2566770174 FrontNonoperatorWiperSwitch 2864;
BA_ "SAEDocument" SG_ 2566770174 FrontNonoperatorWiperSwitch "J1939-71";
BA_ "SPN" SG_ 2566769662 EngAltDroopAuxInputSelect 2885;
BA_ "SAEDocument" SG_ 2566769662 EngAltDroopAuxInputSelect "J1939-71";
BA_ "SPN" SG_ 2566769662 EngAltDroopRemoteAccelSelect 2886;
BA_ "SAEDocument" SG_ 2566769662 EngAltDroopRemoteAccelSelect "J1939-71";
BA_ "SPN" SG_ 2566769662 EngAltDroopAccel2Select 2879;
BA_ "SAEDocument" SG_ 2566769662 EngAltDroopAccel2Select "J1939-71";
BA_ "SPN" SG_ 2566769662 EngAltDroopAccel1Select 2881;
BA_ "SAEDocument" SG_ 2566769662 EngAltDroopAccel1Select "J1939-71";
BA_ "SigType" SG_ 2566769662 EngAltRatingSelect 1;
BA_ "SPN" SG_ 2566769662 EngAltRatingSelect 2882;
BA_ "SAEDocument" SG_ 2566769662 EngAltRatingSelect "J1939-71";
BA_ "SigType" SG_ 2566769662 EngAltLowIdleSwitch 4;
BA_ "SPN" SG_ 2566769662 EngAltLowIdleSwitch 2883;
BA_ "SAEDocument" SG_ 2566769662 EngAltLowIdleSwitch "J1939-71";
BA_ "SigType" SG_ 2566769662 EngSynchronizationSwitch 4;
BA_ "SPN" SG_ 2566769662 EngSynchronizationSwitch 1377;
BA_ "SAEDocument" SG_ 2566769662 EngSynchronizationSwitch "J1939-71";
BA_ "SigType" SG_ 2566769662 EngAuxGovernorSwitch 4;
BA_ "SPN" SG_ 2566769662 EngAuxGovernorSwitch 2884;
BA_ "SAEDocument" SG_ 2566769662 EngAuxGovernorSwitch "J1939-71";
BA_ "SPN" SG_ 2566768638 EngAltDroopAuxInputSelectState 2895;
BA_ "SAEDocument" SG_ 2566768638 EngAltDroopAuxInputSelectState "J1939-71";
BA_ "SPN" SG_ 2566768638 EngAltDropRemoteAccelSelectState 2894;
BA_ "SAEDocument" SG_ 2566768638 EngAltDropRemoteAccelSelectState "J1939-71";
BA_ "SPN" SG_ 2566768638 EngAltDroopAccel2SelectState 2893;
BA_ "SAEDocument" SG_ 2566768638 EngAltDroopAccel2SelectState "J1939-71";
BA_ "SPN" SG_ 2566768638 EngAltDroopAccel1SelectState 2889;
BA_ "SAEDocument" SG_ 2566768638 EngAltDroopAccel1SelectState "J1939-71";
BA_ "SPN" SG_ 2566768638 EngAltRatingSelectState 2888;
BA_ "SAEDocument" SG_ 2566768638 EngAltRatingSelectState "J1939-71";
BA_ "SigType" SG_ 2566768638 EngAltLowIdleSelectState 5;
BA_ "SPN" SG_ 2566768638 EngAltLowIdleSelectState 2891;
BA_ "SAEDocument" SG_ 2566768638 EngAltLowIdleSelectState "J1939-71";
BA_ "SigType" SG_ 2566768638 EngMultiUnitSyncState 5;
BA_ "SPN" SG_ 2566768638 EngMultiUnitSyncState 2890;
BA_ "SAEDocument" SG_ 2566768638 EngMultiUnitSyncState "J1939-71";
BA_ "SigType" SG_ 2566768638 EngAuxGovernorState 5;
BA_ "SPN" SG_ 2566768638 EngAuxGovernorState 2896;
BA_ "SAEDocument" SG_ 2566768638 EngAuxGovernorState "J1939-71";
BA_ "SigType" SG_ 2365443326 OprtorsDesiredDelayedLampOffTime 1;
BA_ "SPN" SG_ 2365443326 OprtorsDesiredDelayedLampOffTime 2877;
BA_ "SAEDocument" SG_ 2365443326 OprtorsDesiredDelayedLampOffTime "J1939-71";
BA_ "SigType" SG_ 2365443326 OperatorsDesiredBacklight 1;
BA_ "SPN" SG_ 2365443326 OperatorsDesiredBacklight 2878;
BA_ "SAEDocument" SG_ 2365443326 OperatorsDesiredBacklight "J1939-71";
BA_ "SigType" SG_ 2365443326 HighLowBeamSwitch 4;
BA_ "SPN" SG_ 2365443326 HighLowBeamSwitch 2874;
BA_ "SAEDocument" SG_ 2365443326 HighLowBeamSwitch "J1939-71";
BA_ "SigType" SG_ 2365443326 HazardLightSwitch 4;
BA_ "SPN" SG_ 2365443326 HazardLightSwitch 2875;
BA_ "SAEDocument" SG_ 2365443326 HazardLightSwitch "J1939-71";
BA_ "SPN" SG_ 2365443326 TurnSignalSwitch 2876;
BA_ "SAEDocument" SG_ 2365443326 TurnSignalSwitch "J1939-71";
BA_ "SPN" SG_ 2365443326 MainLightSwitch 2872;
BA_ "SAEDocument" SG_ 2365443326 MainLightSwitch "J1939-71";
BA_ "SPN" SG_ 2365443326 WorkLightSwitch 2873;
BA_ "SAEDocument" SG_ 2365443326 WorkLightSwitch "J1939-71";
BA_ "SPN" SG_ 2566776318 AppliedVehicleSpeedLimit 2595;
BA_ "SAEDocument" SG_ 2566776318 AppliedVehicleSpeedLimit "J1939-71";
BA_ "SPN" SG_ 2566776318 MaxVehicleSpeedLimit7 2594;
BA_ "SAEDocument" SG_ 2566776318 MaxVehicleSpeedLimit7 "J1939-71";
BA_ "SPN" SG_ 2566776318 MaxVehicleSpeedLimit6 2593;
BA_ "SAEDocument" SG_ 2566776318 MaxVehicleSpeedLimit6 "J1939-71";
BA_ "SPN" SG_ 2566776318 MaxVehicleSpeedLimit5 2592;
BA_ "SAEDocument" SG_ 2566776318 MaxVehicleSpeedLimit5 "J1939-71";
BA_ "SPN" SG_ 2566776318 MaxVehicleSpeedLimit4 2591;
BA_ "SAEDocument" SG_ 2566776318 MaxVehicleSpeedLimit4 "J1939-71";
BA_ "SPN" SG_ 2566776318 MaxVehicleSpeedLimit3 2590;
BA_ "SAEDocument" SG_ 2566776318 MaxVehicleSpeedLimit3 "J1939-71";
BA_ "SPN" SG_ 2566776318 MaxVehicleSpeedLimit2 2589;
BA_ "SAEDocument" SG_ 2566776318 MaxVehicleSpeedLimit2 "J1939-71";
BA_ "SPN" SG_ 2566776318 MaxVehicleSpeedLimit1 2588;
BA_ "SAEDocument" SG_ 2566776318 MaxVehicleSpeedLimit1 "J1939-71";
BA_ "SPN" SG_ 2566802686 OprtrsBlackOutIntensitySelection 1844;
BA_ "SAEDocument" SG_ 2566802686 OprtrsBlackOutIntensitySelection "J1939-71";
BA_ "SigType" SG_ 2566802686 BlackOutWorkLampSelect 5;
BA_ "SPN" SG_ 2566802686 BlackOutWorkLampSelect 1842;
BA_ "SAEDocument" SG_ 2566802686 BlackOutWorkLampSelect "J1939-71";
BA_ "SigType" SG_ 2566802686 NightVisionIlluminatorSelect 5;
BA_ "SPN" SG_ 2566802686 NightVisionIlluminatorSelect 1843;
BA_ "SAEDocument" SG_ 2566802686 NightVisionIlluminatorSelect "J1939-71";
BA_ "SigType" SG_ 2566802686 BlackOutBrake_StopLampSelect 5;
BA_ "SPN" SG_ 2566802686 BlackOutBrake_StopLampSelect 1841;
BA_ "SAEDocument" SG_ 2566802686 BlackOutBrake_StopLampSelect "J1939-71";
BA_ "SigType" SG_ 2566802686 ConvoyDrivingLampSelect 5;
BA_ "SPN" SG_ 2566802686 ConvoyDrivingLampSelect 1837;
BA_ "SAEDocument" SG_ 2566802686 ConvoyDrivingLampSelect "J1939-71";
BA_ "SigType" SG_ 2566802686 ConvoyLampSelect 5;
BA_ "SPN" SG_ 2566802686 ConvoyLampSelect 1838;
BA_ "SAEDocument" SG_ 2566802686 ConvoyLampSelect "J1939-71";
BA_ "SigType" SG_ 2566802686 FrontBlackOutMarkerLampSelect 5;
BA_ "SPN" SG_ 2566802686 FrontBlackOutMarkerLampSelect 1839;
BA_ "SAEDocument" SG_ 2566802686 FrontBlackOutMarkerLampSelect "J1939-71";
BA_ "SigType" SG_ 2566802686 RearBlackOutMarkerSelect 5;
BA_ "SPN" SG_ 2566802686 RearBlackOutMarkerSelect 1840;
BA_ "SAEDocument" SG_ 2566802686 RearBlackOutMarkerSelect "J1939-71";
BA_ "SigType" SG_ 2566774014 SlowVesselModeStatus 5;
BA_ "SPN" SG_ 2566774014 SlowVesselModeStatus 2617;
BA_ "SAEDocument" SG_ 2566774014 SlowVesselModeStatus "J1939-71";
BA_ "SigType" SG_ 2566774014 TrollingModeStatus 5;
BA_ "SPN" SG_ 2566774014 TrollingModeStatus 2616;
BA_ "SAEDocument" SG_ 2566774014 TrollingModeStatus "J1939-71";
BA_ "SPN" SG_ 2566774014 EngThrttlSynchrnzationModeStatus 2615;
BA_ "SAEDocument" SG_ 2566774014 EngThrttlSynchrnzationModeStatus "J1939-71";
BA_ "SigType" SG_ 2566823166 EngMainBearing11Temp 1;
BA_ "SPN" SG_ 2566823166 EngMainBearing11Temp 1167;
BA_ "SAEDocument" SG_ 2566823166 EngMainBearing11Temp "J1939-71";
BA_ "SigType" SG_ 2566823166 EngMainBearing10Temp 1;
BA_ "SPN" SG_ 2566823166 EngMainBearing10Temp 1166;
BA_ "SAEDocument" SG_ 2566823166 EngMainBearing10Temp "J1939-71";
BA_ "SigType" SG_ 2566823166 EngMainBearing9Temp 1;
BA_ "SPN" SG_ 2566823166 EngMainBearing9Temp 1165;
BA_ "SAEDocument" SG_ 2566823166 EngMainBearing9Temp "J1939-71";
BA_ "SigType" SG_ 2566823422 EngMainBearing8Temp 1;
BA_ "SPN" SG_ 2566823422 EngMainBearing8Temp 1164;
BA_ "SAEDocument" SG_ 2566823422 EngMainBearing8Temp "J1939-71";
BA_ "SigType" SG_ 2566823422 EngMainBearing7Temp 1;
BA_ "SPN" SG_ 2566823422 EngMainBearing7Temp 1163;
BA_ "SAEDocument" SG_ 2566823422 EngMainBearing7Temp "J1939-71";
BA_ "SigType" SG_ 2566823422 EngMainBearing6Temp 1;
BA_ "SPN" SG_ 2566823422 EngMainBearing6Temp 1162;
BA_ "SAEDocument" SG_ 2566823422 EngMainBearing6Temp "J1939-71";
BA_ "SigType" SG_ 2566823422 EngMainBearing5Temp 1;
BA_ "SPN" SG_ 2566823422 EngMainBearing5Temp 1161;
BA_ "SAEDocument" SG_ 2566823422 EngMainBearing5Temp "J1939-71";
BA_ "SigType" SG_ 2566823678 EngMainBearing4Temp 1;
BA_ "SPN" SG_ 2566823678 EngMainBearing4Temp 1160;
BA_ "SAEDocument" SG_ 2566823678 EngMainBearing4Temp "J1939-71";
BA_ "SigType" SG_ 2566823678 EngMainBearing3Temp 1;
BA_ "SPN" SG_ 2566823678 EngMainBearing3Temp 1159;
BA_ "SAEDocument" SG_ 2566823678 EngMainBearing3Temp "J1939-71";
BA_ "SigType" SG_ 2566823678 EngMainBearing2Temp 1;
BA_ "SPN" SG_ 2566823678 EngMainBearing2Temp 1158;
BA_ "SAEDocument" SG_ 2566823678 EngMainBearing2Temp "J1939-71";
BA_ "SigType" SG_ 2566823678 EngMainBearing1Temp 1;
BA_ "SPN" SG_ 2566823678 EngMainBearing1Temp 1157;
BA_ "SAEDocument" SG_ 2566823678 EngMainBearing1Temp "J1939-71";
BA_ "SPN" SG_ 2432595710 DisplayDeadbands 2577;
BA_ "SAEDocument" SG_ 2432595710 DisplayDeadbands "J1939-71";
BA_ "SPN" SG_ 2432595710 LEDPatternCtrl 2578;
BA_ "SAEDocument" SG_ 2432595710 LEDPatternCtrl "J1939-71";
BA_ "SPN" SG_ 2432595710 LEDDisplayDeadbandCtrl 1806;
BA_ "SAEDocument" SG_ 2432595710 LEDDisplayDeadbandCtrl "J1939-71";
BA_ "SPN" SG_ 2432595710 LEDDisplayModeCtrl 1805;
BA_ "SAEDocument" SG_ 2432595710 LEDDisplayModeCtrl "J1939-71";
BA_ "SPN" SG_ 2432595710 LEDDisplayData1 1573;
BA_ "SAEDocument" SG_ 2432595710 LEDDisplayData1 "J1939-71";
BA_ "SigType" SG_ 2365486590 LaserStrikeDataLatency 1;
BA_ "SPN" SG_ 2365486590 LaserStrikeDataLatency 2793;
BA_ "SAEDocument" SG_ 2365486590 LaserStrikeDataLatency "J1939-71";
BA_ "SPN" SG_ 2365486590 LaserReceiverType 2576;
BA_ "SAEDocument" SG_ 2365486590 LaserReceiverType "J1939-71";
BA_ "SigType" SG_ 2365486590 LaserStrikeVerticalDeviation 1;
BA_ "SPN" SG_ 2365486590 LaserStrikeVerticalDeviation 1574;
BA_ "SAEDocument" SG_ 2365486590 LaserStrikeVerticalDeviation "J1939-71";
BA_ "SigType" SG_ 2365486590 AbsLaserStrikePos 1;
BA_ "SPN" SG_ 2365486590 AbsLaserStrikePos 2794;
BA_ "SAEDocument" SG_ 2365486590 AbsLaserStrikePos "J1939-71";
BA_ "SPN" SG_ 2365485566 LaserTracerInformation 1583;
BA_ "SAEDocument" SG_ 2365485566 LaserTracerInformation "J1939-71";
BA_ "SPN" SG_ 2365485566 LEDDisplayData2 1582;
BA_ "SAEDocument" SG_ 2365485566 LEDDisplayData2 "J1939-71";
BA_ "SigType" SG_ 2365485566 LaserTracerHorizontalDeviation 1;
BA_ "SPN" SG_ 2365485566 LaserTracerHorizontalDeviation 1581;
BA_ "SAEDocument" SG_ 2365485566 LaserTracerHorizontalDeviation "J1939-71";
BA_ "SigType" SG_ 2365485566 LaserTracerVerticalDistance 1;
BA_ "SPN" SG_ 2365485566 LaserTracerVerticalDistance 1580;
BA_ "SAEDocument" SG_ 2365485566 LaserTracerVerticalDistance "J1939-71";
BA_ "SigType" SG_ 2365485566 LaserTracerTargetDeviation 1;
BA_ "SPN" SG_ 2365485566 LaserTracerTargetDeviation 1579;
BA_ "SAEDocument" SG_ 2365485566 LaserTracerTargetDeviation "J1939-71";
BA_ "SigType" SG_ 2633939454 TripCruiseFuelUsed 1;
BA_ "SPN" SG_ 2633939454 TripCruiseFuelUsed 1005;
BA_ "SAEDocument" SG_ 2633939454 TripCruiseFuelUsed "J1939-71";
BA_ "SigType" SG_ 2633939454 TripVehicleIdleFuelUsed 1;
BA_ "SPN" SG_ 2633939454 TripVehicleIdleFuelUsed 1004;
BA_ "SAEDocument" SG_ 2633939454 TripVehicleIdleFuelUsed "J1939-71";
BA_ "SigType" SG_ 2633939454 TripDriveFuelUsed 1;
BA_ "SPN" SG_ 2633939454 TripDriveFuelUsed 1001;
BA_ "SAEDocument" SG_ 2633939454 TripDriveFuelUsed "J1939-71";
BA_ "SigType" SG_ 2633939454 TripPTOGovernorNonmovingFuelUsed 1;
BA_ "SPN" SG_ 2633939454 TripPTOGovernorNonmovingFuelUsed 1003;
BA_ "SAEDocument" SG_ 2633939454 TripPTOGovernorNonmovingFuelUsed "J1939-71";
BA_ "SigType" SG_ 2633939454 TripPTOGovernorMovingFuelUsed 1;
BA_ "SPN" SG_ 2633939454 TripPTOGovernorMovingFuelUsed 1002;
BA_ "SAEDocument" SG_ 2633939454 TripPTOGovernorMovingFuelUsed "J1939-71";
BA_ "SigType" SG_ 2633939454 TripDriveFuelEconomy 1;
BA_ "SPN" SG_ 2633939454 TripDriveFuelEconomy 1006;
BA_ "SAEDocument" SG_ 2633939454 TripDriveFuelEconomy "J1939-71";
BA_ "SigType" SG_ 2365486334 BldeHeightSetPointHighResolution 1;
BA_ "SPN" SG_ 2365486334 BldeHeightSetPointHighResolution 1759;
BA_ "SAEDocument" SG_ 2365486334 BldeHeightSetPointHighResolution "J1939-71";
BA_ "SigType" SG_ 2365486334 ModifyLevelingSystemSetPoint 1;
BA_ "SPN" SG_ 2365486334 ModifyLevelingSystemSetPoint 1575;
BA_ "SAEDocument" SG_ 2365486334 ModifyLevelingSystemSetPoint "J1939-71";
BA_ "SigType" SG_ 2364542462 StElvtnSensor2ReferenceElevation 5;
BA_ "SPN" SG_ 2364542462 StElvtnSensor2ReferenceElevation 5406;
BA_ "SAEDocument" SG_ 2364542462 StElvtnSensor2ReferenceElevation "J1939-71";
BA_ "SigType" SG_ 2364542462 StElvtnSensor1ReferenceElevation 5;
BA_ "SPN" SG_ 2364542462 StElvtnSensor1ReferenceElevation 5405;
BA_ "SAEDocument" SG_ 2364542462 StElvtnSensor1ReferenceElevation "J1939-71";
BA_ "SPN" SG_ 2364542462 SdshftDsrdBldeOffsetOperatorCtrl 3339;
BA_ "SAEDocument" SG_ 2364542462 SdshftDsrdBldeOffsetOperatorCtrl "J1939-71";
BA_ "SPN" SG_ 2364542462 SdshiftBladeCtrlModeOperatorCtrl 3338;
BA_ "SAEDocument" SG_ 2364542462 SdshiftBladeCtrlModeOperatorCtrl "J1939-71";
BA_ "SPN" SG_ 2364542462 RghtDsredBladeOffsetOperatorCtrl 3337;
BA_ "SAEDocument" SG_ 2364542462 RghtDsredBladeOffsetOperatorCtrl "J1939-71";
BA_ "SPN" SG_ 2364542462 LftDsiredBladeOffsetOperatorCtrl 3336;
BA_ "SAEDocument" SG_ 2364542462 LftDsiredBladeOffsetOperatorCtrl "J1939-71";
BA_ "SPN" SG_ 2364542462 RightBladeCtrlModeOperatorCtrl 3335;
BA_ "SAEDocument" SG_ 2364542462 RightBladeCtrlModeOperatorCtrl "J1939-71";
BA_ "SPN" SG_ 2364542462 LeftBladeCtrlModeOperatorCtrl 3334;
BA_ "SAEDocument" SG_ 2364542462 LeftBladeCtrlModeOperatorCtrl "J1939-71";
BA_ "SPN" SG_ 2364542462 BladeAutoModeCmd 3158;
BA_ "SAEDocument" SG_ 2364542462 BladeAutoModeCmd "J1939-71";
BA_ "SPN" SG_ 2364542462 DesiredGradeOffsetSwitch 3157;
BA_ "SAEDocument" SG_ 2364542462 DesiredGradeOffsetSwitch "J1939-71";
BA_ "SPN" SG_ 2364542462 BladeCtrlModeSwitch 3156;
BA_ "SAEDocument" SG_ 2364542462 BladeCtrlModeSwitch "J1939-71";
BA_ "SigType" SG_ 2365486078 MastPos 1;
BA_ "SPN" SG_ 2365486078 MastPos 1576;
BA_ "SAEDocument" SG_ 2365486078 MastPos "J1939-71";
BA_ "SPN" SG_ 2633937918 FlexibleFuelPercentage 5458;
BA_ "SAEDocument" SG_ 2633937918 FlexibleFuelPercentage "J1939-71";
BA_ "SigType" SG_ 2633937918 TripAverageFuelRate 1;
BA_ "SPN" SG_ 2633937918 TripAverageFuelRate 1029;
BA_ "SAEDocument" SG_ 2633937918 TripAverageFuelRate "J1939-71";
BA_ "SigType" SG_ 2633937918 TotalEngPTOGovernorFuelUsed 1;
BA_ "SPN" SG_ 2633937918 TotalEngPTOGovernorFuelUsed 1028;
BA_ "SAEDocument" SG_ 2633937918 TotalEngPTOGovernorFuelUsed "J1939-71";
BA_ "SigType" SG_ 2566845182 EngAverageFuelEconomy 1;
BA_ "SPN" SG_ 2566845182 EngAverageFuelEconomy 185;
BA_ "SAEDocument" SG_ 2566845182 EngAverageFuelEconomy "J1939-71";
BA_ "SigType" SG_ 2566845182 EngInstantaneousFuelEconomy 1;
BA_ "SPN" SG_ 2566845182 EngInstantaneousFuelEconomy 184;
BA_ "SAEDocument" SG_ 2566845182 EngInstantaneousFuelEconomy "J1939-71";
BA_ "SigType" SG_ 2566845182 EngFuelRate 1;
BA_ "SPN" SG_ 2566845182 EngFuelRate 183;
BA_ "SAEDocument" SG_ 2566845182 EngFuelRate "J1939-71";
BA_ "SigType" SG_ 2566845182 EngThrottleValve2Pos 1;
BA_ "SPN" SG_ 2566845182 EngThrottleValve2Pos 3673;
BA_ "SAEDocument" SG_ 2566845182 EngThrottleValve2Pos "J1939-71";
BA_ "SigType" SG_ 2566845182 EngThrottleValve1Pos 1;
BA_ "SPN" SG_ 2566845182 EngThrottleValve1Pos 51;
BA_ "SAEDocument" SG_ 2566845182 EngThrottleValve1Pos "J1939-71";
BA_ "SigType" SG_ 2566842878 EngTotalFuelUsed 1;
BA_ "SPN" SG_ 2566842878 EngTotalFuelUsed 250;
BA_ "SAEDocument" SG_ 2566842878 EngTotalFuelUsed "J1939-71";
BA_ "SigType" SG_ 2566842878 EngTripFuel 1;
BA_ "SPN" SG_ 2566842878 EngTripFuel 182;
BA_ "SAEDocument" SG_ 2566842878 EngTripFuel "J1939-71";
BA_ "SigType" SG_ 2633883646 FrontWheelDriveActuatorStatus 4;
BA_ "SPN" SG_ 2633883646 FrontWheelDriveActuatorStatus 2612;
BA_ "SAEDocument" SG_ 2633883646 FrontWheelDriveActuatorStatus "J1939-71";
BA_ "SigType" SG_ 2633880062 FMSstandardSWversionSupported 1;
BA_ "SPN" SG_ 2633880062 FMSstandardSWversionSupported 2806;
BA_ "SAEDocument" SG_ 2633880062 FMSstandardSWversionSupported "J1939-71";
BA_ "SigType" SG_ 2633880062 FMSstandardRequestsSupported 5;
BA_ "SPN" SG_ 2633880062 FMSstandardRequestsSupported 2805;
BA_ "SAEDocument" SG_ 2633880062 FMSstandardRequestsSupported "J1939-71";
BA_ "SigType" SG_ 2633880062 FMSstandardDiagnosticsSupported 5;
BA_ "SPN" SG_ 2633880062 FMSstandardDiagnosticsSupported 2804;
BA_ "SAEDocument" SG_ 2633880062 FMSstandardDiagnosticsSupported "J1939-71";
BA_ "SigType" SG_ 2566806526 LnDpartureIndicationEnableStatus 5;
BA_ "SPN" SG_ 2566806526 LnDpartureIndicationEnableStatus 1702;
BA_ "SAEDocument" SG_ 2566806526 LnDpartureIndicationEnableStatus "J1939-71";
BA_ "SigType" SG_ 2566806526 LaneTrackingStatusLeftSide 5;
BA_ "SPN" SG_ 2566806526 LaneTrackingStatusLeftSide 1710;
BA_ "SAEDocument" SG_ 2566806526 LaneTrackingStatusLeftSide "J1939-71";
BA_ "SigType" SG_ 2566806526 LaneTrackingStatusRightSide 5;
BA_ "SPN" SG_ 2566806526 LaneTrackingStatusRightSide 1711;
BA_ "SAEDocument" SG_ 2566806526 LaneTrackingStatusRightSide "J1939-71";
BA_ "SigType" SG_ 2431649790 LaneDepartureImminentLeftSide 5;
BA_ "SPN" SG_ 2431649790 LaneDepartureImminentLeftSide 1700;
BA_ "SAEDocument" SG_ 2431649790 LaneDepartureImminentLeftSide "J1939-71";
BA_ "SigType" SG_ 2431649790 LaneDepartureImminentRightSide 5;
BA_ "SPN" SG_ 2431649790 LaneDepartureImminentRightSide 1701;
BA_ "SAEDocument" SG_ 2431649790 LaneDepartureImminentRightSide "J1939-71";
BA_ "SigType" SG_ 2431649790 LaneDepartureRight 5;
BA_ "SPN" SG_ 2431649790 LaneDepartureRight 3566;
BA_ "SAEDocument" SG_ 2431649790 LaneDepartureRight "J1939-71";
BA_ "SigType" SG_ 2431649790 LaneDepartureLeft 5;
BA_ "SPN" SG_ 2431649790 LaneDepartureLeft 3565;
BA_ "SAEDocument" SG_ 2431649790 LaneDepartureLeft "J1939-71";
BA_ "SigType" SG_ 2633929214 EngFuelLeakage2 5;
BA_ "SPN" SG_ 2633929214 EngFuelLeakage2 1240;
BA_ "SAEDocument" SG_ 2633929214 EngFuelLeakage2 "J1939-71";
BA_ "SigType" SG_ 2633929214 EngFuelLeakage1 5;
BA_ "SPN" SG_ 2633929214 EngFuelLeakage1 1239;
BA_ "SAEDocument" SG_ 2633929214 EngFuelLeakage1 "J1939-71";
BA_ "SPN" SG_ 2566831614 FanDriveBypassCmdStatus 4212;
BA_ "SAEDocument" SG_ 2566831614 FanDriveBypassCmdStatus "J1939-71";
BA_ "SigType" SG_ 2566831614 HydFanMotorPress 1;
BA_ "SPN" SG_ 2566831614 HydFanMotorPress 4211;
BA_ "SAEDocument" SG_ 2566831614 HydFanMotorPress "J1939-71";
BA_ "SigType" SG_ 2566831614 FanSpeed 1;
BA_ "SPN" SG_ 2566831614 FanSpeed 1639;
BA_ "SAEDocument" SG_ 2566831614 FanSpeed "J1939-71";
BA_ "SPN" SG_ 2566831614 FanDriveState 977;
BA_ "SAEDocument" SG_ 2566831614 FanDriveState "J1939-71";
BA_ "SPN" SG_ 2566831614 EstPercentFanSpeed 975;
BA_ "SAEDocument" SG_ 2566831614 EstPercentFanSpeed "J1939-71";
BA_ "SigType" SG_ 2566820094 EngTorqueLimit6AxleInput 1;
BA_ "SPN" SG_ 2566820094 EngTorqueLimit6AxleInput 1263;
BA_ "SAEDocument" SG_ 2566820094 EngTorqueLimit6AxleInput "J1939-71";
BA_ "SigType" SG_ 2566820094 EngTorqueLimit5Switch 1;
BA_ "SPN" SG_ 2566820094 EngTorqueLimit5Switch 1262;
BA_ "SAEDocument" SG_ 2566820094 EngTorqueLimit5Switch "J1939-71";
BA_ "SigType" SG_ 2566820094 EngTorqueLimit4Trans 1;
BA_ "SPN" SG_ 2566820094 EngTorqueLimit4Trans 1261;
BA_ "SAEDocument" SG_ 2566820094 EngTorqueLimit4Trans "J1939-71";
BA_ "SigType" SG_ 2566820094 EngTorqueLimit3Trans 1;
BA_ "SPN" SG_ 2566820094 EngTorqueLimit3Trans 1260;
BA_ "SAEDocument" SG_ 2566820094 EngTorqueLimit3Trans "J1939-71";
BA_ "SigType" SG_ 2566820094 TransGearRatio3 1;
BA_ "SPN" SG_ 2566820094 TransGearRatio3 1259;
BA_ "SAEDocument" SG_ 2566820094 TransGearRatio3 "J1939-71";
BA_ "SigType" SG_ 2566820094 EngTorqueLimit2Trans 1;
BA_ "SPN" SG_ 2566820094 EngTorqueLimit2Trans 1258;
BA_ "SAEDocument" SG_ 2566820094 EngTorqueLimit2Trans "J1939-71";
BA_ "SigType" SG_ 2566820094 TransGearRatio2 1;
BA_ "SPN" SG_ 2566820094 TransGearRatio2 1257;
BA_ "SAEDocument" SG_ 2566820094 TransGearRatio2 "J1939-71";
BA_ "SigType" SG_ 2566820094 EngTorqueLimit1Trans 1;
BA_ "SPN" SG_ 2566820094 EngTorqueLimit1Trans 1256;
BA_ "SAEDocument" SG_ 2566820094 EngTorqueLimit1Trans "J1939-71";
BA_ "SigType" SG_ 2566820094 TransGearRatio1 1;
BA_ "SPN" SG_ 2566820094 TransGearRatio1 1255;
BA_ "SAEDocument" SG_ 2566820094 TransGearRatio1 "J1939-71";
BA_ "SPN" SG_ 2566820094 EngTorqueLimitFeature 1632;
BA_ "SAEDocument" SG_ 2566820094 EngTorqueLimitFeature "J1939-71";
BA_ "SigType" SG_ 2566820094 TorqueLimitingFeatureStatus 5;
BA_ "SPN" SG_ 2566820094 TorqueLimitingFeatureStatus 1254;
BA_ "SAEDocument" SG_ 2566820094 TorqueLimitingFeatureStatus "J1939-71";
BA_ "SigType" SG_ 2566820094 CalibRecordDurationTime 1;
BA_ "SPN" SG_ 2566820094 CalibRecordDurationTime 1253;
BA_ "SAEDocument" SG_ 2566820094 CalibRecordDurationTime "J1939-71";
BA_ "SigType" SG_ 2566820094 CalibRecordStartYear 1;
BA_ "SPN" SG_ 2566820094 CalibRecordStartYear 1252;
BA_ "SAEDocument" SG_ 2566820094 CalibRecordStartYear "J1939-71";
BA_ "SigType" SG_ 2566820094 CalibRecordStartDay 1;
BA_ "SPN" SG_ 2566820094 CalibRecordStartDay 1251;
BA_ "SAEDocument" SG_ 2566820094 CalibRecordStartDay "J1939-71";
BA_ "SigType" SG_ 2566820094 CalibRecordStartMonth 1;
BA_ "SPN" SG_ 2566820094 CalibRecordStartMonth 1250;
BA_ "SAEDocument" SG_ 2566820094 CalibRecordStartMonth "J1939-71";
BA_ "SigType" SG_ 2566820094 EngPeakTorque2 1;
BA_ "SPN" SG_ 2566820094 EngPeakTorque2 1249;
BA_ "SAEDocument" SG_ 2566820094 EngPeakTorque2 "J1939-71";
BA_ "SigType" SG_ 2566820094 EngPeakTorque1 1;
BA_ "SPN" SG_ 2566820094 EngPeakTorque1 1248;
BA_ "SAEDocument" SG_ 2566820094 EngPeakTorque1 "J1939-71";
BA_ "SigType" SG_ 2566820094 EngPower 1;
BA_ "SPN" SG_ 2566820094 EngPower 1247;
BA_ "SAEDocument" SG_ 2566820094 EngPower "J1939-71";
BA_ "SigType" SG_ 2566820094 NumberOfEngTorqueHistoryRecords 1;
BA_ "SPN" SG_ 2566820094 NumberOfEngTorqueHistoryRecords 1246;
BA_ "SAEDocument" SG_ 2566820094 NumberOfEngTorqueHistoryRecords "J1939-71";
BA_ "SigType" SG_ 2364542206 TransClutch_ConverterInputSpeed 1;
BA_ "SPN" SG_ 2364542206 TransClutch_ConverterInputSpeed 5052;
BA_ "SAEDocument" SG_ 2364542206 TransClutch_ConverterInputSpeed "J1939-71";
BA_ "SigType" SG_ 2364542206 TransTorqueConverterRatio 1;
BA_ "SPN" SG_ 2364542206 TransTorqueConverterRatio 3030;
BA_ "SAEDocument" SG_ 2364542206 TransTorqueConverterRatio "J1939-71";
BA_ "SigType" SG_ 2566802174 TrnsRverseGearShiftInhibitStatus 4;
BA_ "SPN" SG_ 2566802174 TrnsRverseGearShiftInhibitStatus 4261;
BA_ "SAEDocument" SG_ 2566802174 TrnsRverseGearShiftInhibitStatus "J1939-71";
BA_ "SigType" SG_ 2566802174 TrnsCrrentRangeDisplayBlankState 5;
BA_ "SPN" SG_ 2566802174 TrnsCrrentRangeDisplayBlankState 4176;
BA_ "SAEDocument" SG_ 2566802174 TrnsCrrentRangeDisplayBlankState "J1939-71";
BA_ "SigType" SG_ 2566802174 TransWarningIndicator 5;
BA_ "SPN" SG_ 2566802174 TransWarningIndicator 5344;
BA_ "SAEDocument" SG_ 2566802174 TransWarningIndicator "J1939-71";
BA_ "SigType" SG_ 2566802174 TransMode8Indicator 5;
BA_ "SPN" SG_ 2566802174 TransMode8Indicator 4253;
BA_ "SAEDocument" SG_ 2566802174 TransMode8Indicator "J1939-71";
BA_ "SigType" SG_ 2566802174 TransMode7Indicator 5;
BA_ "SPN" SG_ 2566802174 TransMode7Indicator 4252;
BA_ "SAEDocument" SG_ 2566802174 TransMode7Indicator "J1939-71";
BA_ "SigType" SG_ 2566802174 TransMode6Indicator 5;
BA_ "SPN" SG_ 2566802174 TransMode6Indicator 4251;
BA_ "SAEDocument" SG_ 2566802174 TransMode6Indicator "J1939-71";
BA_ "SigType" SG_ 2566802174 TransMode5Indicator 5;
BA_ "SPN" SG_ 2566802174 TransMode5Indicator 4250;
BA_ "SAEDocument" SG_ 2566802174 TransMode5Indicator "J1939-71";
BA_ "SPN" SG_ 2566802174 TransRequestedGearFeedback 3289;
BA_ "SAEDocument" SG_ 2566802174 TransRequestedGearFeedback "J1939-71";
BA_ "SigType" SG_ 2566802174 TransMode1Indicator 5;
BA_ "SPN" SG_ 2566802174 TransMode1Indicator 2536;
BA_ "SAEDocument" SG_ 2566802174 TransMode1Indicator "J1939-71";
BA_ "SigType" SG_ 2566802174 TransMode2Indicator 5;
BA_ "SPN" SG_ 2566802174 TransMode2Indicator 2537;
BA_ "SAEDocument" SG_ 2566802174 TransMode2Indicator "J1939-71";
BA_ "SigType" SG_ 2566802174 TransMode3Indicator 5;
BA_ "SPN" SG_ 2566802174 TransMode3Indicator 2538;
BA_ "SAEDocument" SG_ 2566802174 TransMode3Indicator "J1939-71";
BA_ "SigType" SG_ 2566802174 TransMode4Indicator 5;
BA_ "SPN" SG_ 2566802174 TransMode4Indicator 2539;
BA_ "SAEDocument" SG_ 2566802174 TransMode4Indicator "J1939-71";
BA_ "SigType" SG_ 2566802174 TransShiftInhibitIndicator 5;
BA_ "SPN" SG_ 2566802174 TransShiftInhibitIndicator 1851;
BA_ "SAEDocument" SG_ 2566802174 TransShiftInhibitIndicator "J1939-71";
BA_ "SigType" SG_ 2566802174 TransEngCrankEnable 5;
BA_ "SPN" SG_ 2566802174 TransEngCrankEnable 2900;
BA_ "SAEDocument" SG_ 2566802174 TransEngCrankEnable "J1939-71";
BA_ "SigType" SG_ 2566802174 ActiveShiftConsoleIndicator 5;
BA_ "SPN" SG_ 2566802174 ActiveShiftConsoleIndicator 2945;
BA_ "SAEDocument" SG_ 2566802174 ActiveShiftConsoleIndicator "J1939-71";
BA_ "SigType" SG_ 2566802174 TransReadyForBrakeRelease 5;
BA_ "SPN" SG_ 2566802174 TransReadyForBrakeRelease 3086;
BA_ "SAEDocument" SG_ 2566802174 TransReadyForBrakeRelease "J1939-71";
BA_ "SigType" SG_ 2566802174 TrnsRqstedRangeDisplayFlashState 5;
BA_ "SPN" SG_ 2566802174 TrnsRqstedRangeDisplayFlashState 1849;
BA_ "SAEDocument" SG_ 2566802174 TrnsRqstedRangeDisplayFlashState "J1939-71";
BA_ "SigType" SG_ 2566802174 TrnsRqstedRangeDisplayBlankState 5;
BA_ "SPN" SG_ 2566802174 TrnsRqstedRangeDisplayBlankState 1850;
BA_ "SAEDocument" SG_ 2566802174 TrnsRqstedRangeDisplayBlankState "J1939-71";
BA_ "SigType" SG_ 2566802174 TransServiceIndicator 5;
BA_ "SPN" SG_ 2566802174 TransServiceIndicator 4178;
BA_ "SAEDocument" SG_ 2566802174 TransServiceIndicator "J1939-71";
BA_ "SigType" SG_ 2633935870 ClutchLifeRemaining 1;
BA_ "SPN" SG_ 2633935870 ClutchLifeRemaining 2983;
BA_ "SAEDocument" SG_ 2633935870 ClutchLifeRemaining "J1939-71";
BA_ "SPN" SG_ 2633935870 LowestPossibleGear 1114;
BA_ "SAEDocument" SG_ 2633935870 LowestPossibleGear "J1939-71";
BA_ "SPN" SG_ 2633935870 HighestPossibleGear 1115;
BA_ "SAEDocument" SG_ 2633935870 HighestPossibleGear "J1939-71";
BA_ "SPN" SG_ 2633935870 RecommendedGear 1113;
BA_ "SAEDocument" SG_ 2633935870 RecommendedGear "J1939-71";
BA_ "SigType" SG_ 2633942014 TransForwardDirectionSwitch 5;
BA_ "SPN" SG_ 2633942014 TransForwardDirectionSwitch 903;
BA_ "SAEDocument" SG_ 2633942014 TransForwardDirectionSwitch "J1939-71";
BA_ "SigType" SG_ 2633942014 TransNeutralSwitch 5;
BA_ "SPN" SG_ 2633942014 TransNeutralSwitch 604;
BA_ "SAEDocument" SG_ 2633942014 TransNeutralSwitch "J1939-71";
BA_ "SigType" SG_ 2633942014 TransReverseDirectionSwitch 5;
BA_ "SPN" SG_ 2633942014 TransReverseDirectionSwitch 767;
BA_ "SAEDocument" SG_ 2633942014 TransReverseDirectionSwitch "J1939-71";
BA_ "SigType" SG_ 2633942014 TransLowRangeSenseSwitch 5;
BA_ "SPN" SG_ 2633942014 TransLowRangeSenseSwitch 779;
BA_ "SAEDocument" SG_ 2633942014 TransLowRangeSenseSwitch "J1939-71";
BA_ "SigType" SG_ 2633942014 TransHighRangeSenseSwitch 5;
BA_ "SPN" SG_ 2633942014 TransHighRangeSenseSwitch 778;
BA_ "SAEDocument" SG_ 2633942014 TransHighRangeSenseSwitch "J1939-71";
BA_ "SigType" SG_ 2633942526 TransSynchronizerBrakeValue 1;
BA_ "SPN" SG_ 2633942526 TransSynchronizerBrakeValue 54;
BA_ "SAEDocument" SG_ 2633942526 TransSynchronizerBrakeValue "J1939-71";
BA_ "SigType" SG_ 2633942526 TransSynchronizerClutchValue 1;
BA_ "SPN" SG_ 2633942526 TransSynchronizerClutchValue 53;
BA_ "SAEDocument" SG_ 2633942526 TransSynchronizerClutchValue "J1939-71";
BA_ "SigType" SG_ 2633943038 TransInertiaBrakeActuator 5;
BA_ "SPN" SG_ 2633943038 TransInertiaBrakeActuator 787;
BA_ "SAEDocument" SG_ 2633943038 TransInertiaBrakeActuator "J1939-71";
BA_ "SigType" SG_ 2633943038 TransDefuelActuator 5;
BA_ "SPN" SG_ 2633943038 TransDefuelActuator 786;
BA_ "SAEDocument" SG_ 2633943038 TransDefuelActuator "J1939-71";
BA_ "SigType" SG_ 2633943038 TransLockupClutchActuator 5;
BA_ "SPN" SG_ 2633943038 TransLockupClutchActuator 740;
BA_ "SAEDocument" SG_ 2633943038 TransLockupClutchActuator "J1939-71";
BA_ "SigType" SG_ 2633943038 TransClutchActuator 5;
BA_ "SPN" SG_ 2633943038 TransClutchActuator 788;
BA_ "SAEDocument" SG_ 2633943038 TransClutchActuator "J1939-71";
BA_ "SigType" SG_ 2633943038 TransSplitterIndirectActuator 5;
BA_ "SPN" SG_ 2633943038 TransSplitterIndirectActuator 771;
BA_ "SAEDocument" SG_ 2633943038 TransSplitterIndirectActuator "J1939-71";
BA_ "SigType" SG_ 2633943038 TransSplitterDirectActuator 5;
BA_ "SPN" SG_ 2633943038 TransSplitterDirectActuator 770;
BA_ "SAEDocument" SG_ 2633943038 TransSplitterDirectActuator "J1939-71";
BA_ "SigType" SG_ 2633943038 TransRangeLowActuator 5;
BA_ "SPN" SG_ 2633943038 TransRangeLowActuator 769;
BA_ "SAEDocument" SG_ 2633943038 TransRangeLowActuator "J1939-71";
BA_ "SigType" SG_ 2633943038 TransRangeHighActuator 5;
BA_ "SPN" SG_ 2633943038 TransRangeHighActuator 768;
BA_ "SAEDocument" SG_ 2633943038 TransRangeHighActuator "J1939-71";
BA_ "SigType" SG_ 2633943038 TransShiftFingerGearActuator2 5;
BA_ "SPN" SG_ 2633943038 TransShiftFingerGearActuator2 784;
BA_ "SAEDocument" SG_ 2633943038 TransShiftFingerGearActuator2 "J1939-71";
BA_ "SigType" SG_ 2633943038 TransShiftFingerRailActuator2 5;
BA_ "SPN" SG_ 2633943038 TransShiftFingerRailActuator2 783;
BA_ "SAEDocument" SG_ 2633943038 TransShiftFingerRailActuator2 "J1939-71";
BA_ "SigType" SG_ 2633943038 TransShiftFingerGearActuator1 5;
BA_ "SPN" SG_ 2633943038 TransShiftFingerGearActuator1 773;
BA_ "SAEDocument" SG_ 2633943038 TransShiftFingerGearActuator1 "J1939-71";
BA_ "SigType" SG_ 2633943038 TransShiftFingerRailActuator1 5;
BA_ "SPN" SG_ 2633943038 TransShiftFingerRailActuator1 772;
BA_ "SAEDocument" SG_ 2633943038 TransShiftFingerRailActuator1 "J1939-71";
BA_ "SigType" SG_ 2633943038 TrnsShftFngerCenterRailIndicator 5;
BA_ "SPN" SG_ 2633943038 TrnsShftFngerCenterRailIndicator 782;
BA_ "SAEDocument" SG_ 2633943038 TrnsShftFngerCenterRailIndicator "J1939-71";
BA_ "SigType" SG_ 2633943038 TrnsShftFngerEngagementIndicator 5;
BA_ "SPN" SG_ 2633943038 TrnsShftFngerEngagementIndicator 781;
BA_ "SAEDocument" SG_ 2633943038 TrnsShftFngerEngagementIndicator "J1939-71";
BA_ "SigType" SG_ 2633943038 TransShiftFingerNeutralIndicator 5;
BA_ "SPN" SG_ 2633943038 TransShiftFingerNeutralIndicator 780;
BA_ "SAEDocument" SG_ 2633943038 TransShiftFingerNeutralIndicator "J1939-71";
BA_ "SigType" SG_ 2633943038 TransShiftFingerRailPos 1;
BA_ "SPN" SG_ 2633943038 TransShiftFingerRailPos 60;
BA_ "SAEDocument" SG_ 2633943038 TransShiftFingerRailPos "J1939-71";
BA_ "SigType" SG_ 2633943038 TransShiftFingerGearPos 1;
BA_ "SPN" SG_ 2633943038 TransShiftFingerGearPos 59;
BA_ "SAEDocument" SG_ 2633943038 TransShiftFingerGearPos "J1939-71";
BA_ "SPN" SG_ 2565867006 TransCurrentRange 163;
BA_ "SAEDocument" SG_ 2565867006 TransCurrentRange "J1939-71";
BA_ "SPN" SG_ 2565867006 TransRequestedRange 162;
BA_ "SAEDocument" SG_ 2565867006 TransRequestedRange "J1939-71";
BA_ "SigType" SG_ 2565867006 TransCurrentGear 1;
BA_ "SPN" SG_ 2565867006 TransCurrentGear 523;
BA_ "SAEDocument" SG_ 2565867006 TransCurrentGear "J1939-71";
BA_ "SigType" SG_ 2565867006 TransActualGearRatio 1;
BA_ "SPN" SG_ 2565867006 TransActualGearRatio 526;
BA_ "SAEDocument" SG_ 2565867006 TransActualGearRatio "J1939-71";
BA_ "SPN" SG_ 2565867006 TransSelectedGear 524;
BA_ "SAEDocument" SG_ 2565867006 TransSelectedGear "J1939-71";
BA_ "SPN" SG_ 2364539646 SrcAddrssOfCntrllngDvcFrTrnsCtrl 1482;
BA_ "SAEDocument" SG_ 2364539646 SrcAddrssOfCntrllngDvcFrTrnsCtrl "J1939-71";
BA_ "SigType" SG_ 2364539646 TransInputShaftSpeed 1;
BA_ "SPN" SG_ 2364539646 TransInputShaftSpeed 161;
BA_ "SAEDocument" SG_ 2364539646 TransInputShaftSpeed "J1939-71";
BA_ "SigType" SG_ 2364539646 MomentaryEngMaxPowerEnable 5;
BA_ "SPN" SG_ 2364539646 MomentaryEngMaxPowerEnable 5015;
BA_ "SAEDocument" SG_ 2364539646 MomentaryEngMaxPowerEnable "J1939-71";
BA_ "SigType" SG_ 2364539646 ProgressiveShiftDisable 5;
BA_ "SPN" SG_ 2364539646 ProgressiveShiftDisable 607;
BA_ "SAEDocument" SG_ 2364539646 ProgressiveShiftDisable "J1939-71";
BA_ "SigType" SG_ 2364539646 EngMomentaryOverspeedEnable 5;
BA_ "SPN" SG_ 2364539646 EngMomentaryOverspeedEnable 606;
BA_ "SAEDocument" SG_ 2364539646 EngMomentaryOverspeedEnable "J1939-71";
BA_ "SigType" SG_ 2364539646 PercentClutchSlip 1;
BA_ "SPN" SG_ 2364539646 PercentClutchSlip 522;
BA_ "SAEDocument" SG_ 2364539646 PercentClutchSlip "J1939-71";
BA_ "SigType" SG_ 2364539646 TransOutputShaftSpeed 1;
BA_ "SPN" SG_ 2364539646 TransOutputShaftSpeed 191;
BA_ "SAEDocument" SG_ 2364539646 TransOutputShaftSpeed "J1939-71";
BA_ "SigType" SG_ 2364539646 TrnsTrqCnvrtrLckpTrnstnInProcess 4;
BA_ "SPN" SG_ 2364539646 TrnsTrqCnvrtrLckpTrnstnInProcess 4816;
BA_ "SAEDocument" SG_ 2364539646 TrnsTrqCnvrtrLckpTrnstnInProcess "J1939-71";
BA_ "SigType" SG_ 2364539646 TransShiftInProcess 4;
BA_ "SPN" SG_ 2364539646 TransShiftInProcess 574;
BA_ "SAEDocument" SG_ 2364539646 TransShiftInProcess "J1939-71";
BA_ "SigType" SG_ 2364539646 TrnsTorqueConverterLockupEngaged 5;
BA_ "SPN" SG_ 2364539646 TrnsTorqueConverterLockupEngaged 573;
BA_ "SAEDocument" SG_ 2364539646 TrnsTorqueConverterLockupEngaged "J1939-71";
BA_ "SigType" SG_ 2364539646 TransDrivelineEngaged 4;
BA_ "SPN" SG_ 2364539646 TransDrivelineEngaged 560;
BA_ "SAEDocument" SG_ 2364539646 TransDrivelineEngaged "J1939-71";
BA_ "SigType" SG_ 2566810110 EngChargeAirCooler1OutletTemp 1;
BA_ "SPN" SG_ 2566810110 EngChargeAirCooler1OutletTemp 2630;
BA_ "SAEDocument" SG_ 2566810110 EngChargeAirCooler1OutletTemp "J1939-71";
BA_ "SigType" SG_ 2566810110 EngIntkVlvActuationSystemOilTemp 1;
BA_ "SPN" SG_ 2566810110 EngIntkVlvActuationSystemOilTemp 2986;
BA_ "SAEDocument" SG_ 2566810110 EngIntkVlvActuationSystemOilTemp "J1939-71";
BA_ "SigType" SG_ 2566810110 EngIntakeManifold1AirTemp 1;
BA_ "SPN" SG_ 2566810110 EngIntakeManifold1AirTemp 1636;
BA_ "SAEDocument" SG_ 2566810110 EngIntakeManifold1AirTemp "J1939-71";
BA_ "SigType" SG_ 2566810110 EngCoolantTemp 1;
BA_ "SPN" SG_ 2566810110 EngCoolantTemp 1637;
BA_ "SAEDocument" SG_ 2566810110 EngCoolantTemp "J1939-71";
BA_ "SigType" SG_ 2566825214 EngExhstGsRcirculation1DiffPress 1;
BA_ "SPN" SG_ 2566825214 EngExhstGsRcirculation1DiffPress 411;
BA_ "SAEDocument" SG_ 2566825214 EngExhstGsRcirculation1DiffPress "J1939-71";
BA_ "SigType" SG_ 2566825214 EngExhaustGasRecirculation1Temp 1;
BA_ "SPN" SG_ 2566825214 EngExhaustGasRecirculation1Temp 412;
BA_ "SAEDocument" SG_ 2566825214 EngExhaustGasRecirculation1Temp "J1939-71";
BA_ "SigType" SG_ 2566825214 EngECUTemp 1;
BA_ "SPN" SG_ 2566825214 EngECUTemp 1136;
BA_ "SAEDocument" SG_ 2566825214 EngECUTemp "J1939-71";
BA_ "SigType" SG_ 2566825214 EngOilTemp2 1;
BA_ "SPN" SG_ 2566825214 EngOilTemp2 1135;
BA_ "SAEDocument" SG_ 2566825214 EngOilTemp2 "J1939-71";
BA_ "SigType" SG_ 2566844158 EngFuelTemp1 1;
BA_ "SPN" SG_ 2566844158 EngFuelTemp1 174;
BA_ "SAEDocument" SG_ 2566844158 EngFuelTemp1 "J1939-71";
BA_ "SigType" SG_ 2566844158 EngIntercoolerThermostatOpening 1;
BA_ "SPN" SG_ 2566844158 EngIntercoolerThermostatOpening 1134;
BA_ "SAEDocument" SG_ 2566844158 EngIntercoolerThermostatOpening "J1939-71";
BA_ "SigType" SG_ 2566844158 EngIntercoolerTemp 1;
BA_ "SPN" SG_ 2566844158 EngIntercoolerTemp 52;
BA_ "SAEDocument" SG_ 2566844158 EngIntercoolerTemp "J1939-71";
BA_ "SigType" SG_ 2566844158 EngTurboOilTemp 1;
BA_ "SPN" SG_ 2566844158 EngTurboOilTemp 176;
BA_ "SAEDocument" SG_ 2566844158 EngTurboOilTemp "J1939-71";
BA_ "SigType" SG_ 2566844158 EngOilTemp1 1;
BA_ "SPN" SG_ 2566844158 EngOilTemp1 175;
BA_ "SAEDocument" SG_ 2566844158 EngOilTemp1 "J1939-71";
BA_ "SigType" SG_ 2566844158 EngCoolantTemp 1;
BA_ "SPN" SG_ 2566844158 EngCoolantTemp 110;
BA_ "SAEDocument" SG_ 2566844158 EngCoolantTemp "J1939-71";
BA_ "SigType" SG_ 2566785022 EngExhaustGasTempLeftManifold 1;
BA_ "SPN" SG_ 2566785022 EngExhaustGasTempLeftManifold 2434;
BA_ "SAEDocument" SG_ 2566785022 EngExhaustGasTempLeftManifold "J1939-71";
BA_ "SigType" SG_ 2566785022 EngExhaustGasTempRightManifold 1;
BA_ "SPN" SG_ 2566785022 EngExhaustGasTempRightManifold 2433;
BA_ "SAEDocument" SG_ 2566785022 EngExhaustGasTempRightManifold "J1939-71";
BA_ "SPN" SG_ 2565868542 TypeOfSteerTrans 2926;
BA_ "SAEDocument" SG_ 2565868542 TypeOfSteerTrans "J1939-71";
BA_ "SPN" SG_ 2565868542 TypeOfSteerForces 2925;
BA_ "SAEDocument" SG_ 2565868542 TypeOfSteerForces "J1939-71";
BA_ "SPN" SG_ 2565868542 SteerType 2924;
BA_ "SAEDocument" SG_ 2565868542 SteerType "J1939-71";
BA_ "SigType" SG_ 2565868542 SteerableLiftAxleLoweringInhibit 5;
BA_ "SPN" SG_ 2565868542 SteerableLiftAxleLoweringInhibit 2922;
BA_ "SAEDocument" SG_ 2565868542 SteerableLiftAxleLoweringInhibit "J1939-71";
BA_ "SPN" SG_ 2565868542 StatusOfSteerAxle 2923;
BA_ "SAEDocument" SG_ 2565868542 StatusOfSteerAxle "J1939-71";
BA_ "SigType" SG_ 2565868542 AxleLocation 1;
BA_ "SPN" SG_ 2565868542 AxleLocation 2928;
BA_ "SAEDocument" SG_ 2565868542 AxleLocation "J1939-71";
BA_ "SigType" SG_ 2565868542 ActualInnerWheelSteerAngle 1;
BA_ "SPN" SG_ 2565868542 ActualInnerWheelSteerAngle 2927;
BA_ "SAEDocument" SG_ 2565868542 ActualInnerWheelSteerAngle "J1939-71";
BA_ "SigType" SG_ 2633941758 TransOutputRetarder 5;
BA_ "SPN" SG_ 2633941758 TransOutputRetarder 748;
BA_ "SAEDocument" SG_ 2633941758 TransOutputRetarder "J1939-71";
BA_ "SigType" SG_ 2565865726 ActlMxAvlblRetarderPercentTorque 1;
BA_ "SPN" SG_ 2565865726 ActlMxAvlblRetarderPercentTorque 1717;
BA_ "SAEDocument" SG_ 2565865726 ActlMxAvlblRetarderPercentTorque "J1939-71";
BA_ "SigType" SG_ 2565865726 RetarderSelectionNonengine 1;
BA_ "SPN" SG_ 2565865726 RetarderSelectionNonengine 1716;
BA_ "SAEDocument" SG_ 2565865726 RetarderSelectionNonengine "J1939-71";
BA_ "SPN" SG_ 2565865726 DrvrsDemandRetarderPercentTorque 1715;
BA_ "SAEDocument" SG_ 2565865726 DrvrsDemandRetarderPercentTorque "J1939-71";
BA_ "SPN" SG_ 2565865726 SrcAddrssOfCntrllngDvcFrRtrdrCtr 1480;
BA_ "SAEDocument" SG_ 2565865726 SrcAddrssOfCntrllngDvcFrRtrdrCtr "J1939-71";
BA_ "SigType" SG_ 2565865726 RetarderRoadSpeedExceededStatus 5;
BA_ "SPN" SG_ 2565865726 RetarderRoadSpeedExceededStatus 4234;
BA_ "SAEDocument" SG_ 2565865726 RetarderRoadSpeedExceededStatus "J1939-71";
BA_ "SigType" SG_ 2565865726 RetarderRoadSpeedLimitSwitch 4;
BA_ "SPN" SG_ 2565865726 RetarderRoadSpeedLimitSwitch 4233;
BA_ "SAEDocument" SG_ 2565865726 RetarderRoadSpeedLimitSwitch "J1939-71";
BA_ "SigType" SG_ 2565865726 RetarderRequestingBrakeLight 5;
BA_ "SPN" SG_ 2565865726 RetarderRequestingBrakeLight 1667;
BA_ "SAEDocument" SG_ 2565865726 RetarderRequestingBrakeLight "J1939-71";
BA_ "SigType" SG_ 2565865726 EngCoolantLoadIncrease 5;
BA_ "SPN" SG_ 2565865726 EngCoolantLoadIncrease 1082;
BA_ "SAEDocument" SG_ 2565865726 EngCoolantLoadIncrease "J1939-71";
BA_ "SPN" SG_ 2565865726 IntendedRetarderPercentTorque 1085;
BA_ "SAEDocument" SG_ 2565865726 IntendedRetarderPercentTorque "J1939-71";
BA_ "SigType" SG_ 2565865726 ActualRetarderPercentTorque 1;
BA_ "SPN" SG_ 2565865726 ActualRetarderPercentTorque 520;
BA_ "SAEDocument" SG_ 2565865726 ActualRetarderPercentTorque "J1939-71";
BA_ "SigType" SG_ 2565865726 RetarderEnableShiftAssistSwitch 4;
BA_ "SPN" SG_ 2565865726 RetarderEnableShiftAssistSwitch 572;
BA_ "SAEDocument" SG_ 2565865726 RetarderEnableShiftAssistSwitch "J1939-71";
BA_ "SigType" SG_ 2565865726 RetarderEnableBrakeAssistSwitch 4;
BA_ "SPN" SG_ 2565865726 RetarderEnableBrakeAssistSwitch 571;
BA_ "SAEDocument" SG_ 2565865726 RetarderEnableBrakeAssistSwitch "J1939-71";
BA_ "SPN" SG_ 2565865726 RetarderTorqueMode 900;
BA_ "SAEDocument" SG_ 2565865726 RetarderTorqueMode "J1939-71";
BA_ "SigType" SG_ 2633932798 EngExhaustGasPort20Temp 1;
BA_ "SPN" SG_ 2633932798 EngExhaustGasPort20Temp 1156;
BA_ "SAEDocument" SG_ 2633932798 EngExhaustGasPort20Temp "J1939-71";
BA_ "SigType" SG_ 2633932798 EngExhaustGasPort19Temp 1;
BA_ "SPN" SG_ 2633932798 EngExhaustGasPort19Temp 1155;
BA_ "SAEDocument" SG_ 2633932798 EngExhaustGasPort19Temp "J1939-71";
BA_ "SigType" SG_ 2633932798 EngExhaustGasPort18Temp 1;
BA_ "SPN" SG_ 2633932798 EngExhaustGasPort18Temp 1154;
BA_ "SAEDocument" SG_ 2633932798 EngExhaustGasPort18Temp "J1939-71";
BA_ "SigType" SG_ 2633932798 EngExhaustGasPort17Temp 1;
BA_ "SPN" SG_ 2633932798 EngExhaustGasPort17Temp 1153;
BA_ "SAEDocument" SG_ 2633932798 EngExhaustGasPort17Temp "J1939-71";
BA_ "SigType" SG_ 2566824190 EngExhaustGasPort16Temp 1;
BA_ "SPN" SG_ 2566824190 EngExhaustGasPort16Temp 1152;
BA_ "SAEDocument" SG_ 2566824190 EngExhaustGasPort16Temp "J1939-71";
BA_ "SigType" SG_ 2566824190 EngExhaustGasPort15Temp 1;
BA_ "SPN" SG_ 2566824190 EngExhaustGasPort15Temp 1151;
BA_ "SAEDocument" SG_ 2566824190 EngExhaustGasPort15Temp "J1939-71";
BA_ "SigType" SG_ 2566824190 EngExhaustGasPort14Temp 1;
BA_ "SPN" SG_ 2566824190 EngExhaustGasPort14Temp 1150;
BA_ "SAEDocument" SG_ 2566824190 EngExhaustGasPort14Temp "J1939-71";
BA_ "SigType" SG_ 2566824190 EngExhaustGasPort13Temp 1;
BA_ "SPN" SG_ 2566824190 EngExhaustGasPort13Temp 1149;
BA_ "SAEDocument" SG_ 2566824190 EngExhaustGasPort13Temp "J1939-71";
BA_ "SigType" SG_ 2633933310 EngExhaustGasPort12Temp 1;
BA_ "SPN" SG_ 2633933310 EngExhaustGasPort12Temp 1148;
BA_ "SAEDocument" SG_ 2633933310 EngExhaustGasPort12Temp "J1939-71";
BA_ "SigType" SG_ 2633933310 EngExhaustGasPort11Temp 1;
BA_ "SPN" SG_ 2633933310 EngExhaustGasPort11Temp 1147;
BA_ "SAEDocument" SG_ 2633933310 EngExhaustGasPort11Temp "J1939-71";
BA_ "SigType" SG_ 2633933310 EngExhaustGasPort10Temp 1;
BA_ "SPN" SG_ 2633933310 EngExhaustGasPort10Temp 1146;
BA_ "SAEDocument" SG_ 2633933310 EngExhaustGasPort10Temp "J1939-71";
BA_ "SigType" SG_ 2633933310 EngExhaustGasPort9Temp 1;
BA_ "SPN" SG_ 2633933310 EngExhaustGasPort9Temp 1145;
BA_ "SAEDocument" SG_ 2633933310 EngExhaustGasPort9Temp "J1939-71";
BA_ "SigType" SG_ 2633933566 EngExhaustGasPort8Temp 1;
BA_ "SPN" SG_ 2633933566 EngExhaustGasPort8Temp 1144;
BA_ "SAEDocument" SG_ 2633933566 EngExhaustGasPort8Temp "J1939-71";
BA_ "SigType" SG_ 2633933566 EngExhaustGasPort7Temp 1;
BA_ "SPN" SG_ 2633933566 EngExhaustGasPort7Temp 1143;
BA_ "SAEDocument" SG_ 2633933566 EngExhaustGasPort7Temp "J1939-71";
BA_ "SigType" SG_ 2633933566 EngExhaustGasPort6Temp 1;
BA_ "SPN" SG_ 2633933566 EngExhaustGasPort6Temp 1142;
BA_ "SAEDocument" SG_ 2633933566 EngExhaustGasPort6Temp "J1939-71";
BA_ "SigType" SG_ 2633933566 EngExhaustGasPort5Temp 1;
BA_ "SPN" SG_ 2633933566 EngExhaustGasPort5Temp 1141;
BA_ "SAEDocument" SG_ 2633933566 EngExhaustGasPort5Temp "J1939-71";
BA_ "SigType" SG_ 2633933822 EngExhaustGasPort4Temp 1;
BA_ "SPN" SG_ 2633933822 EngExhaustGasPort4Temp 1140;
BA_ "SAEDocument" SG_ 2633933822 EngExhaustGasPort4Temp "J1939-71";
BA_ "SigType" SG_ 2633933822 EngExhaustGasPort3Temp 1;
BA_ "SPN" SG_ 2633933822 EngExhaustGasPort3Temp 1139;
BA_ "SAEDocument" SG_ 2633933822 EngExhaustGasPort3Temp "J1939-71";
BA_ "SigType" SG_ 2633933822 EngExhaustGasPort2Temp 1;
BA_ "SPN" SG_ 2633933822 EngExhaustGasPort2Temp 1138;
BA_ "SAEDocument" SG_ 2633933822 EngExhaustGasPort2Temp "J1939-71";
BA_ "SigType" SG_ 2633933822 EngExhaustGasPort1Temp 1;
BA_ "SPN" SG_ 2633933822 EngExhaustGasPort1Temp 1137;
BA_ "SAEDocument" SG_ 2633933822 EngExhaustGasPort1Temp "J1939-71";
BA_ "SigType" SG_ 2566776062 PayloadPercentage 1;
BA_ "SPN" SG_ 2566776062 PayloadPercentage 2600;
BA_ "SAEDocument" SG_ 2566776062 PayloadPercentage "J1939-71";
BA_ "SigType" SG_ 2566771454 DataMemoryUsage 1;
BA_ "SPN" SG_ 2566771454 DataMemoryUsage 2802;
BA_ "SAEDocument" SG_ 2566771454 DataMemoryUsage "J1939-71";
BA_ "SigType" SG_ 2566771454 KeepAliveBatteryConsumption 1;
BA_ "SPN" SG_ 2566771454 KeepAliveBatteryConsumption 2803;
BA_ "SAEDocument" SG_ 2566771454 KeepAliveBatteryConsumption "J1939-71";
BA_ "SigType" SG_ 2566775806 TravelVelocityCtrlPos 1;
BA_ "SPN" SG_ 2566775806 TravelVelocityCtrlPos 2601;
BA_ "SAEDocument" SG_ 2566775806 TravelVelocityCtrlPos "J1939-71";
BA_ "SigType" SG_ 2633935358 EngExhstGsOxygnSnsrClsdLpOprtion 5;
BA_ "SPN" SG_ 2633935358 EngExhstGsOxygnSnsrClsdLpOprtion 1696;
BA_ "SAEDocument" SG_ 2633935358 EngExhstGsOxygnSnsrClsdLpOprtion "J1939-71";
BA_ "SPN" SG_ 2633935358 EngExhstGsOxygnSnsrFlngCrrection 1695;
BA_ "SAEDocument" SG_ 2633935358 EngExhstGsOxygnSnsrFlngCrrection "J1939-71";
BA_ "SigType" SG_ 2633935358 EngActualExhaustOxygen 1;
BA_ "SPN" SG_ 2633935358 EngActualExhaustOxygen 1119;
BA_ "SAEDocument" SG_ 2633935358 EngActualExhaustOxygen "J1939-71";
BA_ "SigType" SG_ 2633935358 EngDesiredExhaustOxygen 1;
BA_ "SPN" SG_ 2633935358 EngDesiredExhaustOxygen 1118;
BA_ "SAEDocument" SG_ 2633935358 EngDesiredExhaustOxygen "J1939-71";
BA_ "SigType" SG_ 2633935358 EngDesiredRatedExhaustOxygen 1;
BA_ "SPN" SG_ 2633935358 EngDesiredRatedExhaustOxygen 1117;
BA_ "SAEDocument" SG_ 2633935358 EngDesiredRatedExhaustOxygen "J1939-71";
BA_ "SigType" SG_ 2365447166 Jystick3GripXAxisDetentPosStatus 4;
BA_ "SPN" SG_ 2365447166 Jystick3GripXAxisDetentPosStatus 2756;
BA_ "SAEDocument" SG_ 2365447166 Jystick3GripXAxisDetentPosStatus "J1939-71";
BA_ "SigType" SG_ 2365447166 Jystick3GripYAxisDetentPosStatus 4;
BA_ "SPN" SG_ 2365447166 Jystick3GripYAxisDetentPosStatus 2757;
BA_ "SAEDocument" SG_ 2365447166 Jystick3GripYAxisDetentPosStatus "J1939-71";
BA_ "SigType" SG_ 2365447166 Jystick3ThetaAxisDetentPosStatus 4;
BA_ "SPN" SG_ 2365447166 Jystick3ThetaAxisDetentPosStatus 2758;
BA_ "SAEDocument" SG_ 2365447166 Jystick3ThetaAxisDetentPosStatus "J1939-71";
BA_ "SPN" SG_ 2365447166 Joystick3ThetaAxisPos 2738;
BA_ "SAEDocument" SG_ 2365447166 Joystick3ThetaAxisPos "J1939-71";
BA_ "SigType" SG_ 2365447166 Jystck3ThtAxsClckwsPstvPosStatus 4;
BA_ "SPN" SG_ 2365447166 Jystck3ThtAxsClckwsPstvPosStatus 2743;
BA_ "SAEDocument" SG_ 2365447166 Jystck3ThtAxsClckwsPstvPosStatus "J1939-71";
BA_ "SigType" SG_ 2365447166 Jystck3ThetaAxisNeutralPosStatus 4;
BA_ "SPN" SG_ 2365447166 Jystck3ThetaAxisNeutralPosStatus 2753;
BA_ "SAEDocument" SG_ 2365447166 Jystck3ThetaAxisNeutralPosStatus "J1939-71";
BA_ "SPN" SG_ 2365447166 Joystick3GripYAxisPos 2737;
BA_ "SAEDocument" SG_ 2365447166 Joystick3GripYAxisPos "J1939-71";
BA_ "SigType" SG_ 2365447166 Jystck3GrpYAxsLvrFrwrdPstvPsStts 4;
BA_ "SPN" SG_ 2365447166 Jystck3GrpYAxsLvrFrwrdPstvPsStts 2742;
BA_ "SAEDocument" SG_ 2365447166 Jystck3GrpYAxsLvrFrwrdPstvPsStts "J1939-71";
BA_ "SigType" SG_ 2365447166 Jystck3GrpYAxsLvrBckNgtvPsStatus 4;
BA_ "SPN" SG_ 2365447166 Jystck3GrpYAxsLvrBckNgtvPsStatus 2747;
BA_ "SAEDocument" SG_ 2365447166 Jystck3GrpYAxsLvrBckNgtvPsStatus "J1939-71";
BA_ "SigType" SG_ 2365447166 Jystck3GripYAxisNeutralPosStatus 4;
BA_ "SPN" SG_ 2365447166 Jystck3GripYAxisNeutralPosStatus 2752;
BA_ "SAEDocument" SG_ 2365447166 Jystck3GripYAxisNeutralPosStatus "J1939-71";
BA_ "SPN" SG_ 2365447166 Joystick3GripXAxisPos 2736;
BA_ "SAEDocument" SG_ 2365447166 Joystick3GripXAxisPos "J1939-71";
BA_ "SigType" SG_ 2365447166 Jystck3GrpXAxsLvrRghtPstvPsSttus 4;
BA_ "SPN" SG_ 2365447166 Jystck3GrpXAxsLvrRghtPstvPsSttus 2741;
BA_ "SAEDocument" SG_ 2365447166 Jystck3GrpXAxsLvrRghtPstvPsSttus "J1939-71";
BA_ "SigType" SG_ 2365447166 Jystck3GrpXAxsLvrLftNgtvPsStatus 4;
BA_ "SPN" SG_ 2365447166 Jystck3GrpXAxsLvrLftNgtvPsStatus 2746;
BA_ "SAEDocument" SG_ 2365447166 Jystck3GrpXAxsLvrLftNgtvPsStatus "J1939-71";
BA_ "SigType" SG_ 2365447166 Jystck3GripXAxisNeutralPosStatus 4;
BA_ "SPN" SG_ 2365447166 Jystck3GripXAxisNeutralPosStatus 2751;
BA_ "SAEDocument" SG_ 2365447166 Jystck3GripXAxisNeutralPosStatus "J1939-71";
BA_ "SigType" SG_ 2365447166 Jystck3ThtAxsCntrClckwsNgtvPsStt 4;
BA_ "SPN" SG_ 2365447166 Jystck3ThtAxsCntrClckwsNgtvPsStt 2748;
BA_ "SAEDocument" SG_ 2365447166 Jystck3ThtAxsCntrClckwsNgtvPsStt "J1939-71";
BA_ "SigType" SG_ 2365446654 Jystick2GripXAxisDetentPosStatus 4;
BA_ "SPN" SG_ 2365446654 Jystick2GripXAxisDetentPosStatus 2719;
BA_ "SAEDocument" SG_ 2365446654 Jystick2GripXAxisDetentPosStatus "J1939-71";
BA_ "SigType" SG_ 2365446654 Jystick2GripYAxisDetentPosStatus 4;
BA_ "SPN" SG_ 2365446654 Jystick2GripYAxisDetentPosStatus 2720;
BA_ "SAEDocument" SG_ 2365446654 Jystick2GripYAxisDetentPosStatus "J1939-71";
BA_ "SigType" SG_ 2365446654 Jystick2ThetaAxisDetentPosStatus 4;
BA_ "SPN" SG_ 2365446654 Jystick2ThetaAxisDetentPosStatus 2721;
BA_ "SAEDocument" SG_ 2365446654 Jystick2ThetaAxisDetentPosStatus "J1939-71";
BA_ "SPN" SG_ 2365446654 Joystick2ThetaAxisPos 2701;
BA_ "SAEDocument" SG_ 2365446654 Joystick2ThetaAxisPos "J1939-71";
BA_ "SigType" SG_ 2365446654 Jystck2ThtAxsClckwsPstvPosStatus 4;
BA_ "SPN" SG_ 2365446654 Jystck2ThtAxsClckwsPstvPosStatus 2706;
BA_ "SAEDocument" SG_ 2365446654 Jystck2ThtAxsClckwsPstvPosStatus "J1939-71";
BA_ "SigType" SG_ 2365446654 Jystck2ThetaAxisNeutralPosStatus 4;
BA_ "SPN" SG_ 2365446654 Jystck2ThetaAxisNeutralPosStatus 2716;
BA_ "SAEDocument" SG_ 2365446654 Jystck2ThetaAxisNeutralPosStatus "J1939-71";
BA_ "SPN" SG_ 2365446654 Joystick2GripYAxisPos 2700;
BA_ "SAEDocument" SG_ 2365446654 Joystick2GripYAxisPos "J1939-71";
BA_ "SigType" SG_ 2365446654 Jystck2GrpYAxsLvrFrwrdPstvPsStts 4;
BA_ "SPN" SG_ 2365446654 Jystck2GrpYAxsLvrFrwrdPstvPsStts 2705;
BA_ "SAEDocument" SG_ 2365446654 Jystck2GrpYAxsLvrFrwrdPstvPsStts "J1939-71";
BA_ "SigType" SG_ 2365446654 Jystck2GrpYAxsLvrBckNgtvPsStatus 4;
BA_ "SPN" SG_ 2365446654 Jystck2GrpYAxsLvrBckNgtvPsStatus 2710;
BA_ "SAEDocument" SG_ 2365446654 Jystck2GrpYAxsLvrBckNgtvPsStatus "J1939-71";
BA_ "SigType" SG_ 2365446654 Jystck2GripYAxisNeutralPosStatus 4;
BA_ "SPN" SG_ 2365446654 Jystck2GripYAxisNeutralPosStatus 2715;
BA_ "SAEDocument" SG_ 2365446654 Jystck2GripYAxisNeutralPosStatus "J1939-71";
BA_ "SPN" SG_ 2365446654 Joystick2GripXAxisPos 2699;
BA_ "SAEDocument" SG_ 2365446654 Joystick2GripXAxisPos "J1939-71";
BA_ "SigType" SG_ 2365446654 Jystck2GrpXAxsLvrRghtPstvPsSttus 4;
BA_ "SPN" SG_ 2365446654 Jystck2GrpXAxsLvrRghtPstvPsSttus 2704;
BA_ "SAEDocument" SG_ 2365446654 Jystck2GrpXAxsLvrRghtPstvPsSttus "J1939-71";
BA_ "SigType" SG_ 2365446654 Jystck2GrpXAxsLvrLftNgtvPsStatus 4;
BA_ "SPN" SG_ 2365446654 Jystck2GrpXAxsLvrLftNgtvPsStatus 2709;
BA_ "SAEDocument" SG_ 2365446654 Jystck2GrpXAxsLvrLftNgtvPsStatus "J1939-71";
BA_ "SigType" SG_ 2365446654 Jystck2GripXAxisNeutralPosStatus 4;
BA_ "SPN" SG_ 2365446654 Jystck2GripXAxisNeutralPosStatus 2714;
BA_ "SAEDocument" SG_ 2365446654 Jystck2GripXAxisNeutralPosStatus "J1939-71";
BA_ "SigType" SG_ 2365446654 Jystck2ThtAxsCntrClckwsNgtvPsStt 4;
BA_ "SPN" SG_ 2365446654 Jystck2ThtAxsCntrClckwsNgtvPsStt 2711;
BA_ "SAEDocument" SG_ 2365446654 Jystck2ThtAxsCntrClckwsNgtvPsStt "J1939-71";
VAL_ 2633895166 VehicleSystem5 127 "Not Available" 0 "Ind. Process Control Stationary" ;
VAL_ 2633895166 VehicleSystem4 100 "Deck/Cargo/Fishing equip. sys" 90 "Environmental (HVAC) Systems" 80 "Instrumentation/General Systems" 70 "Communications Systems" 60 "Navigation Systems" 50 "Propulsion Systems" 40 "Steering Systems" 30 "Power Mgmt and lighting systems" 25 "Gateway" 20 "Safety Systems" 10 "System Tools" 127 "Not Available" 0 "Non-specific System" ;
VAL_ 2633895166 VehicleSystem3 8 "Grader" 7 "Four Wheel Drive Loader" 6 "Forklift" 5 "Excavator" 4 "Crawler" 3 "Backhoe" 2 "Articulated Dump Truck" 1 "Skid Steer Loader" 127 "Not Available" 0 "Non-specific System" ;
VAL_ 2633895166 VehicleSystem2 16 "Skidder" 15 "Earth Work" 14 "Special Crops" 13 "Powered Auxiliary Device" 12 "Farm Yard Operations" 11 "Transport/Trailer" 10 "Irrigation" 9 "Forage" 8 "Root Harvesters" 7 "Harvesters" 6 "Sprayers" 5 "Fertilizers" 4 "Planters/Seeders" 3 "Secondary Tillage" 2 "Tillage" 1 "Tractor" 127 "Not Available" 0 "Non-specific System" ;
VAL_ 2633895166 VehicleSystem1 2 "Trailer" 1 "Tractor" 127 "Not Available" 0 "Non-specific System" ;
VAL_ 2633895166 IndustryGroup 6 "Reserved for SAE" 7 "Reserved for SAE" 5 "IndustrialProcessCtrlStationary" 4 "Marine" 3 "Construction" 2 "Agricultural and Forestry" 1 "On-Highway" 0 "Global" ;
VAL_ 2633895166 VehicleSystem 0 "Non-specific System" 127 "Not Available" ;
VAL_ 2633895166 Function 127 "Reserved" 126 "Reserved" 125 "Reserved" 124 "Reserved" 123 "Reserved" 122 "Reserved" 121 "Reserved" 120 "Reserved" 119 "Reserved" 118 "Reserved" 117 "Reserved" 116 "Reserved" 115 "Reserved" 114 "Reserved" 113 "Reserved" 112 "Reserved" 111 "Reserved" 110 "Reserved" 109 "Reserved" 108 "Reserved" 107 "Reserved" 106 "Reserved" 105 "Reserved" 104 "Reserved" 103 "Reserved" 102 "Reserved" 101 "Reserved" 42 "Water Pump Control" 41 "Lighting - Operator Controls" 40 "Seat Control" 39 "Ignition Control Module" 38 "Tire Pressure Control" 37 "Cab Controller" 36 "Pneumatic - System Controller" 35 "Suspension - System Controller" 34 "Hydraulic Pump Controller" 33 "System Monitor" 32 "Headway Controller" 31 "Propulsion Battery Charger" 30 "Management Computer" 29 "Virtual Terminal (in cab)" 28 "Off Vehicle Gateway" 27 "Power TakeOff (Secondary or Front)" 26 "Body Controller" 25 "Network Interconnect ECU" 24 "Vehicle Security" 23 "Vehicle Navigation" 22 "Aerodynamic Control" 21 "Cab Climate Control" 20 "Trip Recorder" 19 "Instrument Cluster" 18 "Suspension - Drive Axle" 17 "Suspension - Steer Axle" 16 "Steering Controller" 15 "Fuel System" 14 "Cruise Control" 13 "Retarder - Driveline" 12 "Retarder - Engine" 11 "Brakes - Drive Axle" 10 "Brakes - Steer Axle" 9 "Brakes - System Controller" 8 "Axle - Drive" 7 "Axle - Steering" 6 "Power TakeOff - (Main or Rear)" 5 "Shift Control/Console" 4 "Battery Pack Monitor" 3 "Transmission" 2 "Electric Propulsion Control" 1 "Auxiliary Power Unit (APU)" 0 "Engine" 100 "Reserved" 99 "Reserved" 98 "Reserved" 97 "Reserved" 96 "Reserved" 95 "Reserved" 94 "Reserved" 93 "Reserved" 92 "Reserved" 91 "Reserved" 90 "Reserved" 89 "Reserved" 88 "Reserved" 87 "Reserved" 86 "Reserved" 85 "Reserved" 84 "Reserved" 83 "Reserved" 82 "Reserved" 81 "Reserved" 80 "Reserved" 79 "Reserved" 78 "Reserved" 77 "Reserved" 76 "Reserved" 75 "Supplemental Fan" 74 "Lubrication System" 73 "Rollover Detection Control" 72 "Coolant Valve Controller" 71 "Transfer Case Control" 70 "Auxiliary Regeneration Device" 69 "Engine Emission Aftertreatement System" 68 "Aftertreatment system gas measurement" 67 "Electrical System Controller" 66 "I/O Controller" 65 "Gas Flow Measurement" 64 "Endurance Braking" 63 "Engine Valve Controller" 62 "On-Board Diagnostic Unit" 61 "File Server/Printer" 60 "Cab Display" 59 "Starter" 58 "Fan Drive Control" 57 "Steering Column Unit" 56 "Communications Unit, Radio" 55 "Communications Unit, Satellite" 54 "Communications Unit, Cellular" 53 "Alternator/Charging System" 52 "Chassis Controller" 51 "Forward-Looking Collision Warning System" 50 "Auxiliary Heater" 49 "Clutch/Converter Control" 48 "Ramp Control" 47 "Information System Controller" 46 "Oil Sensor Unit" 45 "Vehicle Dynamic Stability Control" 44 "Exhaust Emission Control" 43 "Transmission Display" ;
VAL_ 2633895166 ManufacturerCode 381 "B&G" 374 "Northern Lights" 373 "Electronic Design" 371 "Delphi" 370 "Heinzmann GmbH & Co. KG" 369 "Power Torque Engineering Ltd" 368 "HANSENHOF_electronic" 367 "Fliegl Agrartechnik" 366 "Viewnyx Corp." 365 "Digi-Star, LLC" 364 "OEM Controls Inc." 363 "BEI Duncan" 362 "Alois Poettinger Maschinenfabrik GmbH" 361 "InMach" 360 "HJS Fahrzeugtechnik GmbH & Co KG" 359 "Ludwig Bergmann GmbH" 358 "Victron Energy BV" 357 "Hardi International A/S" 356 "Fischer Panda Generators, Inc" 355 "Mastervolt International B.V." 354 "Junkkari OY" 353 "Hegemon Electronics, Inc." 352 "SAME DEUTZ-FAHR" 351 "Thrane & Thrane" 350 "Noris Marine Systems GmbH & Co KG" 349 "Suonentiet" 348 "Amazonen Werke H. Dreyer" 347 "Honeywell" 346 "Control Solutions" 345 "Korean Maritime University" 344 "Parvus Corporation" 343 "Baumer Group" 342 "THOMAS MAGNETE GmbH" 341 "Boning GmbH & Co" 340 "Continental AG" 339 "Competence Center ISOBUS e.V." 338 "GRAF-SYTECO" 337 "Carraro S.p.A." 336 "APE s.r.o." 335 "Evo Electric Ltd" 334 "Takata-Petri AG" 333 "Hadley Products Corporation" 332 "HWH Corporation" 331 "Horton, Inc." 330 "Kidde Aerospace and Defense" 329 "Deif A/S" 328 "Qwerty Electronik AB" 252 "Sensor-Technik Wiedemann GmbH" 251 "German Agricultural Society" 250 "Kuhn Group" 249 "Schaltbau GmbH" 233 "Yacht Monitoring Solutions Inc." 232 "TSD Integrated Controls" 1863 "Thomas G. Faria Co." 1862 "Sanshin" 1861 "Vector CANtech" 1860 "MMP" 1859 "Kvasar AB" 1858 "Litton" 1857 "Simrad" 1856 "Trimble" 1855 "Furuno USA" 1854 "Northstar Technologies" 1853 "Japan Radio Co." 1852 "Navionics" 1851 "Raymarine" 1850 "Teleflex" 222 "Generac Power Systems, Inc." 221 "SiE" 220 "Beede Electrical Instrument Company, Inc." 219 "Cat OEM Solutions" 218 "Gits Manufacturing Company" 217 "RM Michaelides Software & Elektronik GmbH" 216 "Paneltronics Inc." 215 "Aetna Engineering/Fireboy-Xintex" 214 "MC elettronica Srl" 213 "CNH Belgium N.V." 212 "Sure Power Industries, Inc." 211 "DNA Group" 210 "Iteris, Inc." 209 "Bell Equip. Co. SA (PTY) LTD" 208 "Drew Technologies, Inc." 207 "Otto Engineering" 206 "port GmbH" 205 "SmarTire Systems Inc" 204 "The Morey Corporation" 203 "MILtronik GmbH" 202 "Curtis Instruments, Inc." 201 "Disenos y Tecnologia S.A." 200 "MGM Brakes" 199 "Actia Corp." 198 "Mystic Valley Communications" 197 "Mechron Power Systems" 196 "LEMKEN GmbH & Co. KG" 195 "General Engine Products" 194 "TriMark Corporation" 193 "Nobletec" 192 "Floscan" 191 "XATA Corporation" 190 "Hella KGaA Hueck & Co." 189 "QUALCOMM" 188 "EMP Corp." 187 "Air-Weigh" 186 "Altronic, Inc." 185 "Beede Electrical Instrument Company" 184 "EIA Electronics" 183 "KDS Controls, Inc." 182 "Vehicle Systems Engineering B.V." 181 "Coretronics, Inc." 180 "Smart Power Systems" 179 "TeeJet Technologies Denmark" 178 "Siemens VDO Automotive AG" 177 "Diagnostic System Associates" 176 "Moritz Aerospace" 175 "Veris Technologies, Inc." 174 "AB Volvo Penta" 173 "Ryeso, Inc." 172 "Yanmar Marine USA" 171 "Wachendorff Elektronik GmbH & Co. KG" 170 "Computronics Corporation Ltd." 169 "Marlin Technologies Inc." 168 "Xantrex" 167 "JLG Industries Inc." 166 "Phoenix International" 165 "CPAC Systems AB" 164 "DaimlerChrysler Off-Highway" 163 "BRP Inc." 162 "Axiomatic Technologies" 161 "Offshore Systems (UK) Limited" 160 "Nido" 159 "NTech Industries Inc." 158 "Firestone Industrial Products Company" 157 "ISSPRO Inc." 156 "ITT Industries - Cannon" 155 "Vetronix Corporation" 154 "Westerbeke Corporation" 153 "Woodward, Industrial Controls Division" 152 "elobau GmbH & Co. KG" 151 "Raven Industries Inc. - Flow Controls Division" 150 "Fleetguard" 149 "Holset" 148 "Blue Water Data, Inc." 147 "Nautibus Electronic GmbH" 146 "Maxima Technologies" 145 "MurCal Controls" 144 "Mercury Marine" 143 "W. Gmeiner GmbH & Co." 142 "TRW Automotive (Commercial Steering Systems)" 141 "Thales Navigation Ltd." 140 "Lowrance Electronics, Inc." 139 "Caterpillar Trimble Control Technologies (CTCT), LLC" 138 "Georg Fritzmeier GmbH & Co. KG" 137 "Maretron" 136 "Komatsu Ltd." 135 "Airmar Technology Corporation" 134 "Iris Technology Ltd." 133 "Bucher Schoerling GmbH" 132 "Mulag-Fahrzeugwerk" 131 "ITT Industries" 130 "Nido - Universal Machines B.V." 129 "OMNEX Control Systems, Inc." 128 "Gerhard Duecker GmbH & Co. KG" 127 "Holland USA" 126 "Driver Tech" 125 "Nevada Automotive Test Center" 124 "Hydac Electronic" 123 "Basler Electric" 122 "FG Wilson (Engineering) Limited" 121 "HED (Hydro Electronic Devices, Inc.)" 120 "RDS Technology Ltd." 119 "IntegriNautics" 118 "Intron GmbH" 117 "HUSCO International" 116 "BEELINE Technologies" 115 "NACCO Materials Handling Group, Inc." 114 "EControls, Inc." 113 "Stress-Tek, Inc." 112 "MECALAC" 111 "Maschinenfabrik Bernhard Krone GmbH" 110 "EPIQ Sensor-Nite" 109 "TeeJet Technologies Denmark" 108 "WTK-Elecktronik GmbH" 107 "Grimme Landmaschinen GmbH & Co. KG" 106 "BAE Systems Controls, Inc." 105 "Kiepe Elektrik GmbH & Co. KG" 104 "Claas Selbstfahrende Erntemaschinen GmbH" 103 "Agrocom GmbH & Co. Agrarsystem KG" 102 "AGCO GmbH & Co." 101 "Sensoria" 100 "VDO Technik AG" 99 "International Transmissions Ltd (ITL)" 98 "Mueller-Elektronik GmbH & Co." 97 "Ag Leader Technology, Inc." 96 "Mech@tronic IT GmbH" 95 "Pacific Insight Electronics Corp." 94 "CNH Global N.V." 93 "Perkins Engines Company Ltd." 92 "Ag-Chem Equipment Co., Inc." 91 "BSG Bodensee Steuergeraete GmbH" 90 "Knorr-Bremse SfN GmbH" 89 "Kverneland Group, Electronics Division" 88 "Satloc Precision GPS" 87 "J.C. Bamford Excavators Ltd (JCB)" 86 "C.E. Niehoff & Company" 85 "Kohler Co." 84 "New Holland UK Limited" 83 "Eaton VORAD Technologies" 82 "Bobcat/Ingersoll-Rand" 81 "Fire Research Corp" 80 "Twin Disc, Inc." 79 "Daimler Benz AG - Engine Division (PBM)" 78 "Frank W. Murphy Manufacturing, Inc." 77 "Deere Power Systems Group" 76 "unused" 75 "Deere & Co. Agricultural Division" 74 "Eaton Axle-Brake Division" 73 "LeTourneau, Inc." 72 "Sisu Corporation" 71 "Vansco Electronics Ltd." 70 "Flex-Coil Limited" 69 "Trimble Navigation" 68 "Scania" 67 "Funk Manufacturing Company" 66 "John Deere Construction Equipment Division" 65 "MAN Nutzfahrzeuge AG" 64 "unused" 63 "ZF Industries Inc." 62 "Wabco" 61 "Volvo Truck Corp." 60 "Volvo Trucks North America Inc." 59 "VES Inc." 58 "SPX Corporation, OTC Division" 57 "Sauer-Danfoss Co." 56 "SAIC" 55 "Ryder System Inc." 54 "Meritor Wabco" 53 "Continental Automotive Systems US, Inc." 52 "Meritor Automotive, Inc." 51 "Robert Bosch GmbH" 50 "Robert Bosch Corp" 49 "RE America Inc." 48 "Pollak Alphabet" 47 "Phillips Semiconductor" 46 "Parasoft Computing Solutions" 45 "PACCAR" 44 "Nippondenso Co. Ltd." 43 "International Truck and Engine Corp. Vehicle Electronics" 42 "International Truck and Engine Corp. Engine Electronics" 41 "Motorola Inc." 40 "Motorola AIEG Inc." 39 "Microfirm Inc." 38 "Micro Processor Systems Inc." 37 "Mack Trucks Inc." 36 "Lucas Ltd." 35 "Kenworth Truck Co." 34 "Kelsey Hayes Co." 33 "John Deere" 32 "Jacobs Vehicle Systems" 31 "J Pollak Corp." 30 "Isuzu Motors Ltd." 29 "Hino Motors Ltd." 28 "Grote Ind. Inc." 27 "GMC" 26 "General Motors Corp., Service Technology Group" 25 "Daimler Trucks North America LLC" 24 "Ford Motor Co., Vehicle Controls" 23 "Ford Motor Co., Heavy Truck" 22 "Ford Motor Co., Electronic Concepts $ Systems" 21 "Echilin Inc., Midland Brake Inc." 20 "Eaton Ltd" 19 "Eaton Corp. Trucking Info Services" 18 "Eaton Corp, Transmission Division" 17 "Eaton Corp. Res & Dev" 16 "Eaton Corp." 15 "Dickey-John Corp." 14 "Detroit Diesel Corporation" 13 "Delco Electronics" 12 "Deere & Company, Precision Farming" 11 "Dearborn Group Inc." 10 "Cummins Engine Co." 9 "Chrysler Corp." 8 "Caterpillar Inc." 7 "Case Corp." 6 "Berifors Electronics AB" 5 "AMP Inc." 4 "Ametek-Dixson" 3 "Ametek, US Gauge Division" 2 "Allison Transmission, GMC" 1 "Allied Signal Inc." 0 "Reserved" 231 "Topcon Positioning Systems, Inc." 230 "Saucon Technologies" 229 "Garmin International Inc." 228 "ZF Marine Electronics" 227 "Lykketronic A/S" 226 "Monaco Coach Corporation" 225 "SKF" 224 "EMMI Network, S.L." 223 "Vaueo Retarder Co., Ltd." 263 "IMMI" 262 "HydraForce, Inc" 261 "Red Dot Corporation" 260 "Reichhardt GmbH" 259 "Jetter AG" 258 "ARAG" 257 "Honda Motor Co., Ltd" 256 "Tyco Electronics AMP" 255 "MEAS France" 254 "GE Sensing" 253 "Mobile Control Systems" 298 "Holley Performance" 297 "Zonar Systems Inc" 296 "micro dynamics GmbH" 295 "BEP Marine" 294 "Grayhill Inc." 293 "Spyder Controls Corp." 292 "IKUSI - Angel Iglesias S.A." 291 "Groeneveld Transport Efficiency BV" 290 "Kuebler GmbH" 289 "Watlow" 288 "Mitsubishi FUSO Truck & Bus Corp." 287 "NTech Industries, Inc" 286 "Coelmo srl" 285 "Sea Recovery Corp" 284 "Mobile Tech Chile" 283 "CWF Hamilton & Co Ltd" 282 "Medallion Instrumentation Systems" 281 "Precision Governors LLC" 311 "Patrick Power Products" 310 "TECNORD srl" 309 "Krauss-Maffei Wegmann GmbH & Co. KG" 308 "Cyntrx" 307 "MAS Technologies" 306 "Sleipner Motor AB" 305 "NovAtel Inc" 304 "EmpirBus AB" 303 "CTS Corporation" 302 "Nissin Kogyo Co., LTD" 301 "Parker Hannifin (UK) Ltd FDE group" 300 "Systron Donner Automotive" 299 "Rauch Landmaschinen GmbH" 280 "Leica Geosystems Pty Ltd" 279 "Geometris LP" 278 "Takata Electronics" 277 "LHP Telematics" 276 "Aqua-Hot Heating Systems" 275 "Navico Egersund AS" 274 "LTW Technology Co., LTD" 273 "Active Research Limited" 272 "Gross Mechanical Laboratories, Inc" 327 "Sonceboz SA" 326 "Akron Brass Company" 325 "ASM Automation Sensorik Messtechnik GmbH" 324 "Snap-on Diagnostics" 323 "Mobileye Vision Technologies Ltd." 322 "MICHENKA s.r.o." 321 "Ultra Electronics, Electrics" 320 "Miedema Landbouwwerktuigenfabriek B.V." 319 "Cadec Global" 318 "SAT Plan" 317 "Navtronics Bvba" 316 "ITT Flow Control" 315 "Icom Incorporated" 314 "CSM GmbH" 313 "Ilmor Engineering, Inc" 312 "Lectronix, Inc." 271 "Cole Hersee" 270 "Tennant" 269 "Saft America Inc.,  Space & Defense Division" 268 "Accurate Technologies" 267 "Red Lion Controls, Inc" 266 "International Thermal Research Ltd" 265 "MTS Sensor Technologie GmbH" 264 "Autolync" 248 "Cooper Standard Automotive Active Systems Group" 247 "ePULSE" 246 "Class 1, Inc" 245 "Capstan Ag Systems, Inc." 244 "Techno-Matic" 243 "eRide, Inc." 242 "Kokusandenki Co. Ltd" 241 "Schneider Automation SAS " 240 "Vanair Mfg" 239 "May & Scofield Ltd" 238 "ZF Friedrichshafen AG" 237 "Agtron Enterprises Inc" 236 "Norac Systems International Inc" 235 "SailorMade Marine Telemetry - Tetra Technology Ltd." 234 "Mondial electronic GmbH" ;
VAL_ 2566847486 DrvlineRetarderOverheatIndicator 3 "Not available" 2 "Driveline Retarder Overheat Indicator is flashing" 1 "Driveline Retarder Overheat Indicator is on continuously" 0 "Driveline Retarder Overheat Indicator is off" ;
VAL_ 2631859966 SteerStraightAheadPosReset 3 "Not applicable" 2 "Reserved take no action" 1 "Reset" 0 "Take no action  Do not Reset" ;
VAL_ 2631859966 EngBuildHoursReset 2 "Reserved" 3 "Take no action" 1 "Reset" 0 "Do not reset" ;
VAL_ 2631859966 TripGroup2Proprietary 2 "Reserved" 3 "Not applicable" 1 "Reset" 0 "Take no action" ;
VAL_ 2631859966 TripGroup1 2 "Reserved" 3 "Not applicable" 1 "Reset" 0 "Take no action" ;
VAL_ 2566840830 RetarderLocation 15 "Not available" 14 "Other" 5 "Trailer Vehicle speed" 4 "Secondary Driveline Output Shaft rpm" 3 "Secondary Transmission Output Output Shaft rpm" 2 "Primary Transmission Input Engine rpm" 1 "Primary Engine Exhaust Brake Exhaust pressure" 0 "Primary Engine Compression Release Brake Engine rpm" ;
VAL_ 2566840830 RetarderType 15 "Not available" 14 "Other" 4 "Exhaust" 3 "Compression Release Engine retarder" 2 "Cooled Friction" 1 "Hydraulic" 0 "Electric/Magnetic" ;
VAL_ 2566844670 OprtrEngPTOGvrnrMmrySelectSwitch 3 "not available" 2 "error" 1 "PTO set speed memory 2 selected" 0 "PTO set speed memory 1 selected" ;
VAL_ 2566844670 EngRmtPTOGvrnrVrblSpedCtrlSwitch 3 "Not available" 2 "Error" 1 "On" 0 "Off" ;
VAL_ 2566844670 EngRmtPTOGvrnrPrprgrmmdSpdCtrlSw 3 "Not available" 2 "Error" 1 "On" 0 "Off" ;
VAL_ 2566844670 EngPTOGvrnrCast_DecelerateSwitch 3 "Not available" 2 "Error" 1 "On" 0 "Off" ;
VAL_ 2566844670 EngPTOGovernorSetSwitch 3 "Not available" 2 "Error" 1 "On" 0 "Off" ;
VAL_ 2566844670 EngPTOGovernorResumeSwitch 3 "Not available" 2 "Error" 1 "On" 0 "Off" ;
VAL_ 2566844670 EngPTOGovernorEnableSwitch 3 "Not available" 2 "Error" 1 "On" 0 "Off" ;
VAL_ 2566844670 EngPTOGovernorAccelerateSwitch 3 "Not available" 2 "Error" 1 "On" 0 "Off" ;
VAL_ 2566844670 RmtPTOGvrnrPrprgrmmdSpdCtrlSwtch 3 "Not Available" 2 "Error" 1 "On" 0 "Off" ;
VAL_ 2566844670 AuxInputIgnoreSwitch 3 "Not Available" 2 "Error" 1 "On" 0 "Off" ;
VAL_ 2566770174 RearWasherFunction 7 "Not available do not change" 4 "110 Reserved" 3 "High" 2 "Medium" 1 "Low" 0 "Off" ;
VAL_ 2566770174 FrontOperatorWasherSwitch 7 "Not available do not change" 4 "110 Reserved" 3 "High" 2 "Medium" 1 "Low" 0 "Off" ;
VAL_ 2566770174 FrontNonoperatorWasherSwitch 7 "Not available do not change" 4 "110 Reserved" 3 "High" 2 "Medium" 1 "Low" 0 "Off" ;
VAL_ 2566770174 RearWiperSwitch 7 "1110 Reserved" 6 "Mist position where external sensor controls wiper rate" 5 "Delayed 2 used for the second delay choice when the wiper switch position controls the delay" 4 "Delayed 1 used for the first delay choice when the wiper switch position controls the delay" 2 "Medium" 15 "Not available do not change" 3 "High" 1 "Low" 0 "Off" ;
VAL_ 2566770174 FrontOperatorWiperSwitch 7 "1110 Reserved" 6 "Mist position where external sensor controls wiper rate" 5 "Delayed 2 used for the second delay choice when the wiper switch position controls the delay" 4 "Delayed 1 used for the first delay choice when the wiper switch position controls the delay" 2 "Medium" 15 "Not available do not change" 3 "High" 1 "Low" 0 "Off" ;
VAL_ 2566770174 FrontNonoperatorWiperSwitch 15 "Not available do not change" 7 "1110 Reserved" 6 "Mist position where external sensor controls wiper rate" 5 "Delayed 2 used for the second delay choice when the wiper switch position controls the delay" 4 "Delayed 1 used for the first delay choice when the wiper switch position controls the delay" 3 "High" 2 "Medium" 1 "Low" 0 "Off" ;
VAL_ 2566769662 EngAltDroopAuxInputSelect 15 "Not available" 14 "Error condition" 1 "thru 1101  One of Alternate Droop Setting 1 through 13 in sequential order is selected" 0 "Normal Droop Setting is selected" ;
VAL_ 2566769662 EngAltDroopRemoteAccelSelect 15 "Not available" 14 "Error condition" 1 "thru 1101  One of Alternate Droop Setting 1 through 13 in sequential order is selected" 0 "Normal Droop Setting is selected" ;
VAL_ 2566769662 EngAltDroopAccel2Select 15 "Not available" 14 "Error condition" 1 "thru 1101  One of Alternate Droop Setting 1 through 13 in sequential order is selected" 0 "Normal Droop Setting is selected" ;
VAL_ 2566769662 EngAltDroopAccel1Select 15 "Not available" 14 "Error condition" 1 "thru 1101  One of Alternate Droop Setting 1 through 13 in sequential order is selected" 0 "Normal Droop Setting is selected" ;
VAL_ 2566769662 EngAltLowIdleSwitch 3 "Not available or Unused" 2 "Error" 1 "Alternate low idle point is selected" 0 "Default low idle point is selected" ;
VAL_ 2566769662 EngSynchronizationSwitch 3 "Not available or Unused" 2 "Error" 1 "Functionality is enabled on" 0 "Functionality is disabled off" ;
VAL_ 2566769662 EngAuxGovernorSwitch 2 "Error condition" 1 "Auxiliary Governor is enabled" 0 "Auxiliary Governor is disabled" 3 "Not available" ;
VAL_ 2566768638 EngAltDroopAuxInputSelectState 15 "Not available" 14 "SAE reserved" 1 "thru 1101  Control state is One of Alternate Droop Setting 1 through 13 in sequential order" 0 "Control state is Normal Droop Setting" ;
VAL_ 2566768638 EngAltDropRemoteAccelSelectState 15 "Not available" 14 "SAE reserved" 1 "thru 1101  Control state is One of Alternate Droop Setting 1 through 13 in sequential order" 0 "Control state is Normal Droop Setting" ;
VAL_ 2566768638 EngAltDroopAccel2SelectState 15 "Not available" 14 "SAE reserved" 1 "thru 1101  Controls state is One of Alternate Droop Setting 1 through 13 in sequential order" 0 "Controls state is Normal Droop Setting" ;
VAL_ 2566768638 EngAltDroopAccel1SelectState 15 "Not available" 14 "SAE reserved" 1 "thru 1101  Control state is one of Alternate Droop Setting 1 through 13 in sequential order" 0 "Control state is Normal Droop Setting" ;
VAL_ 2566768638 EngAltRatingSelectState 1 "Control state is Alternate Power Fueling 1" 0 "Control state is Maximum Power Fueling" ;
VAL_ 2566768638 EngAltLowIdleSelectState 3 "not available" 2 "SAE reserved" 1 "Alternate idle state" 0 "Normal idle state" ;
VAL_ 2566768638 EngMultiUnitSyncState 3 "Not available" 2 "SAE reserved" 1 "Control State is Functionality enabled on" 0 "Control State is Functionality disabled off" ;
VAL_ 2566768638 EngAuxGovernorState 3 "Not available" 2 "SAE reserved" 1 "Control State is Auxiliary Governor enabled" 0 "Control State is Auxiliary Governor disabled" ;
VAL_ 2365443326 HighLowBeamSwitch 3 "Not available do not change" 2 "Error" 1 "High Beam Selected" 0 "Low Beam Selected" ;
VAL_ 2365443326 HazardLightSwitch 3 "Not available do not change" 2 "Error" 1 "Hazard Lamps to be Flashing" 0 "Hazard Lamps to be Off" ;
VAL_ 2365443326 TurnSignalSwitch 2 "Right turn to be Flashing" 15 "Not available do not change" 14 "Error to include both left and right selected simultaneously" 3 "1101 Reserved" 1 "Left Turn to be Flashing" 0 "No Turn being signaled" ;
VAL_ 2365443326 MainLightSwitch 9 "1101 Reserved" 8 "Delayed Off  The position by which the operator selects that a certain set of lamps are to come On and then are to" 4 "0111 Reserved" 2 "Headlight On  The position by which the operator selects that the headlamps are to be on" 15 "Not available do not change" 14 "Error" 3 "Headlight and Park On  The position by which the operator selects that Both the Headlamps and the Park lamps" 1 "Park On  The position by which the operator selects that the park lamps are to be on" 0 "Off  The position by which the operator selects that none of the lamps are to be on" ;
VAL_ 2365443326 WorkLightSwitch 4 "Work Light Combination 4 On  The position by which the operator selects that the lamps in the combination" 2 "Work Light Combination 2 On  The position by which the operator selects that the lamps in the combination" 15 "Not available do not change" 14 "Error" 3 "Work Light Combination 3 On  The position by which the operator selects that the lamps in the combination" 1 "Work Light Combination 1 On  The position by which the operator selects that the lamps in the combination" 0 "Off  The position by which the operator selects that none of the work lamps are to be on" ;
VAL_ 2566802686 BlackOutWorkLampSelect 3 "Not Supported" 2 "Reserved" 1 "On" 0 "Off" ;
VAL_ 2566802686 NightVisionIlluminatorSelect 3 "Not Supported" 2 "Reserved" 1 "On" 0 "Off" ;
VAL_ 2566802686 BlackOutBrake_StopLampSelect 3 "Not Supported" 2 "Reserved" 1 "On" 0 "Off" ;
VAL_ 2566802686 ConvoyDrivingLampSelect 3 "Not Supported" 2 "Reserved" 1 "On" 0 "Off" ;
VAL_ 2566802686 ConvoyLampSelect 3 "Not Supported" 2 "Reserved" 1 "On" 0 "Off" ;
VAL_ 2566802686 FrontBlackOutMarkerLampSelect 3 "Not Supported" 2 "Reserved" 1 "On" 0 "Off" ;
VAL_ 2566802686 RearBlackOutMarkerSelect 3 "Not Supported" 2 "Reserved" 1 "On" 0 "Off" ;
VAL_ 2566774014 SlowVesselModeStatus 3 "Take no action" 2 "Reserved" 1 "Slow vessel mode is ACTIVE" 0 "Slow vessel mode is OFF" ;
VAL_ 2566774014 TrollingModeStatus 3 "Take no action" 2 "Reserved" 1 "Trolling mode is ACTIVE" 0 "Trolling mode is OFF" ;
VAL_ 2566774014 EngThrttlSynchrnzationModeStatus 15 "Take no action" 4 "Synchronized Master" 3 "Synchronized Starboard" 2 "Synchronized Port" 1 "Synchronized Center" 0 "Not Synchronized" ;
VAL_ 2432595710 DisplayDeadbands 15 "Not Available" 3 "1110 Reserved" 2 "Wide  / 24mm" 1 "Standard  / 12mm" 0 "Narrow  / 45mm" ;
VAL_ 2432595710 LEDPatternCtrl 15 "Not Available" 3 "1110 Reserved" 2 "7 Channel" 1 "Offset" 0 "5 Channel" ;
VAL_ 2432595710 LEDDisplayDeadbandCtrl 15 "Not Available or Not applicable" 5 "1110 Reserved" 4 "/ 1 mm 0003 feet 004 inches" 3 "/ 5 mm 0017 feet 02 inches" 2 "/ 24 mm 0080 feet 096 inches" 1 "/ 12 mm 0040 feet 045 inches" 0 "/ 45 mm 0015 feet 018 inches" ;
VAL_ 2432595710 LEDDisplayModeCtrl 15 "Not Available or Not Applicable" 3 "1110 Reserved" 2 "Center OnGrade Display Mode 2  7 CHANNEL" 1 "Offset OnGrade Display Mode" 0 "Center OnGrade Display Mode 1  5 CHANNEL" ;
VAL_ 2432595710 LEDDisplayData1 254 "Error" 159 "No data ie no laser strikes" 149 "High Coarse" 148 "High Medium/Coarse" 147 "High Medium" 146 "High Medium/Fine" 145 "High Fine" 144 "On Grade" 132 "Low Fine" 131 "Low Medium/Fine" 130 "Low Medium" 129 "Low Medium/Coarse" 128 "Low Coarse" 32 "Low Coarse LED on" 16 "Low Fine LED on" 8 "Ongrade LED on" 4 "High Fine LED on" 2 "High Coarse LED on" ;
VAL_ 2365485566 LaserTracerInformation 32 "Curb 1  yes" 16 "Stringline 1  yes" 8 "Previous pass 1  yes" 4 "Valid target 1  yes" 2 "Laser is ready" 1 "Laser power is on" ;
VAL_ 2365485566 LEDDisplayData2 64 "Right LED on" 32 "Left LED on" 16 "Down LED on" 8 "Up LED on" 4 "Ongrade C LED on" 2 "Ongrade B LED on" 1 "Ongrade A LED on" ;
VAL_ 2364542462 StElvtnSensor2ReferenceElevation 3 "Dont Care / Take No Action" 2 "Reserved" 1 "Set Reference Elevation" 0 "Do not Set Reference Elevation" ;
VAL_ 2364542462 StElvtnSensor1ReferenceElevation 3 "Dont Care / Take No Action" 2 "Reserved" 1 "Set Reference Elevation" 0 "Do not Set Reference Elevation" ;
VAL_ 2364542462 SdshftDsrdBldeOffsetOperatorCtrl 15 "Not Installed" 14 "Error Indicator" 4 "1101 Reserved" 3 "Automatic Operator Control Request" 2 "Manual Operator Control Request" 0 "No Operator Control Request" 1 "Momentary Operator Control Request" ;
VAL_ 2364542462 SdshiftBladeCtrlModeOperatorCtrl 15 "Not installed" 14 "Error Indicator" 2 "Decrement Operator Control Request" 0 "No Operator Control Request" 1 "Increment Operator Control Request" ;
VAL_ 2364542462 RghtDsredBladeOffsetOperatorCtrl 15 "Not installed" 14 "Error Indicator" 3 "1101 Reserved" 2 "Decrement Operator Control Request" 0 "No Operator Control Request" 1 "Increment Operator Control Request" ;
VAL_ 2364542462 LftDsiredBladeOffsetOperatorCtrl 15 "Not installed" 14 "Error Indicator" 3 "1101 Reserved" 2 "Decrement Operator Control Request" 0 "No Operator Control Request" 1 "Increment Operator Control Request" ;
VAL_ 2364542462 RightBladeCtrlModeOperatorCtrl 15 "Not Installed" 14 "Error Indicator" 3 "Automatic Operator Control Request" 2 "Manual Operator Control Request" 0 "No Change" 1 "Momentary Operator Control Request" ;
VAL_ 2364542462 LeftBladeCtrlModeOperatorCtrl 15 "Not Installed" 14 "Error Indicator" 12 "1101 Reserved" 3 "Automatic Operator Control Request" 2 "Manual Operator Control Request" 0 "No Change" 1 "Momentary Operator Control Request" ;
VAL_ 2364542462 BladeAutoModeCmd 4 "Auto Not Allowed  Auto mode is not allowed under any condition" 3 "Service Mode  Auto mode is permitted only for special services such as calibrations" 2 "Suspend Auto  Auto mode is temporarily not allowed and the control issuing this command wants the primary" 1 "Activity Allows Auto  Auto mode permitted only if the primary control system detects operator activity The control" 0 "Auto Allowed  Auto mode permitted as appropriate auto button was pushed or directly returned from Suspend" ;
VAL_ 2364542462 DesiredGradeOffsetSwitch 15 "Not installed" 14 "Error Indicator" 2 "Decrement button pressed" 0 "No button pressed" 1 "Increment button pressed" ;
VAL_ 2364542462 BladeCtrlModeSwitch 15 "Not Installed" 14 "Error Indicator" 3 "Automatic button pressed" 2 "Manual button pressed" 0 "No button pressed" 1 "Mode button pressed" ;
VAL_ 2633883646 FrontWheelDriveActuatorStatus 3 "Not Available" 2 "Error" 1 "Front Wheel Drive Actuator engaged" 0 "Front Wheel Drive Actuator not engaged" ;
VAL_ 2633880062 FMSstandardRequestsSupported 3 "Dont care" 2 "Reserved" 1 "On request mode is supported" 0 "On request mode is not supported" ;
VAL_ 2633880062 FMSstandardDiagnosticsSupported 3 "Dont care" 2 "Reserved" 1 "Diagnostics Is Supported" 0 "Diagnostics Is Not Supported" ;
VAL_ 2566806526 LnDpartureIndicationEnableStatus 3 "Not Used" 2 "Reserved" 1 "Lane Departure Indication enabled" 0 "Lane Departure indication disabled" ;
VAL_ 2566806526 LaneTrackingStatusLeftSide 3 "Dont care/Take no action" 2 "Reserved" 1 "Tracking Left side" 0 "Not Tracking Left side" ;
VAL_ 2566806526 LaneTrackingStatusRightSide 3 "Dont Care/take no action" 2 "Reserved" 1 "Tracking Right side" 0 "Not Tracking Right side" ;
VAL_ 2431649790 LaneDepartureImminentLeftSide 3 "Not used" 2 "Reserved" 1 "Imminent" 0 "Not imminent" ;
VAL_ 2431649790 LaneDepartureImminentRightSide 3 "Not Used" 2 "Reserved" 1 "Imminent" 0 "Not imminent" ;
VAL_ 2431649790 LaneDepartureRight 3 "Take no action" 2 "Reserved" 1 "Middle of the vehicle departs the lane to the right side" 0 "Middle of the vehicle does not depart the lane to the right side" ;
VAL_ 2431649790 LaneDepartureLeft 3 "Take no action" 2 "Reserved" 1 "Middle of the vehicle departs the lane to the left side" 0 "Middle of the vehicle does not depart the lane to the left side" ;
VAL_ 2633929214 EngFuelLeakage2 3 "Not available" 2 "Error" 1 "leakage detected" 0 "no leakage detected" ;
VAL_ 2633929214 EngFuelLeakage1 3 "Not available" 2 "Error" 1 "leakage detected" 0 "no leakage detected" ;
VAL_ 2566831614 FanDriveState 15 "Not available" 14 "Other" 13 "Engine brake" 12 "Timer" 11 "A/C system" 10 "Transmission retarder" 9 "Manual control" 8 "Reverse Operation" 7 "Default Operation" 6 "Excessive hydraulic oil temperature" 5 "Excessive transmission oil temperature" 4 "Excessive engine coolant temperature" 3 "Excessive engine oil temperature" 2 "Excessive engine air temperature" 1 "Engine systemGeneral" 0 "Fan off" ;
VAL_ 2566820094 EngTorqueLimitFeature 7 "Not available" 4 "Current torque rating" 3 "Previous torque rating rating prior to the current rating" 2 "First torque rating" 1 "Highest torque rating" 0 "Reserved" ;
VAL_ 2566820094 TorqueLimitingFeatureStatus 3 "Not available" 2 "Error" 1 "Enabled" 0 "Disabled" ;
VAL_ 2566802174 TrnsRverseGearShiftInhibitStatus 3 "Not Available" 2 "Error" 1 "Reverse gear shifts are currently inhibited" 0 "Reverse gear shifts are currently allowed" ;
VAL_ 2566802174 TransWarningIndicator 3 "Not available" 2 "Transmission Warning Indicator is flashing" 1 "Transmission Warning Indicator is on continuously" 0 "Transmission Warning Indicator is off" ;
VAL_ 2566802174 TransMode8Indicator 3 "Take no action" 2 "Reserved" 1 "Enable" 0 "Disable" ;
VAL_ 2566802174 TransMode7Indicator 3 "Take no action" 2 "Reserved" 1 "Enable" 0 "Disable" ;
VAL_ 2566802174 TransMode6Indicator 3 "Take no action" 2 "Reserved" 1 "Enable" 0 "Disable" ;
VAL_ 2566802174 TransMode5Indicator 3 "Take no action" 2 "Reserved" 1 "Enable" 0 "Disable" ;
VAL_ 2566802174 TransMode1Indicator 3 "Not available" 2 "Error" 1 "Transmission Mode 1 Active" 0 "Transmission Mode 1 not active" ;
VAL_ 2566802174 TransMode2Indicator 3 "Not available" 2 "Error" 1 "Transmission Mode 2 Active" 0 "Transmission Mode 2 not active" ;
VAL_ 2566802174 TransMode3Indicator 3 "Not available" 2 "Error" 1 "Transmission Mode 3 Active" 0 "Transmission Mode 3 not active" ;
VAL_ 2566802174 TransMode4Indicator 3 "Not available" 2 "Error" 1 "Transmission Mode 4 Active" 0 "Transmission Mode 4 not active" ;
VAL_ 2566802174 TransShiftInhibitIndicator 3 "Take no action" 2 "Reserved" 1 "Active shift is inhibited" 0 "Inactive shift is not inhibited" ;
VAL_ 2566802174 TransEngCrankEnable 3 "Not available" 2 "Error" 1 "Cranking enabled engine cranking is allowed by the transmission" 0 "Cranking disabled engine cranking is prohibited by the transmission" ;
VAL_ 2566802174 ActiveShiftConsoleIndicator 3 "Not available" 2 "Reserved" 1 "Secondary shift console is active" 0 "Primary shift console is active" ;
VAL_ 2566802174 TransReadyForBrakeRelease 3 "Not available" 2 "Error" 1 "Transmission Ready for Brake Release" 0 "Transmission Not Ready for Brake Release" ;
VAL_ 2566802174 TrnsRqstedRangeDisplayFlashState 3 "Take no action" 2 "Reserved" 1 "Active Transmission Requested Range display should be flashing" 0 "Inactive Transmission Requested Range display should not be flashing" ;
VAL_ 2566802174 TrnsRqstedRangeDisplayBlankState 3 "Take no action" 2 "Reserved" 1 "Active Transmission Requested Range display should be blanked" 0 "Inactive Transmission Requested Range display should not be blanked" ;
VAL_ 2566802174 TransServiceIndicator 3 "Not available" 2 "Transmission Service Indicator is flashing" 1 "Transmission Service Indicator is on continuously" 0 "Transmission Service Indicator is off" ;
VAL_ 2633942014 TransForwardDirectionSwitch 3 "Not available" 2 "Error" 1 "On" 0 "Off" ;
VAL_ 2633942014 TransNeutralSwitch 3 "Not available" 2 "Error" 1 "On" 0 "Off" ;
VAL_ 2633942014 TransReverseDirectionSwitch 3 "Not available" 2 "Error" 1 "On" 0 "Off" ;
VAL_ 2633942014 TransLowRangeSenseSwitch 3 "Not available" 2 "Error" 1 "On" 0 "Off" ;
VAL_ 2633942014 TransHighRangeSenseSwitch 3 "Not available" 2 "Error" 1 "On" 0 "Off" ;
VAL_ 2633943038 TransInertiaBrakeActuator 3 "Not available" 2 "Error" 1 "On" 0 "Off" ;
VAL_ 2633943038 TransDefuelActuator 3 "Not available" 2 "Error" 1 "On" 0 "Off" ;
VAL_ 2633943038 TransLockupClutchActuator 3 "Not available" 2 "Error" 1 "On" 0 "Off" ;
VAL_ 2633943038 TransClutchActuator 3 "Not available" 2 "Error" 1 "On" 0 "Off" ;
VAL_ 2633943038 TransSplitterIndirectActuator 3 "Not available" 2 "Error" 1 "On" 0 "Off" ;
VAL_ 2633943038 TransSplitterDirectActuator 3 "Not available" 2 "Error" 1 "On" 0 "Off" ;
VAL_ 2633943038 TransRangeLowActuator 3 "Not available" 2 "Error" 1 "On" 0 "Off" ;
VAL_ 2633943038 TransRangeHighActuator 3 "Not available" 2 "Error" 1 "On" 0 "Off" ;
VAL_ 2633943038 TransShiftFingerGearActuator2 3 "Not available" 2 "Error" 1 "On" 0 "Off" ;
VAL_ 2633943038 TransShiftFingerRailActuator2 3 "Not available" 2 "Error" 1 "On" 0 "Off" ;
VAL_ 2633943038 TransShiftFingerGearActuator1 3 "Not available" 2 "Error" 1 "On" 0 "Off" ;
VAL_ 2633943038 TransShiftFingerRailActuator1 3 "Not available" 2 "Error" 1 "On" 0 "Off" ;
VAL_ 2633943038 TrnsShftFngerCenterRailIndicator 3 "Not available" 2 "Error" 1 "On" 0 "Off" ;
VAL_ 2633943038 TrnsShftFngerEngagementIndicator 3 "Not available" 2 "Error" 1 "On" 0 "Off" ;
VAL_ 2633943038 TransShiftFingerNeutralIndicator 3 "Not available" 2 "Error" 1 "On" 0 "Off" ;
VAL_ 2364539646 MomentaryEngMaxPowerEnable 3 "not available" 2 "fault" 1 "momentarily requesting maximum power available" 0 "not requesting maximum power available" ;
VAL_ 2364539646 ProgressiveShiftDisable 2 "Reserved" 3 "Take no action" 1 "Progressive shift is disabled" 0 "Progressive shift is not disabled" ;
VAL_ 2364539646 EngMomentaryOverspeedEnable 3 "Take no action" 2 "Reserved" 1 "Momentary engine overspeed is enabled" 0 "Momentary engine overspeed is disabled" ;
VAL_ 2364539646 TrnsTrqCnvrtrLckpTrnstnInProcess 3 "Not available" 2 "Error" 1 "Transition is in process" 0 "Transition is not in process" ;
VAL_ 2364539646 TransShiftInProcess 3 "Not available" 2 "Error" 1 "Shift in process" 0 "Shift is not in process" ;
VAL_ 2364539646 TrnsTorqueConverterLockupEngaged 3 "Not available" 2 "Error" 1 "Torque converter lockup engaged" 0 "Torque converter lockup disengaged" ;
VAL_ 2364539646 TransDrivelineEngaged 3 "Not available" 2 "Error" 1 "Driveline engaged" 0 "Driveline disengaged" ;
VAL_ 2565868542 TypeOfSteerTrans 15 "Not available" 3 "Hybrid steering transmission" 2 "Purely electric steering transmission" 1 "Purely hydraulic steering transmission" 0 "Purely mechanical steering transmission" ;
VAL_ 2565868542 TypeOfSteerForces 15 "Not Available" 3 "Self tracking steering equipment" 2 "Full power steering equipment" 1 "Power assisted steering equipment" 0 "Manual steering equipment" ;
VAL_ 2565868542 SteerType 15 "Not Available" 1 "Auxiliary steering equipment" 0 "Main steering system" ;
VAL_ 2565868542 SteerableLiftAxleLoweringInhibit 3 "Not available" 2 "Reserved" 1 "Lowering inhibited" 0 "Lowering allowed" ;
VAL_ 2565868542 StatusOfSteerAxle 15 "Not available" 5 "Axle steering in special mode diagnosis calibration mode" 4 "Axle not active because of an error adhesion steering" 3 "Axle centered because of an error" 2 "Axle centered" 1 "Axle steering active" 0 "Axle steering not active adhesion steering" ;
VAL_ 2633941758 TransOutputRetarder 3 "Not available" 2 "Error" 1 "On" 0 "Off" ;
VAL_ 2565865726 RetarderRoadSpeedExceededStatus 3 "Dont care/Take no action" 2 "Reserved" 1 "Road speed is above threshold and retarder is allowed to be activated" 0 "Road speed is below threshold" ;
VAL_ 2565865726 RetarderRoadSpeedLimitSwitch 3 "Not Available" 2 "Error Indicator" 1 "Road speed limiting by retarder is enabled The road speed that the retarder will limit will be determined when the" 0 "Road speed limiting by retarder is disabled" ;
VAL_ 2565865726 RetarderRequestingBrakeLight 3 "Not available/Take no action" 2 "Reserved" 1 "Retarder is requesting that the brake lights are illuminated" 0 "Retarder is not requesting that the brake lights are illuminated" ;
VAL_ 2565865726 EngCoolantLoadIncrease 3 "Not available" 2 "Error" 1 "Coolant load increase possible" 0 "No coolant load increase" ;
VAL_ 2565865726 RetarderEnableShiftAssistSwitch 3 "Not available" 2 "Error" 1 "Retarder  shift assist enabled" 0 "Retarder  shift assist disabled" ;
VAL_ 2565865726 RetarderEnableBrakeAssistSwitch 3 "Not available" 2 "Error" 1 "Retarder  brake assist enabled" 0 "Retarder  brake assist disabled" ;
VAL_ 2633935358 EngExhstGsOxygnSnsrClsdLpOprtion 3 "Dont Care/take no action" 2 "Reserved" 1 "Engine using the Exhaust Gas Oxygen sensor for a closed loop operation" 0 "Engine not using the Exhaust Gas Oxygen sensor open loop" ;
VAL_ 2365447166 Jystick3GripXAxisDetentPosStatus 3 "Not Available" 2 "Error Indicator" 1 "In the Detent Position" 0 "Not in the Detent Position" ;
VAL_ 2365447166 Jystick3GripYAxisDetentPosStatus 3 "Not Available" 2 "Error Indicator" 1 "In the Detent Position" 0 "Not in the Detent Position" ;
VAL_ 2365447166 Jystick3ThetaAxisDetentPosStatus 3 "Not Available" 2 "Error Indicator" 1 "In the Detent Position" 0 "Not in the Detent Position" ;
VAL_ 2365447166 Jystck3ThtAxsClckwsPstvPosStatus 3 "Not Available" 2 "Error Indicator" 1 "On positive side of Neutral" 0 "Not on Positive side of Neutral" ;
VAL_ 2365447166 Jystck3ThetaAxisNeutralPosStatus 3 "Not Available" 2 "Error Indicator" 1 "In Neutral Position" 0 "Not in Neutral Position" ;
VAL_ 2365447166 Jystck3GrpYAxsLvrFrwrdPstvPsStts 3 "Not Available" 2 "Error Indicator" 1 "On positive side of Neutral" 0 "Not on Positive side of Neutral" ;
VAL_ 2365447166 Jystck3GrpYAxsLvrBckNgtvPsStatus 3 "Not Available" 2 "Error Indicator" 1 "On negative side of Neutral" 0 "Not on negative side of Neutral" ;
VAL_ 2365447166 Jystck3GripYAxisNeutralPosStatus 3 "Not Available" 2 "Error Indicator" 1 "In Neutral Position" 0 "Not in Neutral Position" ;
VAL_ 2365447166 Jystck3GrpXAxsLvrRghtPstvPsSttus 3 "Not Available" 2 "Error Indicator" 1 "On positive side of Neutral" 0 "Not on Positive side of Neutral" ;
VAL_ 2365447166 Jystck3GrpXAxsLvrLftNgtvPsStatus 3 "Not Available" 2 "Error Indicator" 1 "On negative side of Neutral" 0 "Not on negative side of Neutral" ;
VAL_ 2365447166 Jystck3GripXAxisNeutralPosStatus 3 "Not Available" 2 "Error Indicator" 1 "On negative side of Neutral" 0 "Not on negative side of Neutral" ;
VAL_ 2365447166 Jystck3ThtAxsCntrClckwsNgtvPsStt 3 "Not Available" 2 "Error Indicator" 1 "On negative side of Neutral" 0 "Not on negative side of Neutral" ;
VAL_ 2365446654 Jystick2GripXAxisDetentPosStatus 3 "Not Available" 2 "Error Indicator" 1 "In the Detent Position" 0 "Not in the Detent Position" ;
VAL_ 2365446654 Jystick2GripYAxisDetentPosStatus 3 "Not Available" 2 "Error Indicator" 1 "In the Detent Position" 0 "Not in the Detent Position" ;
VAL_ 2365446654 Jystick2ThetaAxisDetentPosStatus 3 "Not Available" 2 "Error Indicator" 1 "In the Detent Position" 0 "Not in the Detent Position" ;
VAL_ 2365446654 Jystck2ThtAxsClckwsPstvPosStatus 3 "Not Available" 2 "Error Indicator" 1 "On positive side of Neutral" 0 "Not on Positive side of Neutral" ;
VAL_ 2365446654 Jystck2ThetaAxisNeutralPosStatus 3 "Not Available" 2 "Error Indicator" 1 "In Neutral Position" 0 "Not in Neutral Position" ;
VAL_ 2365446654 Jystck2GrpYAxsLvrFrwrdPstvPsStts 3 "Not Available" 2 "Error Indicator" 1 "On positive side of Neutral" 0 "Not on Positive side of Neutral" ;
VAL_ 2365446654 Jystck2GrpYAxsLvrBckNgtvPsStatus 3 "Not Available" 2 "Error Indicator" 1 "On negative side of Neutral" 0 "Not on negative side of Neutral" ;
VAL_ 2365446654 Jystck2GripYAxisNeutralPosStatus 3 "Not Available" 2 "Error Indicator" 1 "In Neutral Position" 0 "Not in Neutral Position" ;
VAL_ 2365446654 Jystck2GrpXAxsLvrRghtPstvPsSttus 3 "Not Available" 2 "Error Indicator" 1 "On positive side of Neutral" 0 "Not on Positive side of Neutral" ;
VAL_ 2365446654 Jystck2GrpXAxsLvrLftNgtvPsStatus 3 "Not Available" 2 "Error Indicator" 1 "On negative side of Neutral" 0 "Not on negative side of Neutral" ;
VAL_ 2365446654 Jystck2GripXAxisNeutralPosStatus 3 "Not Available" 2 "Error Indicator" 1 "On negative side of Neutral" 0 "Not on negative side of Neutral" ;
VAL_ 2365446654 Jystck2ThtAxsCntrClckwsNgtvPsStt 3 "Not Available" 2 "Error Indicator" 1 "On negative side of Neutral" 0 "Not on negative side of Neutral" ;
